VERSION ""

NS_ :

BS_:

BU_: TBOX GW

BO_ 945 TBOX_0x3B1: 8 TBOX
 SG_ TBOX_YawAngvelocity : 7|16@0+ (1,0) [0|65535] "度/秒" GW
 SG_ TBOX_PitchAngvelocity : 23|16@0+ (1,0) [0|65535] "度/秒" GW
 SG_ TBOX_RollAngvelocity : 39|16@0+ (1,0) [0|65535] "度/秒" GW

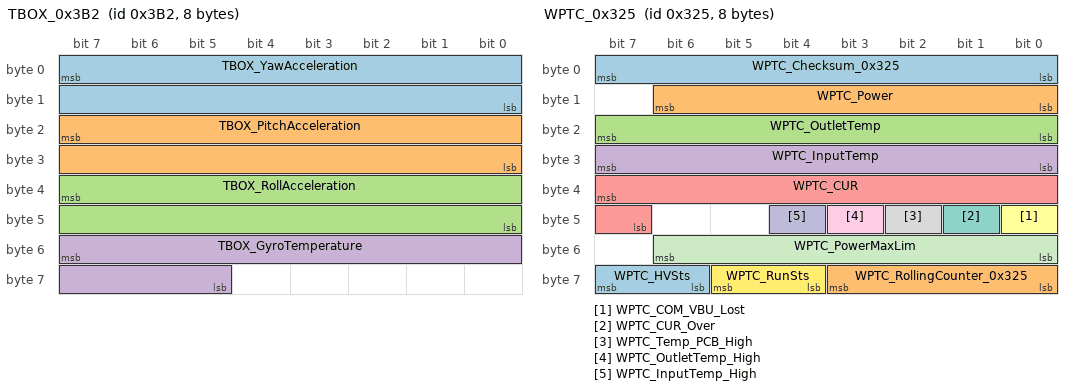
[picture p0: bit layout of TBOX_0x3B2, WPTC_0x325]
BO_ 946 TBOX_0x3B2: 8 TBOX
 SG_ TBOX_YawAcceleration : 7|16@0+ (1,0) [0|65535] "g" GW
 SG_ TBOX_PitchAcceleration : 23|16@0+ (1,0) [0|65535] "g" GW
 SG_ TBOX_RollAcceleration : 39|16@0+ (1,0) [0|65535] "g" GW
 SG_ TBOX_GyroTemperature : 55|11@0+ (0.1,-75) [-75|125] "℃" GW

BO_ 1378 MCU_0x562: 8 GW
 SG_ MCU_MotorSts_GBT : 7|8@0+ (1,0) [0|255] "" TBOX
 SG_ MCU_MotoroffsetCalReq : 34|1@0+ (1,0) [0|1] "" TBOX

BO_ 805 WPTC_0x325: 8 GW
 SG_ WPTC_Checksum_0x325 : 7|8@0+ (1,0) [0|255] "" TBOX
 SG_ WPTC_Power : 14|7@0+ (0.1,0) [0|12.7] "KW" TBOX
 SG_ WPTC_OutletTemp : 23|8@0+ (1,-40) [-40|215] "℃" TBOX
 SG_ WPTC_InputTemp : 31|8@0+ (1,-40) [-40|215] "℃" TBOX
 SG_ WPTC_CUR : 39|9@0+ (0.1,0) [0|40] "" TBOX
 SG_ WPTC_COM_VBU_Lost : 40|1@0+ (1,0) [0|1] "" TBOX
 SG_ WPTC_CUR_Over : 41|1@0+ (1,0) [0|1] "" TBOX
 SG_ WPTC_Temp_PCB_High : 42|1@0+ (1,0) [0|1] "" TBOX
 SG_ WPTC_OutletTemp_High : 43|1@0+ (1,0) [0|1] "" TBOX
 SG_ WPTC_InputTemp_High : 44|1@0+ (1,0) [0|1] "" TBOX
 SG_ WPTC_PowerMaxLim : 54|7@0+ (0.1,0) [0|12.7] "KW" TBOX
 SG_ WPTC_RunSts : 61|2@0+ (1,0) [0|3] "" TBOX
 SG_ WPTC_HVSts : 63|2@0+ (1,0) [0|3] "" TBOX
 SG_ WPTC_RollingCounter_0x325 : 59|4@0+ (1,0) [0|15] "" TBOX

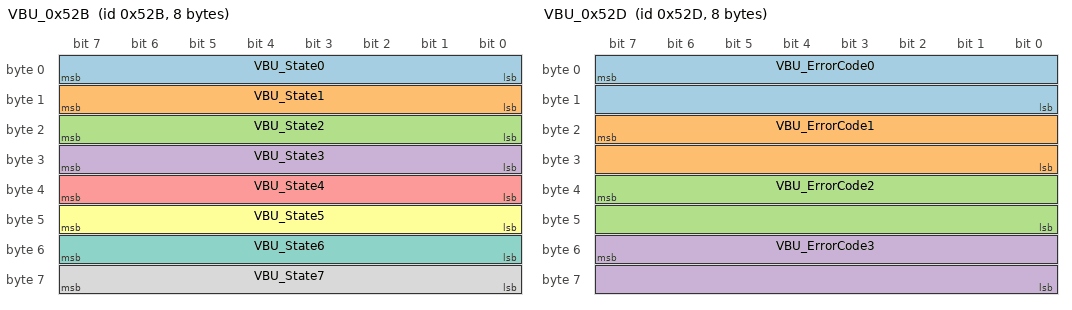
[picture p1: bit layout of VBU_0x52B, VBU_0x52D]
BO_ 1323 VBU_0x52B: 8 GW
 SG_ VBU_State0 : 7|8@0+ (1,0) [0|255] "" TBOX
 SG_ VBU_State1 : 15|8@0+ (1,0) [0|255] "" TBOX
 SG_ VBU_State2 : 23|8@0+ (1,0) [0|255] "" TBOX
 SG_ VBU_State3 : 31|8@0+ (1,0) [0|255] "" TBOX
 SG_ VBU_State4 : 39|8@0+ (1,0) [0|255] "" TBOX
 SG_ VBU_State5 : 47|8@0+ (1,0) [0|255] "" TBOX
 SG_ VBU_State6 : 55|8@0+ (1,0) [0|255] "" TBOX
 SG_ VBU_State7 : 63|8@0+ (1,0) [0|255] "" TBOX

BO_ 1325 VBU_0x52D: 8 GW
 SG_ VBU_ErrorCode0 : 7|16@0+ (1,0) [0|65536] "" TBOX
 SG_ VBU_ErrorCode1 : 23|16@0+ (1,0) [0|65536] "" TBOX
 SG_ VBU_ErrorCode2 : 39|16@0+ (1,0) [0|65536] "" TBOX
 SG_ VBU_ErrorCode3 : 55|16@0+ (1,0) [0|65536] "" TBOX

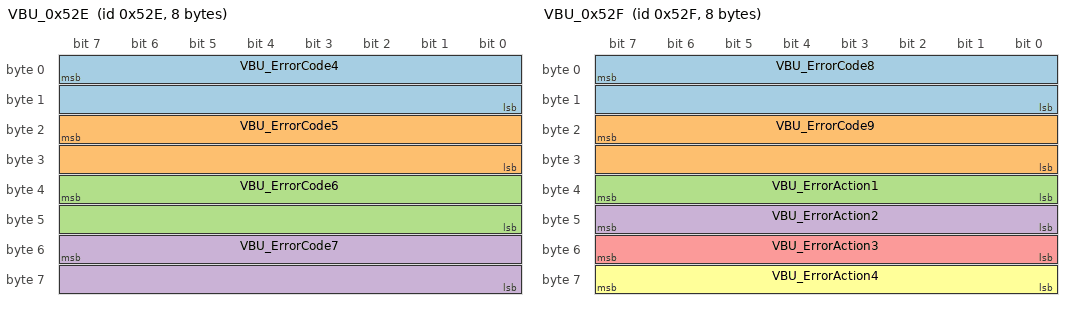
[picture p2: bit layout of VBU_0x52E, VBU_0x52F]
BO_ 1326 VBU_0x52E: 8 GW
 SG_ VBU_ErrorCode4 : 7|16@0+ (1,0) [0|65536] "" TBOX
 SG_ VBU_ErrorCode5 : 23|16@0+ (1,0) [0|65536] "" TBOX
 SG_ VBU_ErrorCode6 : 39|16@0+ (1,0) [0|65536] "" TBOX
 SG_ VBU_ErrorCode7 : 55|16@0+ (1,0) [0|65536] "" TBOX

BO_ 1327 VBU_0x52F: 8 GW
 SG_ VBU_ErrorCode8 : 7|16@0+ (1,0) [0|65536] "" TBOX
 SG_ VBU_ErrorCode9 : 23|16@0+ (1,0) [0|65536] "" TBOX
 SG_ VBU_ErrorAction1 : 39|8@0+ (1,0) [0|255] "" TBOX
 SG_ VBU_ErrorAction2 : 47|8@0+ (1,0) [0|255] "" TBOX
 SG_ VBU_ErrorAction3 : 55|8@0+ (1,0) [0|255] "" TBOX
 SG_ VBU_ErrorAction4 : 63|8@0+ (1,0) [0|255] "" TBOX

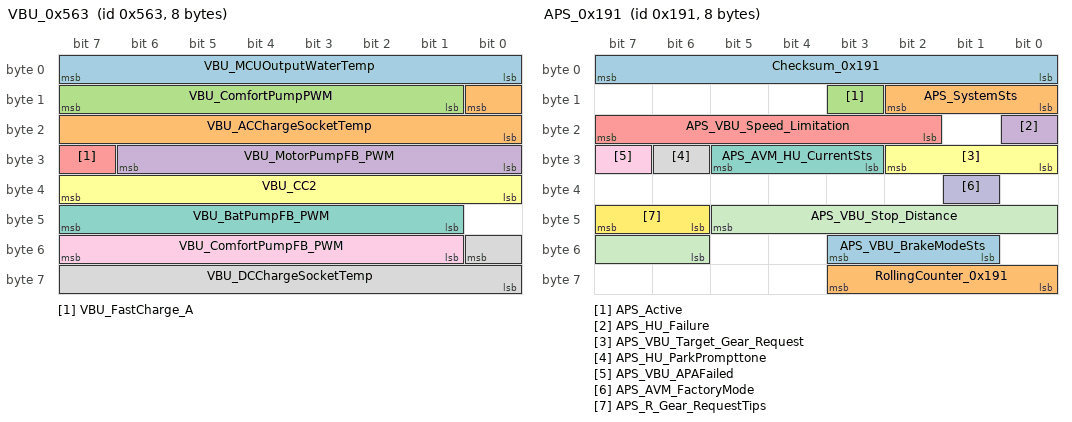
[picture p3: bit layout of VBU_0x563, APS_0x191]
BO_ 1379 VBU_0x563: 8 GW
 SG_ VBU_MCUOutputWaterTemp : 7|8@0+ (1,-40) [-40|215] "" TBOX
 SG_ VBU_ACChargeSocketTemp : 8|9@0+ (1,-40) [-40|300] "degC" TBOX
 SG_ VBU_ComfortPumpPWM : 15|7@0+ (1,0) [0|100] "%" TBOX
 SG_ VBU_MotorPumpFB_PWM : 30|7@0+ (1,0) [0|100] "%" TBOX
 SG_ VBU_FastCharge_A : 31|1@0+ (1,0) [0|1] "" TBOX
 SG_ VBU_CC2 : 39|8@0+ (0.1,0) [0|25.4] "V" TBOX
 SG_ VBU_BatPumpFB_PWM : 47|7@0+ (1,0) [0|100] "%" TBOX
 SG_ VBU_DCChargeSocketTemp : 48|9@0+ (1,-40) [-40|300] "degC" TBOX
 SG_ VBU_ComfortPumpFB_PWM : 55|7@0+ (1,0) [0|100] "%" TBOX

BO_ 401 APS_0x191: 8 GW
 SG_ Checksum_0x191 : 7|8@0+ (1,0) [0|255] "" TBOX
 SG_ APS_SystemSts : 10|3@0+ (1,0) [0|7] "" TBOX
 SG_ APS_Active : 11|1@0+ (1,0) [0|1] "" TBOX
 SG_ APS_HU_Failure : 16|1@0+ (1,0) [0|1] "" TBOX
 SG_ APS_VBU_Speed_Limitation : 23|6@0+ (0.8,0) [0|5] "kmph" TBOX
 SG_ APS_VBU_Target_Gear_Request : 26|3@0+ (1,0) [0|7] "" TBOX
 SG_ APS_AVM_HU_CurrentSts : 29|3@0+ (1,0) [0|7] "" TBOX
 SG_ APS_HU_ParkPrompttone : 30|1@0+ (1,0) [0|1] "" TBOX
 SG_ APS_VBU_APAFailed : 31|1@0+ (1,0) [0|1] "" TBOX
 SG_ APS_AVM_FactoryMode : 33|1@0+ (1,0) [0|1] "" TBOX
 SG_ APS_VBU_Stop_Distance : 45|8@0+ (1,0) [0|255] "" TBOX
 SG_ APS_R_Gear_RequestTips : 47|2@0+ (1,0) [0|3] "" TBOX
 SG_ APS_VBU_BrakeModeSts : 51|3@0+ (1,0) [0|7] "" TBOX
 SG_ RollingCounter_0x191 : 59|4@0+ (1,0) [0|15] "" TBOX

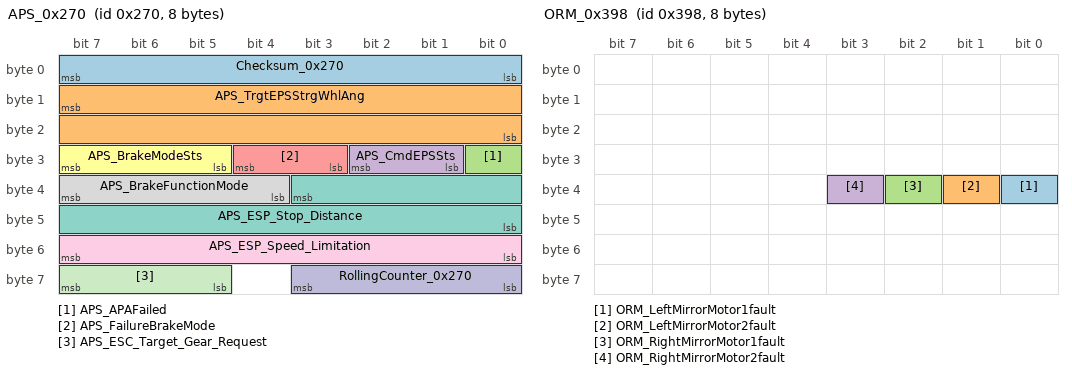
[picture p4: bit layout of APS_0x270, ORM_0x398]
BO_ 624 APS_0x270: 8 GW
 SG_ Checksum_0x270 : 7|8@0+ (1,0) [0|255] "" TBOX
 SG_ APS_TrgtEPSStrgWhlAng : 15|16@0+ (0.0238,-780) [-780|779.733] "deg" TBOX
 SG_ APS_APAFailed : 24|1@0+ (1,0) [0|1] "" TBOX
 SG_ APS_CmdEPSSts : 26|2@0+ (1,0) [0|3] "" TBOX
 SG_ APS_FailureBrakeMode : 28|2@0+ (1,0) [0|3] "" TBOX
 SG_ APS_BrakeModeSts : 31|3@0+ (1,0) [0|7] "" TBOX
 SG_ APS_ESP_Stop_Distance : 35|12@0+ (1,0) [0|4095] "cm" TBOX
 SG_ APS_BrakeFunctionMode : 39|4@0+ (1,0) [0|15] "" TBOX
 SG_ APS_ESP_Speed_Limitation : 55|8@0+ (0.1,0) [0|10] "Km/h" TBOX
 SG_ RollingCounter_0x270 : 59|4@0+ (1,0) [0|15] "" TBOX
 SG_ APS_ESC_Target_Gear_Request : 63|3@0+ (1,0) [0|7] "" TBOX

BO_ 625 APS_0x271: 8 GW
 SG_ Checksum_0x271 : 7|8@0+ (1,0) [0|255] "" TBOX
 SG_ APS_APS_AutoSearchSts : 10|3@0+ (1,0) [0|7] "" TBOX
 SG_ APS_APS_ParkOutChkResult : 11|1@0+ (1,0) [0|1] "" TBOX
 SG_ APS_APS_CurrentPathNum : 15|4@0+ (1,0) [0|15] "" TBOX
 SG_ APS_APS_TotalPathNum : 19|4@0+ (1,0) [0|15] "" TBOX
 SG_ APS_APS_SuspendedReason : 22|3@0+ (1,0) [0|7] "" TBOX
 SG_ APS_APS_AbortReason : 28|5@0+ (1,0) [0|31] "" TBOX
 SG_ APS_APS_CurrentParkType : 31|3@0+ (1,0) [0|7] "" TBOX
 SG_ APS_APS_OverrideReason : 34|3@0+ (1,0) [0|7] "" TBOX
 SG_ APS_APS_VehicleDirection : 36|2@0+ (1,0) [0|3] "" TBOX
 SG_ APS_APS_TerminatedType : 38|2@0+ (1,0) [0|3] "" TBOX
 SG_ APS_RemoteParkIn_Status : 46|3@0+ (1,0) [0|7] "" TBOX
 SG_ APS_BCM_RemoteParkIn_Status : 48|1@0+ (1,0) [0|1] "" TBOX
 SG_ APS_BCM_DoubleFlash : 49|1@0+ (1,0) [0|1] "" TBOX
 SG_ APS_BCM_AllDoorUnLock_Door : 50|1@0+ (1,0) [0|1] "" TBOX
 SG_ APS_BCM_PowerOffReq : 52|1@0+ (1,0) [0|1] "" TBOX
 SG_ RollingCounter_0x271 : 59|4@0+ (1,0) [0|15] "" TBOX
 SG_ APS_ParkDirection : 61|2@0+ (1,0) [0|3] "" TBOX
 SG_ APS_APP_RPA_Status : 63|2@0+ (1,0) [0|3] "" TBOX

BO_ 920 ORM_0x398: 8 GW
 SG_ ORM_LeftMirrorMotor1fault : 32|1@0+ (1,0) [0|1] "" TBOX
 SG_ ORM_LeftMirrorMotor2fault : 33|1@0+ (1,0) [0|1] "" TBOX
 SG_ ORM_RightMirrorMotor1fault : 34|1@0+ (1,0) [0|1] "" TBOX
 SG_ ORM_RightMirrorMotor2fault : 35|1@0+ (1,0) [0|1] "" TBOX

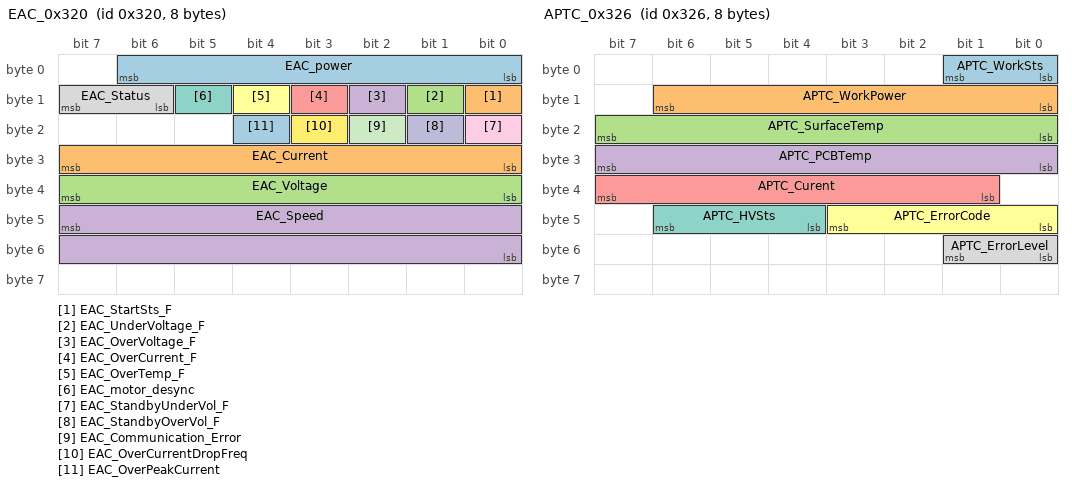
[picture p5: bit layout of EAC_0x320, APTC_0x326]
BO_ 800 EAC_0x320: 8 GW
 SG_ EAC_power : 6|7@0+ (0.1,0) [0|12.7] "KW" TBOX
 SG_ EAC_StartSts_F : 8|1@0+ (1,0) [0|1] "" TBOX
 SG_ EAC_UnderVoltage_F : 9|1@0+ (1,0) [0|1] "" TBOX
 SG_ EAC_OverVoltage_F : 10|1@0+ (1,0) [0|1] "" TBOX
 SG_ EAC_OverCurrent_F : 11|1@0+ (1,0) [0|1] "" TBOX
 SG_ EAC_OverTemp_F : 12|1@0+ (1,0) [0|1] "" TBOX
 SG_ EAC_motor_desync : 13|1@0+ (1,0) [0|1] "" TBOX
 SG_ EAC_Status : 15|2@0+ (1,0) [0|3] "" TBOX
 SG_ EAC_StandbyUnderVol_F : 16|1@0+ (1,0) [0|1] "" TBOX
 SG_ EAC_StandbyOverVol_F : 17|1@0+ (1,0) [0|1] "" TBOX
 SG_ EAC_Communication_Error : 18|1@0+ (1,0) [0|1] "" TBOX
 SG_ EAC_OverCurrentDropFreq : 19|1@0+ (1,0) [0|1] "" TBOX
 SG_ EAC_OverPeakCurrent : 20|1@0+ (1,0) [0|1] "" TBOX
 SG_ EAC_Current : 31|8@0+ (0.1,0) [0|25.4] "A" TBOX
 SG_ EAC_Voltage : 39|8@0+ (4,0) [0|1016] "V" TBOX
 SG_ EAC_Speed : 47|16@0+ (1,0) [0|65534] "RPM" TBOX

BO_ 806 APTC_0x326: 8 GW
 SG_ APTC_WorkSts : 1|2@0+ (1,0) [0|3] "" TBOX
 SG_ APTC_WorkPower : 14|7@0+ (0.1,0) [0|12.7] "KW" TBOX
 SG_ APTC_SurfaceTemp : 23|8@0+ (1,-40) [-40|215] "" TBOX
 SG_ APTC_PCBTemp : 31|8@0+ (1,-40) [-40|215] "" TBOX
 SG_ APTC_Curent : 39|7@0+ (0.2,0) [0|25] "" TBOX
 SG_ APTC_ErrorCode : 43|4@0+ (1,0) [0|15] "" TBOX
 SG_ APTC_HVSts : 46|3@0+ (1,0) [0|7] "" TBOX
 SG_ APTC_ErrorLevel : 49|2@0+ (1,0) [0|3] "" TBOX

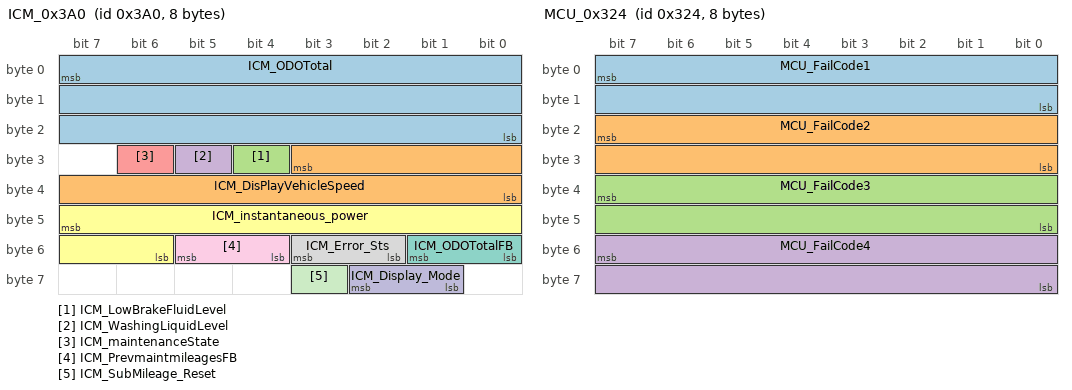
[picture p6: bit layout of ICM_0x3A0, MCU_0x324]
BO_ 928 ICM_0x3A0: 8 GW
 SG_ ICM_ODOTotal : 7|24@0+ (1,0) [0|999999] "KM" TBOX
 SG_ ICM_DisPlayVehicleSpeed : 27|12@0+ (0.05625,0) [0|230.28749] "kph" TBOX
 SG_ ICM_LowBrakeFluidLevel : 28|1@0+ (1,0) [0|1] "" TBOX
 SG_ ICM_WashingLiquidLevel : 29|1@0+ (1,0) [0|1] "" TBOX
 SG_ ICM_maintenanceState : 30|1@0+ (1,0) [0|1] "" TBOX
 SG_ ICM_instantaneous_power : 47|10@0+ (1,-400) [-400|400] "" TBOX
 SG_ ICM_ODOTotalFB : 49|2@0+ (1,0) [0|3] "" TBOX
 SG_ ICM_Error_Sts : 51|2@0+ (1,0) [0|3] "" TBOX
 SG_ ICM_PrevmaintmileagesFB : 53|2@0+ (1,0) [0|3] "" TBOX
 SG_ ICM_Display_Mode : 58|2@0+ (1,0) [0|3] "" TBOX
 SG_ ICM_SubMileage_Reset : 59|1@0+ (1,0) [0|1] "" TBOX

BO_ 896 BCM_0x380_LIN1: 8 GW
 SG_ RLS_RQ_LowBeam : 55|2@0+ (1,0) [0|3] "" TBOX
 SG_ RB_Hall_error : 16|1@0+ (1,0) [0|1] "" TBOX
 SG_ RB_Relay_error : 17|1@0+ (1,0) [0|1] "" TBOX
 SG_ RB_ResponseError : 18|1@0+ (1,0) [0|1] "" TBOX
 SG_ RB_RunningStatus : 20|2@0+ (1,0) [0|3] "" TBOX
 SG_ RB_Initialization_Status : 22|2@0+ (1,0) [0|1] "" TBOX
 SG_ RLS_Fault_Rain : 23|1@0+ (1,0) [0|1] "" TBOX
 SG_ RB_Position : 30|7@0+ (1,0) [0|127] "" TBOX
 SG_ RLS_Brightness_FW : 33|10@0+ (6,0) [0|6126] "LUX" TBOX
 SG_ RLS_Fault_Light : 34|1@0+ (1,0) [0|1] "" TBOX
 SG_ RLS_ResponseError : 35|1@0+ (1,0) [0|1] "" TBOX
 SG_ RLS_Rain_Intensity : 39|4@0+ (10,0) [0|100] "%" TBOX
 SG_ RB_Reversiering : 48|1@0+ (1,0) [0|1] "" TBOX
 SG_ RB_Thermalprotection : 49|1@0+ (1,0) [0|1] "" TBOX
 SG_ RB_UBat_LowVoltage : 50|1@0+ (1,0) [0|1] "" TBOX
 SG_ RB_UBat_OverVoltage : 51|1@0+ (1,0) [0|1] "" TBOX
 SG_ RB_OpenKey_Status : 52|1@0+ (1,0) [0|1] "" TBOX
 SG_ RB_CloseKey_Status : 53|1@0+ (1,0) [0|1] "" TBOX

BO_ 784 BCM_0x310: 8 GW
 SG_ BCM_SystemPowerMode : 1|2@0+ (1,0) [0|3] "" TBOX
 SG_ BCM_AntiThelf_Sts : 3|2@0+ (1,0) [0|3] "" TBOX
 SG_ BCM_DriverLock_Sts : 5|2@0+ (1,0) [0|3] "" TBOX
 SG_ BCM_StartRequest : 6|1@0+ (1,0) [0|1] "" TBOX
 SG_ BCM_partialarmed_ActiveSts : 7|1@0+ (1,0) [0|1] "" TBOX
 SG_ BCM_Hood_Sts : 9|2@0+ (1,0) [0|3] "" TBOX
 SG_ BCM_ChargerLock_ControlSts : 10|1@0+ (1,0) [0|1] "" TBOX
 SG_ BCM_PositionLight_Sts : 11|1@0+ (1,0) [0|1] "" TBOX
 SG_ BCM_TurnLeftLight_Sts : 12|1@0+ (1,0) [0|1] "" TBOX
 SG_ BCM_TurnRightLight_Sts : 13|1@0+ (1,0) [0|1] "" TBOX
 SG_ BCM_Daylight_Sts : 14|1@0+ (1,0) [0|1] "" TBOX
 SG_ BCM_HighBeam_Sts : 15|1@0+ (1,0) [0|1] "" TBOX
 SG_ BCM_LowBeam_Sts : 16|1@0+ (1,0) [0|1] "" TBOX
 SG_ BCM_AutoHeadlight_Sts : 17|1@0+ (1,0) [0|1] "" TBOX
 SG_ BCM_brakeLight_Sts : 18|1@0+ (1,0) [0|1] "" TBOX
 SG_ BCM_HazardLight_Sts : 19|1@0+ (1,0) [0|1] "" TBOX
 SG_ BCM_RearFoglight_Sts : 20|1@0+ (1,0) [0|1] "" TBOX
 SG_ BCM_BrkSw_Sts : 22|2@0+ (1,0) [0|3] "" TBOX
 SG_ BCM_FL_Door_Sts : 25|2@0+ (1,0) [0|3] "" TBOX
 SG_ BCM_FR_Door_Sts : 27|2@0+ (1,0) [0|3] "" TBOX
 SG_ BCM_RL_Door_Sts : 29|2@0+ (1,0) [0|3] "" TBOX
 SG_ BCM_RR_Door_Sts : 31|2@0+ (1,0) [0|3] "" TBOX
 SG_ BCM_Trunk_Door_Sts : 33|2@0+ (1,0) [0|3] "" TBOX
 SG_ BCM_PLGOutsideSW : 34|1@0+ (1,0) [0|1] "" TBOX
 SG_ BCM_HornControlsts : 35|1@0+ (1,0) [0|1] "" TBOX
 SG_ BCM_Fwiper_Mist_Sts : 36|1@0+ (1,0) [0|1] "" TBOX
 SG_ BCM_Fwiper_washing_Sts : 37|1@0+ (1,0) [0|1] "" TBOX
 SG_ BCM_FWiper_Sts : 42|3@0+ (1,0) [0|7] "" TBOX
 SG_ BCM_RWiper_Sts : 44|2@0+ (1,0) [0|3] "" TBOX
 SG_ BCM_RearViewFoldSts : 45|1@0+ (1,0) [0|1] "" TBOX
 SG_ BCM_RearViewAutoSWSts : 46|1@0+ (1,0) [0|1] "" TBOX
 SG_ BCM_RearViewHeatSts : 47|1@0+ (1,0) [0|1] "" TBOX
 SG_ BCM_WorkMode : 49|2@0+ (1,0) [0|3] "" TBOX
 SG_ BCM_TBOXUnlockEnableSts : 50|1@0+ (1,0) [0|1] "" TBOX
 SG_ BCM_FwiperServiceSWsts : 51|1@0+ (1,0) [0|1] "" TBOX
 SG_ BCM_SupplyVoltage : 63|8@0+ (0.1,0) [0|25.4] "" TBOX
 SG_ BCM_PowerONorOFF_Reason : 55|4@0+ (1,0) [0|15] "" TBOX

BO_ 665 BCM_0x299_LIN2_3: 8 GW
 SG_ FLWM_DenormalizeSt : 0|1@0+ (1,0) [0|1] "" TBOX
 SG_ FRWM_DenormalizeSt : 1|1@0+ (1,0) [0|1] "" TBOX
 SG_ RLWM_DenormalizeSt : 2|1@0+ (1,0) [0|1] "" TBOX
 SG_ RRWM_DenormalizeSt : 3|1@0+ (1,0) [0|1] "" TBOX
 SG_ CSW_Key_LiftGate : 5|2@0+ (1,0) [0|3] "" TBOX
 SG_ CSW_WindowLOCK : 7|2@0+ (1,0) [0|3] "" TBOX
 SG_ CSW_Key_FrontDefrost : 9|2@0+ (1,0) [0|3] "" TBOX
 SG_ RLWM_WindowLOCKSts : 10|1@0+ (1,0) [0|1] "" TBOX
 SG_ RRWM_WindowLOCKSts : 11|1@0+ (1,0) [0|1] "" TBOX
 SG_ ESCL_DiagError : 12|1@0+ (1,0) [0|1] "" TBOX
 SG_ ESCL_authentification_error : 13|1@0+ (1,0) [0|1] "" TBOX
 SG_ ESCL_unlock_status : 14|1@0+ (1,0) [0|1] "" TBOX
 SG_ ESCL_lock_status : 15|1@0+ (1,0) [0|1] "" TBOX
 SG_ FLWM_WinPstSt : 22|7@0+ (1,0) [0|100] "" TBOX
 SG_ FLWM_AntiPinchDetecte : 23|1@0+ (1,0) [0|1] "" TBOX
 SG_ FRWM_WinPstSt : 30|7@0+ (1,0) [0|100] "" TBOX
 SG_ FRWM_AntiPinchDetecte : 31|1@0+ (1,0) [0|1] "" TBOX
 SG_ RLWM_WinPstSt : 38|7@0+ (1,0) [0|100] "" TBOX
 SG_ RLWM_AntiPinchDetecte : 39|1@0+ (1,0) [0|1] "" TBOX
 SG_ RRWM_WinPstSt : 46|7@0+ (1,0) [0|100] "" TBOX
 SG_ RRWM_AntiPinchDetecte : 47|1@0+ (1,0) [0|1] "" TBOX
 SG_ FLWM_Opend : 48|1@0+ (1,0) [0|1] "" TBOX
 SG_ FLWM_Closed : 49|1@0+ (1,0) [0|1] "" TBOX
 SG_ FRWM_Opend : 50|1@0+ (1,0) [0|1] "" TBOX
 SG_ FRWM_Closed : 51|1@0+ (1,0) [0|1] "" TBOX
 SG_ RLWM_Opend : 52|1@0+ (1,0) [0|1] "" TBOX
 SG_ RLWM_Closed : 53|1@0+ (1,0) [0|1] "" TBOX
 SG_ RRWM_Opend : 54|1@0+ (1,0) [0|1] "" TBOX
 SG_ RRWM_Closed : 55|1@0+ (1,0) [0|1] "" TBOX
 SG_ FLWM_WinMoveSt : 57|2@0+ (1,0) [0|3] "" TBOX
 SG_ FRWM_WinMoveSt : 59|2@0+ (1,0) [0|3] "" TBOX
 SG_ RLWM_WinMoveSt : 61|2@0+ (1,0) [0|3] "" TBOX
 SG_ RRWM_WinMoveSt : 63|2@0+ (1,0) [0|3] "" TBOX

BO_ 583 BCM_0x247: 8 GW
 SG_ BCM_StartWarning : 2|3@0+ (1,0) [0|7] "" TBOX
 SG_ BCM_PowerOffWarning : 6|3@0+ (1,0) [0|7] "" TBOX
 SG_ BCM_PowerONWarning : 10|3@0+ (1,0) [0|7] "" TBOX
 SG_ BCM_AuthSts : 14|2@0+ (1,0) [0|3] "" TBOX
 SG_ BCM_ESCLSysFail : 19|2@0+ (1,0) [0|3] "" TBOX
 SG_ BCM_LODO_Reminder : 23|2@0+ (1,0) [0|3] "" TBOX
 SG_ BCM_brakeLightfail : 25|2@0+ (1,0) [0|3] "" TBOX
 SG_ BCM_HoodOpen_Feedback : 31|1@0+ (1,0) [0|1] "" TBOX
 SG_ BCM_TrunkOpen_Feedback : 30|1@0+ (1,0) [0|1] "" TBOX
 SG_ BCM_Drivedoorlcok_Feedback : 29|1@0+ (1,0) [0|1] "" TBOX
 SG_ BCM_FLDoorOpen_Feedback : 39|1@0+ (1,0) [0|1] "" TBOX
 SG_ BCM_FRDoorOpen_Feedback : 38|1@0+ (1,0) [0|1] "" TBOX
 SG_ BCM_RRDoorOpen_Feedback : 37|1@0+ (1,0) [0|1] "" TBOX
 SG_ BCM_RLDoorOpen_Feedback : 36|1@0+ (1,0) [0|1] "" TBOX
 SG_ BCM_FLWindowOpen_Feedback : 35|1@0+ (1,0) [0|1] "" TBOX
 SG_ BCM_FRWindowOpen_Feedback : 34|1@0+ (1,0) [0|1] "" TBOX
 SG_ BCM_RRWindowOpen_Feedback : 33|1@0+ (1,0) [0|1] "" TBOX
 SG_ BCM_RLWindowOpen_Feedback : 32|1@0+ (1,0) [0|1] "" TBOX

BO_ 1282 BCM_TPMS_0x502: 8 GW
 SG_ TPMS_FL_Warning_Sts : 0|1@0+ (1,0) [0|1] "" TBOX
 SG_ TPMS_FR_Warning_Sts : 1|1@0+ (1,0) [0|1] "" TBOX
 SG_ TPMS_RL_Warning_Sts : 2|1@0+ (1,0) [0|1] "" TBOX
 SG_ TPMS_RR_Warning_Sts : 3|1@0+ (1,0) [0|1] "" TBOX
 SG_ TPMS_FL_Fault_Sts : 4|1@0+ (1,0) [0|1] "" TBOX
 SG_ TPMS_FR_Fault_Sts : 5|1@0+ (1,0) [0|1] "" TBOX
 SG_ TPMS_RL_Fault_Sts : 6|1@0+ (1,0) [0|1] "" TBOX
 SG_ TPMS_RR_Fault_Sts : 7|1@0+ (1,0) [0|1] "" TBOX
 SG_ TPMS_FL_leakage_Sts : 8|1@0+ (1,0) [0|1] "" TBOX
 SG_ TPMS_FR_leakage_Sts : 9|1@0+ (1,0) [0|1] "" TBOX
 SG_ TPMS_RL_leakage_Sts : 10|1@0+ (1,0) [0|1] "" TBOX
 SG_ TPMS_RR_leakage_Sts : 11|1@0+ (1,0) [0|1] "" TBOX
 SG_ TPMS_FLPressure_Sts : 13|2@0+ (1,0) [0|3] "" TBOX
 SG_ TPMS_FRPressure_Sts : 15|2@0+ (1,0) [0|3] "" TBOX
 SG_ TPMS_RLPressure_Sts : 17|2@0+ (1,0) [0|3] "" TBOX
 SG_ TPMS_RRPressure_Sts : 19|2@0+ (1,0) [0|3] "" TBOX
 SG_ TPMS_FL_HighTemp_Sts : 20|1@0+ (1,0) [0|1] "" TBOX
 SG_ TPMS_FR_HighTemp_Sts : 21|1@0+ (1,0) [0|1] "" TBOX
 SG_ TPMS_RL_HighTemp_Sts : 22|1@0+ (1,0) [0|1] "" TBOX
 SG_ TPMS_RR_HighTemp_Sts : 23|1@0+ (1,0) [0|1] "" TBOX
 SG_ TPMS_FL_battery_Sts : 24|1@0+ (1,0) [0|1] "" TBOX
 SG_ TPMS_FR_battery_Sts : 25|1@0+ (1,0) [0|1] "" TBOX
 SG_ TPMS_RL_battery_Sts : 26|1@0+ (1,0) [0|1] "" TBOX
 SG_ TPMS_RR_battery_Sts : 27|1@0+ (1,0) [0|1] "" TBOX
 SG_ TPMS_FL_SensorError_Sts : 28|1@0+ (1,0) [0|1] "" TBOX
 SG_ TPMS_FR_SensorError_Sts : 29|1@0+ (1,0) [0|1] "" TBOX
 SG_ TPMS_RL_SensorError_Sts : 30|1@0+ (1,0) [0|1] "" TBOX
 SG_ TPMS_RR_SensorError_Sts : 31|1@0+ (1,0) [0|1] "" TBOX
 SG_ TPMS_FL_failure_Sts : 32|1@0+ (1,0) [0|1] "" TBOX
 SG_ TPMS_FR_failure_Sts : 33|1@0+ (1,0) [0|1] "" TBOX
 SG_ TPMS_RL_failure_Sts : 34|1@0+ (1,0) [0|1] "" TBOX
 SG_ TPMS_RR_failure_Sts : 35|1@0+ (1,0) [0|1] "" TBOX
 SG_ TPMS_FL_learn_Sts : 41|2@0+ (1,0) [0|3] "" TBOX
 SG_ TPMS_FR_learn_Sts : 43|2@0+ (1,0) [0|3] "" TBOX
 SG_ TPMS_RL_learn_Sts : 45|2@0+ (1,0) [0|3] "" TBOX
 SG_ TPMS_RR_learn_Sts : 47|2@0+ (1,0) [0|3] "" TBOX
 SG_ TPMS_FL_CRC_Error : 48|1@0+ (1,0) [0|1] "" TBOX
 SG_ TPMS_FR_CRC_Error : 49|1@0+ (1,0) [0|1] "" TBOX
 SG_ TPMS_RL_CRC_Error : 50|1@0+ (1,0) [0|1] "" TBOX
 SG_ TPMS_RR_CRC_Error : 52|1@0+ (1,0) [0|1] "" TBOX

BO_ 804 MCU_0x324: 8 GW
 SG_ MCU_FailCode1 : 7|16@0+ (1,0) [0|65535] "" TBOX
 SG_ MCU_FailCode2 : 23|16@0+ (1,0) [0|65535] "" TBOX
 SG_ MCU_FailCode3 : 39|16@0+ (1,0) [0|65535] "" TBOX
 SG_ MCU_FailCode4 : 55|16@0+ (1,0) [0|65535] "" TBOX

BO_ 835 PLG_0x343: 8 GW
 SG_ PLG_Trunk_Sts : 2|3@0+ (1,0) [0|7] "" TBOX
 SG_ PLG_Shutface_SW : 3|1@0+ (1,0) [0|1] "" TBOX
 SG_ PLG_Latc_PawlSW : 4|1@0+ (1,0) [0|1] "" TBOX
 SG_ PLG_Latch_SecondarySW : 5|1@0+ (1,0) [0|1] "" TBOX
 SG_ PLG_Latch_0PositionSW : 6|1@0+ (1,0) [0|1] "" TBOX
 SG_ PLG_LearnedSts : 7|1@0+ (1,0) [0|1] "" TBOX
 SG_ PLG_KickActiveReq : 8|1@0+ (1,0) [0|1] "" TBOX
 SG_ PLG_HallSensor : 12|1@0+ (1,0) [0|1] "" TBOX
 SG_ PLG_OpenAng : 22|7@0+ (1,0) [0|100] "%" TBOX
 SG_ PLG_OpenAngValid : 23|1@0+ (1,0) [0|1] "" TBOX
 SG_ PLG_GaragePosition : 30|7@0+ (1,0) [0|100] "%" TBOX
 SG_ PLG_LatchMorSts : 33|2@0+ (1,0) [0|3] "" TBOX
 SG_ PLG_GearMor1Sts : 35|2@0+ (1,0) [0|3] "" TBOX
 SG_ PLG_GearMor2Sts : 37|2@0+ (1,0) [0|3] "" TBOX
 SG_ PLG_mode : 39|2@0+ (1,0) [0|3] "" TBOX
 SG_ PLG_TBOXUnlockEnableSts : 40|1@0+ (1,0) [0|1] "" TBOX
 SG_ PLG_Fault : 41|1@0+ (1,0) [0|1] "" TBOX
 SG_ PLG_FaultSts : 44|3@0+ (1,0) [0|7] "" TBOX

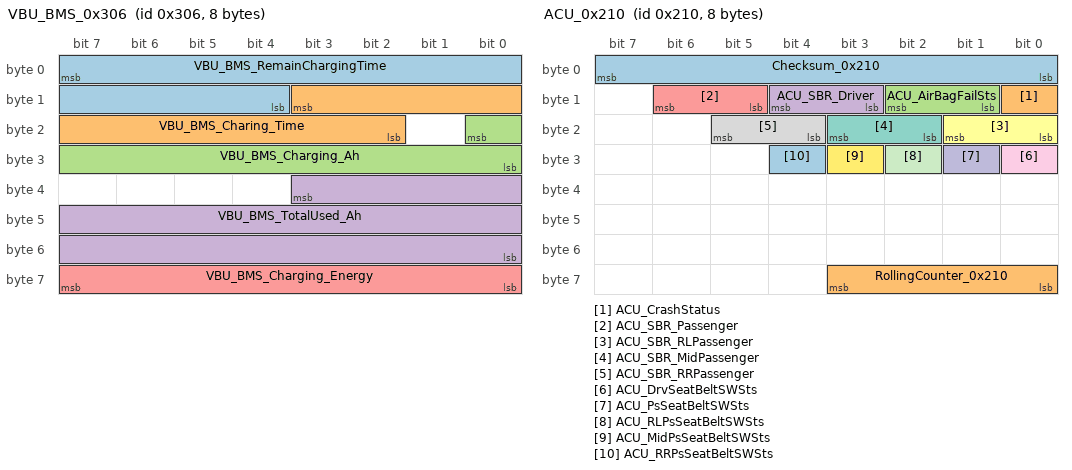
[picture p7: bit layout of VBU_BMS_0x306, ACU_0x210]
BO_ 774 VBU_BMS_0x306: 8 GW
 SG_ VBU_BMS_RemainChargingTime : 7|12@0+ (1,0) [0|2880] "min" TBOX
 SG_ VBU_BMS_Charing_Time : 11|10@0+ (1,0) [0|1000] "min" TBOX
 SG_ VBU_BMS_Charging_Ah : 16|9@0+ (0.5,0) [0|250] "Ah" TBOX
 SG_ VBU_BMS_TotalUsed_Ah : 35|20@0+ (1,0) [0|500000] "Ah" TBOX
 SG_ VBU_BMS_Charging_Energy : 63|8@0+ (0.5,0) [0|125] "kwh" TBOX

BO_ 528 ACU_0x210: 8 GW
 SG_ Checksum_0x210 : 7|8@0+ (1,0) [0|255] "" TBOX
 SG_ ACU_CrashStatus : 8|1@0+ (1,0) [0|1] "" TBOX
 SG_ ACU_AirBagFailSts : 10|2@0+ (1,0) [0|3] "" TBOX
 SG_ ACU_SBR_Driver : 12|2@0+ (1,0) [0|3] "" TBOX
 SG_ ACU_SBR_Passenger : 14|2@0+ (1,0) [0|3] "" TBOX
 SG_ ACU_SBR_RLPassenger : 17|2@0+ (1,0) [0|3] "" TBOX
 SG_ ACU_SBR_MidPassenger : 19|2@0+ (1,0) [0|3] "" TBOX
 SG_ ACU_SBR_RRPassenger : 21|2@0+ (1,0) [0|3] "" TBOX
 SG_ ACU_DrvSeatBeltSWSts : 24|1@0+ (1,0) [0|1] "" TBOX
 SG_ ACU_PsSeatBeltSWSts : 25|1@0+ (1,0) [0|1] "" TBOX
 SG_ ACU_RLPsSeatBeltSWSts : 26|1@0+ (1,0) [0|1] "" TBOX
 SG_ ACU_MidPsSeatBeltSWSts : 27|1@0+ (1,0) [0|1] "" TBOX
 SG_ ACU_RRPsSeatBeltSWSts : 28|1@0+ (1,0) [0|1] "" TBOX
 SG_ RollingCounter_0x210 : 59|4@0+ (1,0) [0|15] "" TBOX

BO_ 596 AC_0x254: 8 GW
 SG_ AC_SystemSts : 0|1@0+ (1,0) [0|1] "" TBOX
 SG_ AC_CycleSts : 1|1@0+ (1,0) [0|1] "" TBOX
 SG_ AC_EACSts : 2|1@0+ (1,0) [0|1] "" TBOX
 SG_ AC_AutoModeSts : 3|1@0+ (1,0) [0|1] "" TBOX
 SG_ AC_APTC_StartStop : 5|2@0+ (1,0) [0|3] "" TBOX
 SG_ AC_StartStopEAC : 7|2@0+ (1,0) [0|3] "" TBOX
 SG_ AC_EAC_AimSpeed : 15|16@0+ (1,0) [0|65534] "" TBOX
 SG_ AC_WindModeSts : 26|3@0+ (1,0) [0|7] "" TBOX
 SG_ AC_BlowingRateSts : 29|3@0+ (1,0) [0|7] "" TBOX
 SG_ AC_APTCSWsts : 30|1@0+ (1,0) [0|1] "" TBOX
 SG_ AC_SysFaultsts : 31|1@0+ (1,0) [0|1] "" TBOX
 SG_ AC_InTemperature : 39|8@0+ (0.5,-40) [-40|80] "℃" TBOX
 SG_ AC_OutTemperature : 47|8@0+ (0.5,-40) [-40|80] "℃" TBOX
 SG_ AC_PM25Value : 55|10@0+ (1,0) [0|1023] "μg/m3" TBOX
 SG_ AC_BatCoolingValve : 56|1@0+ (1,0) [0|1] "" TBOX
 SG_ AC_ComftCoolingValve : 57|1@0+ (1,0) [0|1] "" TBOX
 SG_ AC_FdefrostSts : 58|1@0+ (1,0) [0|1] "" TBOX

BO_ 1009 DVR_0x3F1: 8 GW
 SG_ DVR_Sdcard_Sts : 2|3@0+ (1,0) [0|7] "" TBOX
 SG_ DVR_DrivingRecord : 3|1@0+ (1,0) [0|1] "" TBOX
 SG_ DVR_VideoResolution : 5|2@0+ (1,0) [0|3] "" TBOX
 SG_ DVR_VideoTimeSts : 7|2@0+ (1,0) [0|3] "" TBOX
 SG_ DVR_ShutdownDelay : 9|2@0+ (1,0) [0|3] "" TBOX
 SG_ DVR_VideoCoverageSW : 10|1@0+ (1,0) [0|1] "" TBOX
 SG_ DVR_GSensorSensy : 12|2@0+ (1,0) [0|3] "" TBOX
 SG_ DVR_ParkMonitor : 13|1@0+ (1,0) [0|1] "" TBOX
 SG_ DVR_TapeSwitch : 14|1@0+ (1,0) [0|1] "" TBOX
 SG_ DVR_HDRSwitch : 15|1@0+ (1,0) [0|1] "" TBOX
 SG_ DVR_DriveInfoOverlay : 16|1@0+ (1,0) [0|1] "" TBOX
 SG_ DVR_SdcardFormateSts : 18|2@0+ (1,0) [0|3] "" TBOX
 SG_ DVR_FactoryDefaultSts : 20|2@0+ (1,0) [0|3] "" TBOX
 SG_ DVR_SystemSts : 21|1@0+ (1,0) [0|1] "" TBOX
 SG_ DVR_ControlResult : 23|2@0+ (1,0) [0|3] "" TBOX
 SG_ DVR_GsensorCrashStatus : 24|1@0+ (1,0) [0|1] "" TBOX
 SG_ DVR_requestWiFiopen : 25|1@0+ (1,0) [0|1] "" TBOX
 SG_ DVR_LocalTimelapseRecordResult : 57|2@0+ (1,0) [0|3] "" TBOX
 SG_ DVR_Frameinterval : 39|8@0+ (1,0) [0|255] "" TBOX
 SG_ DVR_FrameCount : 42|11@0+ (1,0) [0|2047] "" TBOX
 SG_ DVR_PlayRate : 47|5@0+ (1,0) [0|31] "" TBOX
 SG_ DVR_RemoteControlSts : 58|1@0+ (1,0) [0|1] "" TBOX

BO_ 676 DSM_0x2A4: 8 GW
 SG_ DSM_EasyEntrySWSts : 0|1@0+ (1,0) [0|1] "" TBOX
 SG_ DSM_DSMHeatSWsts : 1|1@0+ (1,0) [0|1] "" TBOX
 SG_ DSM_GetMemoryRsp_Mirror : 5|2@0+ (1,0) [0|3] "" TBOX
 SG_ DSM_GetMemoryRsp_Seat : 7|2@0+ (1,0) [0|3] "" TBOX
 SG_ DSM_SLV_DirectionSts : 13|2@0+ (1,0) [0|3] "" TBOX
 SG_ DSM_SHV_DirectionSts : 15|2@0+ (1,0) [0|3] "" TBOX
 SG_ DSM_LNV_DirectionSts : 17|2@0+ (1,0) [0|3] "" TBOX
 SG_ DSM_SLV_CalibrationSts : 19|2@0+ (1,0) [0|3] "" TBOX
 SG_ DSM_SHV_CalibrationSts : 21|2@0+ (1,0) [0|3] "" TBOX
 SG_ DSM_LNV_CalibrationSts : 23|2@0+ (1,0) [0|3] "" TBOX
 SG_ DSM_DSLV_MotorfaultSts : 24|1@0+ (1,0) [0|1] "" TBOX
 SG_ DSM_SLV_Position : 31|7@0+ (1,0) [0|100] "%" TBOX
 SG_ DSM_DSHV_MotorfaultSts : 32|1@0+ (1,0) [0|1] "" TBOX
 SG_ DSM_SHV_Position : 39|7@0+ (1,0) [0|100] "%" TBOX
 SG_ DSM_DSNV_MotorfaultSts : 40|1@0+ (1,0) [0|1] "" TBOX
 SG_ DSM_LNV_Position : 47|7@0+ (1,0) [0|100] "%" TBOX
 SG_ DSM_PSMHeatfault : 48|1@0+ (1,0) [0|1] "" TBOX
 SG_ DSM_PSMHeatSWsts : 49|1@0+ (1,0) [0|1] "" TBOX
 SG_ DSM_PSMheattemp : 55|6@0+ (1,0) [34|42] "℃" TBOX
 SG_ DSM_DSMHeatfault : 56|1@0+ (1,0) [0|1] "" TBOX
 SG_ DSM_DSMheattemp : 63|6@0+ (1,0) [34|42] "℃" TBOX

BO_ 24 BCM_AuthReq_0x18: 8 GW
 SG_ BCM_AuthReq_TBOX_NSM_Code : 7|64@0+ (1,0) [0|255] "" TBOX

BO_ 25 TBOX_AuthResp_0x19: 8 TBOX
 SG_ TBOX_AuthResp_BCM_Code : 7|64@0+ (1,0) [0|255] "" GW

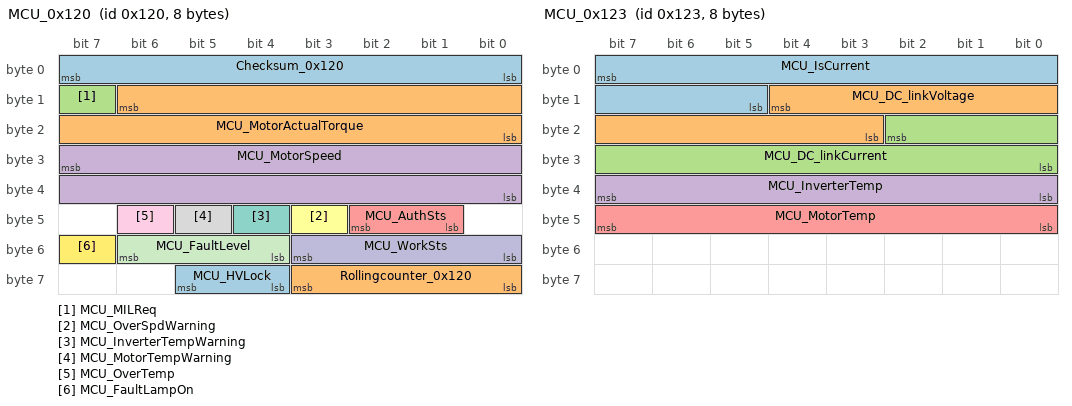
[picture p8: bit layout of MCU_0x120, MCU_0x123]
BO_ 288 MCU_0x120: 8 GW
 SG_ Checksum_0x120 : 7|8@0+ (1,0) [0|255] "" TBOX
 SG_ MCU_MotorActualTorque : 14|15@0+ (0.1,-1000) [-1000|1000] "NM" TBOX
 SG_ MCU_MILReq : 15|1@0+ (1,0) [0|1] "" TBOX
 SG_ MCU_MotorSpeed : 31|16@0+ (1,-32767) [-32767|32768] "RPM" TBOX
 SG_ MCU_AuthSts : 42|2@0+ (1,0) [0|3] "" TBOX
 SG_ MCU_OverSpdWarning : 43|1@0+ (1,0) [0|1] "" TBOX
 SG_ MCU_InverterTempWarning : 44|1@0+ (1,0) [0|1] "" TBOX
 SG_ MCU_MotorTempWarning : 45|1@0+ (1,0) [0|1] "" TBOX
 SG_ MCU_OverTemp : 46|1@0+ (1,0) [0|1] "" TBOX
 SG_ MCU_WorkSts : 51|4@0+ (1,0) [0|15] "" TBOX
 SG_ MCU_FaultLevel : 54|3@0+ (1,0) [0|7] "" TBOX
 SG_ MCU_FaultLampOn : 55|1@0+ (1,0) [0|1] "" TBOX
 SG_ MCU_HVLock : 61|2@0+ (1,0) [0|3] "" TBOX
 SG_ Rollingcounter_0x120 : 59|4@0+ (1,0) [0|15] "" TBOX

BO_ 290 MCU_0x122: 8 GW
 SG_ Checksum_0x122 : 7|8@0+ (1,0) [0|255] "" TBOX
 SG_ MCU_MaxAvailableTorque : 15|11@0+ (1,-1023) [-1023|1024] "NM" TBOX
 SG_ MCU_MinAvailableTorque : 18|11@0+ (1,-1023) [-1023|1024] "NM" TBOX
 SG_ MCU_DeratingTempCoolant : 35|1@0+ (1,0) [0|1] "" TBOX
 SG_ MCU_damping_En : 20|2@0+ (1,0) [0|3] "" TBOX
 SG_ MCU_DeratingTrqMin : 40|1@0+ (1,0) [0|1] "" TBOX
 SG_ MCU_DeratingTrqMax : 41|1@0+ (1,0) [0|1] "" TBOX
 SG_ MCU_DeratingOvrUdc : 42|1@0+ (1,0) [0|1] "" TBOX
 SG_ MCU_DeratingUndrUdc : 43|1@0+ (1,0) [0|1] "" TBOX
 SG_ MCU_DeratingOvrIdc : 44|1@0+ (1,0) [0|1] "" TBOX
 SG_ MCU_DeratingUndrIdc : 45|1@0+ (1,0) [0|1] "" TBOX
 SG_ MCU_DeratingTempEm : 46|1@0+ (1,0) [0|1] "" TBOX
 SG_ MCU_DeratingTempInv : 47|1@0+ (1,0) [0|1] "" TBOX
 SG_ Rollingcounter_0x122 : 59|4@0+ (1,0) [0|15] "" TBOX
 SG_ MCU_MotorTorDerLampReq : 61|1@0+ (1,0) [0|1] "" TBOX
 SG_ MCU_HVReady : 62|1@0+ (1,0) [0|1] "" TBOX
 SG_ MCU_DeratingOverSpd : 63|1@0+ (1,0) [0|1] "" TBOX

BO_ 289 ESP_0x121: 8 GW
 SG_ Checksum_0x121 : 7|8@0+ (1,0) [0|255] "" TBOX
 SG_ ESP_VehicleSpeed : 11|12@0+ (0.05625,0) [0|230.28749] "kph" TBOX
 SG_ ESP_VehicleSpeed_Valid : 12|1@0+ (1,0) [0|1] "" TBOX
 SG_ ESP_OFF : 13|1@0+ (1,0) [0|1] "" TBOX
 SG_ ESP_ABS_Error : 14|1@0+ (1,0) [0|1] "" TBOX
 SG_ ESP_ABS_Intervention : 15|1@0+ (1,0) [0|1] "" TBOX
 SG_ ESP_VDC_TCS_Error : 24|1@0+ (1,0) [0|1] "" TBOX
 SG_ ESP_EBD_Error : 25|1@0+ (1,0) [0|1] "" TBOX
 SG_ ESP_VDC_Intervention : 26|1@0+ (1,0) [0|1] "" TBOX
 SG_ ESP_TCS_Intervention : 27|1@0+ (1,0) [0|1] "" TBOX
 SG_ ESP_EBD_Intervention : 28|1@0+ (1,0) [0|1] "" TBOX
 SG_ ESP_HDC_Status : 31|2@0+ (1,0) [0|3] "" TBOX
 SG_ ESP_HDC_Available : 32|1@0+ (1,0) [0|1] "" TBOX
 SG_ ESP_EPBMainteDiagmodeActive : 33|1@0+ (1,0) [0|1] "" TBOX
 SG_ ESP_EPBFailstatus : 34|1@0+ (1,0) [0|1] "" TBOX
 SG_ ESP_EPBStatus : 37|3@0+ (1,0) [0|7] "" TBOX
 SG_ ESP_VehicleStop : 38|1@0+ (1,0) [0|1] "" TBOX
 SG_ ESP_VehicleStop_Valid : 39|1@0+ (1,0) [0|1] "" TBOX
 SG_ ESP_MasterCyPressureCmp : 47|8@0+ (1,0) [0|255] "bar" TBOX
 SG_ ESP_MasterCyPressure_Valid : 48|1@0+ (1,0) [0|1] "" TBOX
 SG_ ESP_WheelCyBrakeForce_Exist : 49|1@0+ (1,0) [0|1] "" TBOX
 SG_ ESP_ESPLamp : 50|1@0+ (1,0) [0|1] "" TBOX
 SG_ ESP_AVHstandbyStatus : 51|1@0+ (1,0) [0|1] "" TBOX
 SG_ ESP_AVHActive : 52|1@0+ (1,0) [0|1] "" TBOX
 SG_ ESP_AVH_availalbe : 53|1@0+ (1,0) [0|1] "" TBOX
 SG_ ESP_HHC_Available : 54|1@0+ (1,0) [0|1] "" TBOX
 SG_ ESP_HHCActive : 55|1@0+ (1,0) [0|1] "" TBOX
 SG_ RollingCounter_0x121 : 59|4@0+ (1,0) [0|15] "" TBOX
 SG_ ESP_HubDiagmodeActive : 60|1@0+ (1,0) [0|1] "" TBOX
 SG_ ESP_HAZ_Active : 61|1@0+ (1,0) [0|1] "" TBOX

BO_ 291 MCU_0x123: 8 GW
 SG_ MCU_IsCurrent : 7|11@0+ (0.5,0) [0|1023.5] "" TBOX
 SG_ MCU_DC_linkVoltage : 12|10@0+ (1,0) [0|1023] "V" TBOX
 SG_ MCU_DC_linkCurrent : 18|11@0+ (1,-1023) [-1023|1024] "A" TBOX
 SG_ MCU_InverterTemp : 39|8@0+ (1,-40) [-40|215] "℃" TBOX
 SG_ MCU_MotorTemp : 47|8@0+ (1,-40) [-40|215] "℃" TBOX

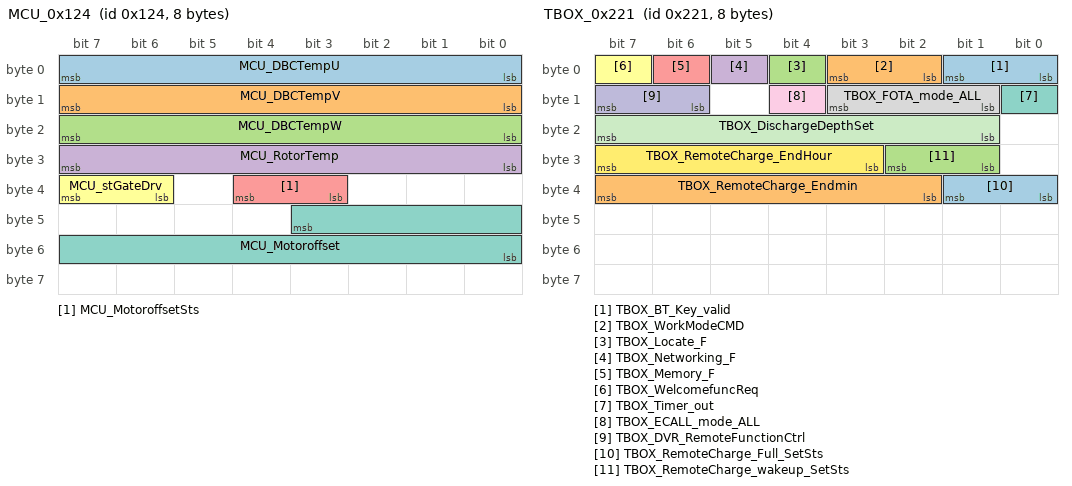
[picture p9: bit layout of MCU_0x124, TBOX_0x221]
BO_ 292 MCU_0x124: 8 GW
 SG_ MCU_DBCTempU : 7|8@0+ (1,-40) [-40|215] "degC" TBOX
 SG_ MCU_DBCTempV : 15|8@0+ (1,-40) [-40|215] "degC" TBOX
 SG_ MCU_DBCTempW : 23|8@0+ (1,-40) [-40|215] "degC" TBOX
 SG_ MCU_RotorTemp : 31|8@0+ (1,-40) [-40|215] "℃" TBOX
 SG_ MCU_MotoroffsetSts : 36|2@0+ (1,0) [0|3] "" TBOX
 SG_ MCU_stGateDrv : 39|2@0+ (1,0) [0|3] "" TBOX
 SG_ MCU_Motoroffset : 43|12@0+ (0.0878906,0) [0|359.9120178] "度" TBOX

BO_ 545 TBOX_0x221: 8 TBOX
 SG_ TBOX_BT_Key_valid : 1|2@0+ (1,0) [0|3] "" GW
 SG_ TBOX_WorkModeCMD : 3|2@0+ (1,0) [0|3] "" GW
 SG_ TBOX_Locate_F : 4|1@0+ (1,0) [0|1] "" GW
 SG_ TBOX_Networking_F : 5|1@0+ (1,0) [0|1] "" GW
 SG_ TBOX_Memory_F : 6|1@0+ (1,0) [0|1] "" GW
 SG_ TBOX_WelcomefuncReq : 7|1@0+ (1,0) [0|1] "" GW
 SG_ TBOX_Timer_out : 8|1@0+ (1,0) [0|1] "" GW
 SG_ TBOX_FOTA_mode_ALL : 11|3@0+ (1,0) [0|7] "" GW
 SG_ TBOX_ECALL_mode_ALL : 12|1@0+ (1,0) [0|1] "" GW
 SG_ TBOX_DVR_RemoteFunctionCtrl : 15|2@0+ (1,0) [0|3] "" GW
 SG_ TBOX_DischargeDepthSet : 23|7@0+ (1,0) [0|100] "%" GW
 SG_ TBOX_RemoteCharge_EndHour : 31|5@0+ (1,0) [0|23] "hour" GW
 SG_ TBOX_RemoteCharge_Full_SetSts : 33|2@0+ (1,0) [0|3] "" GW
 SG_ TBOX_RemoteCharge_Endmin : 39|6@0+ (1,0) [0|59] "min" GW
 SG_ TBOX_RemoteCharge_wakeup_SetSts : 26|2@0+ (1,0) [0|3] "" GW

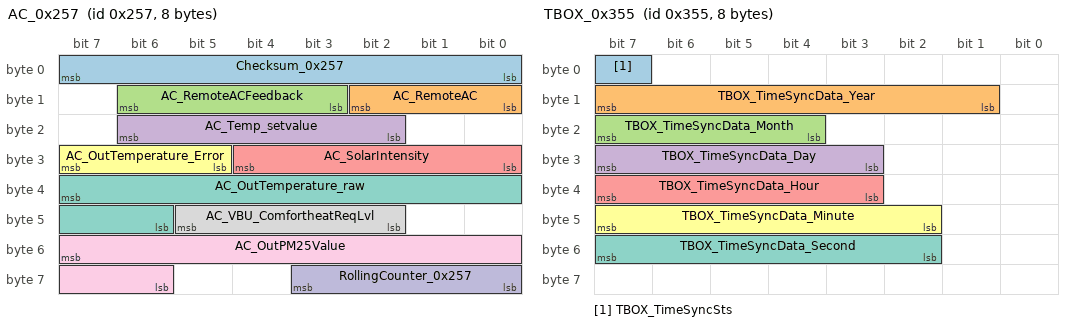
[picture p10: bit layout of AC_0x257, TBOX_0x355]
BO_ 599 AC_0x257: 8 GW
 SG_ Checksum_0x257 : 7|8@0+ (1,0) [0|255] "" TBOX
 SG_ AC_RemoteAC : 10|3@0+ (1,0) [0|7] "" TBOX
 SG_ AC_RemoteACFeedback : 14|4@0+ (1,0) [0|15] "" TBOX
 SG_ AC_Temp_setvalue : 22|5@0+ (1,0) [15|31] "" TBOX
 SG_ AC_SolarIntensity : 28|5@0+ (50,0) [0|1100] "" TBOX
 SG_ AC_OutTemperature_Error : 31|3@0+ (1,0) [0|7] "" TBOX
 SG_ AC_OutTemperature_raw : 39|10@0+ (0.005,0) [0|5] "" TBOX
 SG_ AC_VBU_ComfortheatReqLvl : 45|4@0+ (1,0) [0|15] "" TBOX
 SG_ AC_OutPM25Value : 55|10@0+ (1,0) [0|1023] "μg/m3" TBOX
 SG_ RollingCounter_0x257 : 59|4@0+ (1,0) [0|15] "" TBOX

BO_ 849 TBOX_0x351: 8 TBOX
 SG_ TBOX_BCM_DoorLock_Control_4G : 1|2@0+ (1,0) [0|3] "" GW
 SG_ TBOX_BCM_CarLocating : 4|3@0+ (1,0) [0|7] "" GW
 SG_ TBOX_PLG_TrunkunLock : 7|2@0+ (1,0) [0|3] "" GW
 SG_ TBOX_DSM_heatSwitch : 9|2@0+ (1,0) [0|3] "" GW
 SG_ TBOX_PSM_heatSwitch : 11|2@0+ (1,0) [0|3] "" GW
 SG_ TBOX_BCM_DoorLock_Control_BT : 17|2@0+ (1,0) [0|3] "" GW
 SG_ TBOX_DSM_Targtemp : 23|6@0+ (1,0) [34|42] "℃" GW
 SG_ TBOX_welcomefuncReqsts : 24|1@0+ (1,0) [0|1] "" GW
 SG_ TBOX_Publish_Wakeup : 25|1@0+ (1,0) [0|1] "" GW
 SG_ TBOX_PSM_Targtemp : 31|6@0+ (1,0) [34|42] "℃" GW
 SG_ TBOX_RB_Initialization : 33|1@0+ (1,0) [0|1] "" GW
 SG_ TBOX_BCM_PowerON_Request : 38|2@0+ (1,0) [0|3] "" GW
 SG_ TBOX_BCM_PowerON_limit : 39|1@0+ (1,0) [0|1] "" GW
 SG_ TBOX_RB_Position_Req : 55|8@0+ (1,0) [0|254] "" GW
 SG_ TBOX_BCM_FLWindowsControl : 57|2@0+ (1,0) [0|3] "" GW
 SG_ TBOX_BCM_FRWindowsControl : 59|2@0+ (1,0) [0|3] "" GW
 SG_ TBOX_BCM_RLWindowsControl : 61|2@0+ (1,0) [0|3] "" GW
 SG_ TBOX_BCM_RRWindowsControl : 63|2@0+ (1,0) [0|3] "" GW

BO_ 850 TBOX_0x352: 8 TBOX
 SG_ TBOX_AC_SystemSet : 1|2@0+ (1,0) [0|3] "" GW
 SG_ TBOX_AC_Cycle : 3|2@0+ (1,0) [0|3] "" GW
 SG_ TBOX_AC_EAC_Control : 5|2@0+ (1,0) [0|3] "" GW
 SG_ TBOX_AC_AutoMode_Set : 7|2@0+ (1,0) [0|3] "" GW
 SG_ TBOX_AC_WindMode_Set : 10|3@0+ (1,0) [0|7] "" GW
 SG_ TBOX_AC_FDefrostMode_Set : 12|2@0+ (1,0) [0|3] "" GW
 SG_ TBOX_AC_BlowingRate_Set : 15|3@0+ (1,0) [0|7] "" GW
 SG_ TBOX_AC_APTCSW_Set : 17|2@0+ (1,0) [0|3] "" GW
 SG_ TBOX_AC_Temp_set : 22|5@0+ (1,0) [15|31] "" GW
 SG_ TBOX_HU_rebootACK : 24|1@0+ (1,0) [0|1] "" GW
 SG_ TBOX_RemotePhotograph : 26|2@0+ (1,0) [0|3] "" GW
 SG_ TBOX_ChargeCtrl_Setsts : 31|2@0+ (1,0) [0|3] "" GW
 SG_ TBOX_PLG_OpenControl : 33|2@0+ (1,0) [0|3] "" GW
 SG_ TBOX_RemoteCharge_StartHour : 39|5@0+ (1,0) [0|23] "" GW
 SG_ TBOX_RemoteCharge_Setsts : 41|2@0+ (1,0) [0|3] "" GW
 SG_ TBOX_RemoteCharge_Startmin : 47|6@0+ (1,0) [0|59] "" GW
 SG_ TBOX_BCM_FLWindowsVoiControl : 51|4@0+ (1,0) [0|15] "" GW
 SG_ TBOX_BCM_FRWindowsVoiControl : 55|4@0+ (1,0) [0|15] "" GW
 SG_ TBOX_BCM_RLWindowsVoiControl : 59|4@0+ (1,0) [0|15] "" GW
 SG_ TBOX_BCM_RRWindowsVoiControl : 63|4@0+ (1,0) [0|15] "" GW

BO_ 851 TBOX_0x353: 8 TBOX
 SG_ Checksum_0x353 : 7|8@0+ (1,0) [0|255] "" GW
 SG_ TBOX_RemoteChargetime : 15|10@0+ (1,0) [0|1023] "Min" GW
 SG_ TBOX_VBU_12vChargeReq : 16|1@0+ (1,0) [0|1] "" GW
 SG_ TBOX_VBU_TimeCharge : 18|2@0+ (1,0) [0|3] "" GW
 SG_ TBOX_BTKey_valid : 19|1@0+ (1,0) [0|1] "" GW
 SG_ TBOX_ChargeDepthSet : 21|2@0+ (1,0) [0|3] "" GW
 SG_ TBOX_RemoteChargeper : 31|8@0+ (1,0) [0|100] "%" GW
 SG_ TBOX_APS_EPSStrgWhlAngZero : 32|1@0+ (1,0) [0|1] "" GW
 SG_ TBOX_APS_RequstRemoteParkOut : 34|2@0+ (1,0) [0|3] "" GW
 SG_ TBOX_APS_QuitRemotePark : 36|1@0+ (1,0) [0|1] "" GW
 SG_ TBOX_APS_StartRemoteParkIn : 37|1@0+ (1,0) [0|1] "" GW
 SG_ TBOX_APS_PoewerOff_Request : 39|2@0+ (1,0) [0|3] "" GW
 SG_ TBOX_APS_StraightOut_Request1 : 41|2@0+ (1,0) [0|3] "" GW
 SG_ TBOX_APS_StraightOut_Request2 : 43|2@0+ (1,0) [0|3] "" GW
 SG_ TBOX_APS_PowerON_Request : 45|2@0+ (1,0) [0|3] "" GW
 SG_ TBOX_VBU_RemoteChrgLock : 46|1@0+ (1,0) [0|1] "" GW
 SG_ TBOX_FOTA_mode : 47|1@0+ (1,0) [0|1] "" GW
 SG_ TBOX_BT_KeyDIstance : 50|3@0+ (1,0) [0|7] "" GW
 SG_ TBOX_Ipc_ChargeLight_enable : 53|1@0+ (1,0) [0|1] "" GW
 SG_ TBOX_Ipc_ChrgLock_enable : 54|1@0+ (1,0) [0|1] "" GW
 SG_ TBOX_FOTA_wakeup : 62|3@0+ (1,0) [0|7] "" GW
 SG_ RollingCounter_0x353 : 59|4@0+ (1,0) [0|15] "" GW

BO_ 853 TBOX_0x355: 8 TBOX
 SG_ TBOX_TimeSyncSts : 7|1@0+ (1,0) [0|1] "" GW
 SG_ TBOX_TimeSyncData_Year : 15|7@0+ (1,2000) [2000|2099] "" GW
 SG_ TBOX_TimeSyncData_Month : 23|4@0+ (1,0) [1|12] "" GW
 SG_ TBOX_TimeSyncData_Day : 31|5@0+ (1,0) [1|31] "" GW
 SG_ TBOX_TimeSyncData_Hour : 39|5@0+ (1,0) [0|23] "" GW
 SG_ TBOX_TimeSyncData_Minute : 47|6@0+ (1,0) [0|59] "" GW
 SG_ TBOX_TimeSyncData_Second : 55|6@0+ (1,0) [0|59] "" GW

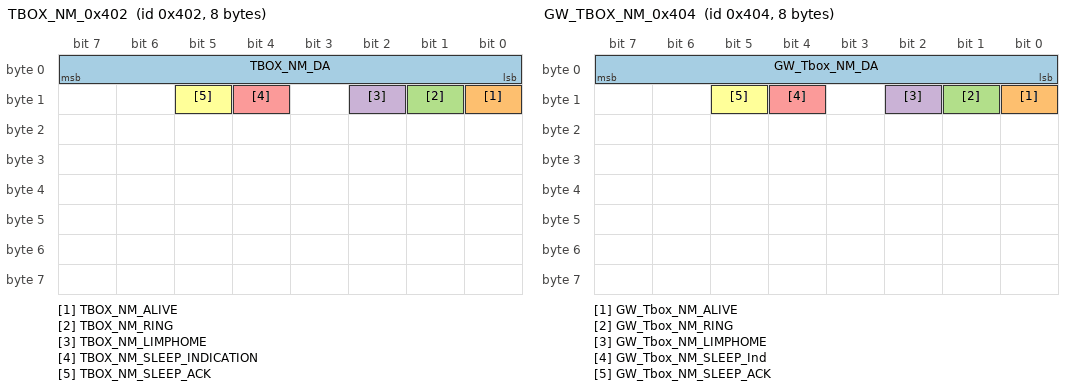
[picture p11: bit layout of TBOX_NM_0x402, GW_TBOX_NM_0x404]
BO_ 1026 TBOX_NM_0x402: 8 TBOX
 SG_ TBOX_NM_DA : 7|8@0+ (1,0) [0|255] "" GW
 SG_ TBOX_NM_ALIVE : 8|1@0+ (1,0) [0|1] "" GW
 SG_ TBOX_NM_RING : 9|1@0+ (1,0) [0|1] "" GW
 SG_ TBOX_NM_LIMPHOME : 10|1@0+ (1,0) [0|1] "" GW
 SG_ TBOX_NM_SLEEP_INDICATION : 12|1@0+ (1,0) [0|1] "" GW
 SG_ TBOX_NM_SLEEP_ACK : 13|1@0+ (1,0) [0|1] "" GW

BO_ 1028 GW_TBOX_NM_0x404: 8 GW
 SG_ GW_Tbox_NM_DA : 7|8@0+ (1,0) [0|255] "" TBOX
 SG_ GW_Tbox_NM_ALIVE : 8|1@0+ (1,0) [0|1] "" TBOX
 SG_ GW_Tbox_NM_RING : 9|1@0+ (1,0) [0|1] "" TBOX
 SG_ GW_Tbox_NM_LIMPHOME : 10|1@0+ (1,0) [0|1] "" TBOX
 SG_ GW_Tbox_NM_SLEEP_Ind : 12|1@0+ (1,0) [0|1] "" TBOX
 SG_ GW_Tbox_NM_SLEEP_ACK : 13|1@0+ (1,0) [0|1] "" TBOX

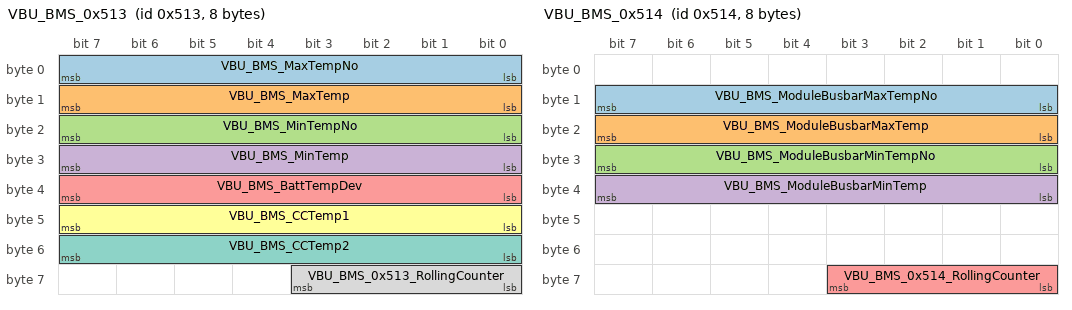
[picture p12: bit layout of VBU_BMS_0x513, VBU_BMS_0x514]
BO_ 1299 VBU_BMS_0x513: 8 GW
 SG_ VBU_BMS_MaxTempNo : 7|8@0+ (1,0) [0|255] "" TBOX
 SG_ VBU_BMS_MaxTemp : 15|8@0+ (0.5,-40) [-40|85] "℃" TBOX
 SG_ VBU_BMS_MinTempNo : 23|8@0+ (1,0) [0|255] "" TBOX
 SG_ VBU_BMS_MinTemp : 31|8@0+ (0.5,-40) [-40|85] "℃" TBOX
 SG_ VBU_BMS_BattTempDev : 39|8@0+ (0.5,-40) [-40|85] "℃" TBOX
 SG_ VBU_BMS_CCTemp1 : 47|8@0+ (1,-40) [-40|120] "℃" TBOX
 SG_ VBU_BMS_CCTemp2 : 55|8@0+ (1,-40) [-40|120] "℃" TBOX
 SG_ VBU_BMS_0x513_RollingCounter : 59|4@0+ (1,0) [0|15] "" TBOX

BO_ 1300 VBU_BMS_0x514: 8 GW
 SG_ VBU_BMS_ModuleBusbarMaxTempNo : 15|8@0+ (1,0) [0|255] "" TBOX
 SG_ VBU_BMS_ModuleBusbarMaxTemp : 23|8@0+ (0.5,-40) [-40|85] "℃" TBOX
 SG_ VBU_BMS_ModuleBusbarMinTempNo : 31|8@0+ (1,0) [0|255] "" TBOX
 SG_ VBU_BMS_ModuleBusbarMinTemp : 39|8@0+ (0.5,-40) [-40|85] "℃" TBOX
 SG_ VBU_BMS_0x514_RollingCounter : 59|4@0+ (1,0) [0|15] "" TBOX

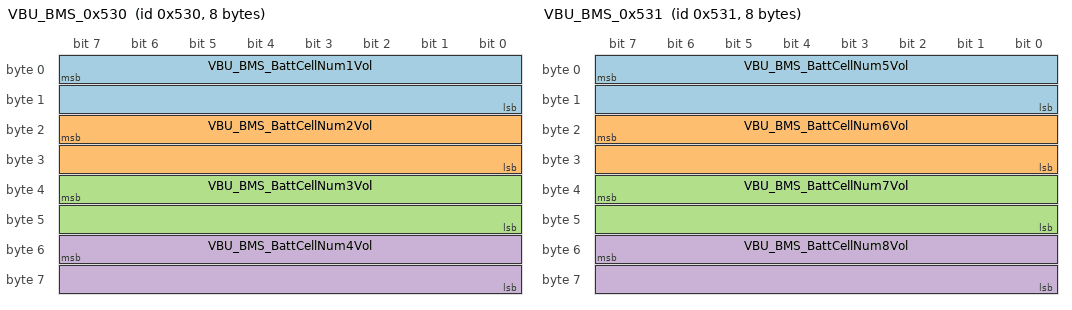
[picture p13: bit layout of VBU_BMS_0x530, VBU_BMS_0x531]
BO_ 1328 VBU_BMS_0x530: 8 GW
 SG_ VBU_BMS_BattCellNum1Vol : 7|16@0+ (1,0) [0|5000] "mV" TBOX
 SG_ VBU_BMS_BattCellNum2Vol : 23|16@0+ (1,0) [0|5000] "mV" TBOX
 SG_ VBU_BMS_BattCellNum3Vol : 39|16@0+ (1,0) [0|5000] "mV" TBOX
 SG_ VBU_BMS_BattCellNum4Vol : 55|16@0+ (1,0) [0|5000] "mV" TBOX

BO_ 1329 VBU_BMS_0x531: 8 GW
 SG_ VBU_BMS_BattCellNum5Vol : 7|16@0+ (1,0) [0|5000] "mV" TBOX
 SG_ VBU_BMS_BattCellNum6Vol : 23|16@0+ (1,0) [0|5000] "mV" TBOX
 SG_ VBU_BMS_BattCellNum7Vol : 39|16@0+ (1,0) [0|5000] "mV" TBOX
 SG_ VBU_BMS_BattCellNum8Vol : 55|16@0+ (1,0) [0|5000] "mV" TBOX

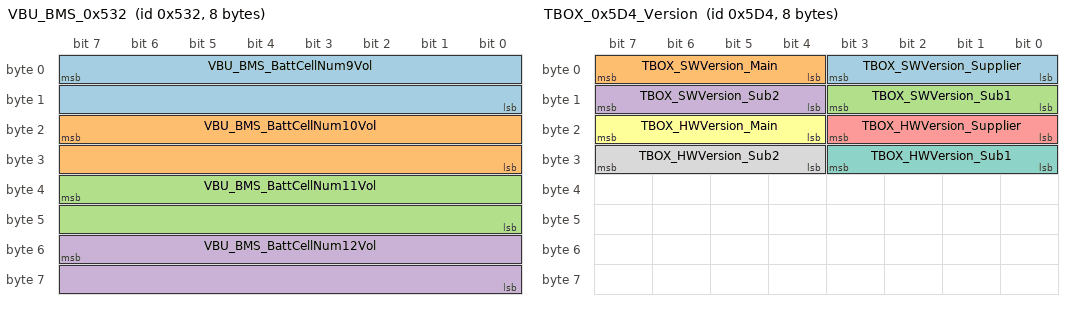
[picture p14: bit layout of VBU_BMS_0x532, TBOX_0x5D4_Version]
BO_ 1330 VBU_BMS_0x532: 8 GW
 SG_ VBU_BMS_BattCellNum9Vol : 7|16@0+ (1,0) [0|5000] "mV" TBOX
 SG_ VBU_BMS_BattCellNum10Vol : 23|16@0+ (1,0) [0|5000] "mV" TBOX
 SG_ VBU_BMS_BattCellNum11Vol : 39|16@0+ (1,0) [0|5000] "mV" TBOX
 SG_ VBU_BMS_BattCellNum12Vol : 55|16@0+ (1,0) [0|5000] "mV" TBOX

BO_ 1331 VBU_BMS_0x533: 8 GW
 SG_ VBU_BMS_BattCellNum13Vol : 7|16@0+ (1,0) [0|5000] "mV" TBOX
 SG_ VBU_BMS_BattCellNum14Vol : 23|16@0+ (1,0) [0|5000] "mV" TBOX
 SG_ VBU_BMS_BattCellNum15Vol : 39|16@0+ (1,0) [0|5000] "mV" TBOX
 SG_ VBU_BMS_BattCellNum16Vol : 55|16@0+ (1,0) [0|5000] "mV" TBOX

BO_ 1332 VBU_BMS_0x534: 8 GW
 SG_ VBU_BMS_BattCellNum17Vol : 7|16@0+ (1,0) [0|5000] "mV" TBOX
 SG_ VBU_BMS_BattCellNum18Vol : 23|16@0+ (1,0) [0|5000] "mV" TBOX
 SG_ VBU_BMS_BattCellNum19Vol : 39|16@0+ (1,0) [0|5000] "mV" TBOX
 SG_ VBU_BMS_BattCellNum20Vol : 55|16@0+ (1,0) [0|5000] "mV" TBOX

BO_ 1333 VBU_BMS_0x535: 8 GW
 SG_ VBU_BMS_BattCellNum21Vol : 7|16@0+ (1,0) [0|5000] "mV" TBOX
 SG_ VBU_BMS_BattCellNum22Vol : 23|16@0+ (1,0) [0|5000] "mV" TBOX
 SG_ VBU_BMS_BattCellNum23Vol : 39|16@0+ (1,0) [0|5000] "mV" TBOX
 SG_ VBU_BMS_BattCellNum24Vol : 55|16@0+ (1,0) [0|5000] "mV" TBOX

BO_ 1334 VBU_BMS_0x536: 8 GW
 SG_ VBU_BMS_BattCellNum25Vol : 7|16@0+ (1,0) [0|5000] "mV" TBOX
 SG_ VBU_BMS_BattCellNum26Vol : 23|16@0+ (1,0) [0|5000] "mV" TBOX
 SG_ VBU_BMS_BattCellNum27Vol : 39|16@0+ (1,0) [0|5000] "mV" TBOX
 SG_ VBU_BMS_BattCellNum28Vol : 55|16@0+ (1,0) [0|5000] "mV" TBOX

BO_ 1335 VBU_BMS_0x537: 8 GW
 SG_ VBU_BMS_BattCellNum29Vol : 7|16@0+ (1,0) [0|5000] "mV" TBOX
 SG_ VBU_BMS_BattCellNum30Vol : 23|16@0+ (1,0) [0|5000] "mV" TBOX
 SG_ VBU_BMS_BattCellNum31Vol : 39|16@0+ (1,0) [0|5000] "mV" TBOX
 SG_ VBU_BMS_BattCellNum32Vol : 55|16@0+ (1,0) [0|5000] "mV" TBOX

BO_ 1336 VBU_BMS_0x538: 8 GW
 SG_ VBU_BMS_BattCellNum33Vol : 7|16@0+ (1,0) [0|5000] "mV" TBOX
 SG_ VBU_BMS_BattCellNum34Vol : 23|16@0+ (1,0) [0|5000] "mV" TBOX
 SG_ VBU_BMS_BattCellNum35Vol : 39|16@0+ (1,0) [0|5000] "mV" TBOX
 SG_ VBU_BMS_BattCellNum36Vol : 55|16@0+ (1,0) [0|5000] "mV" TBOX

BO_ 1337 VBU_BMS_0x539: 8 GW
 SG_ VBU_BMS_BattCellNum37Vol : 7|16@0+ (1,0) [0|5000] "mV" TBOX
 SG_ VBU_BMS_BattCellNum38Vol : 23|16@0+ (1,0) [0|5000] "mV" TBOX
 SG_ VBU_BMS_BattCellNum39Vol : 39|16@0+ (1,0) [0|5000] "mV" TBOX
 SG_ VBU_BMS_BattCellNum40Vol : 55|16@0+ (1,0) [0|5000] "mV" TBOX

BO_ 1338 VBU_BMS_0x53A: 8 GW
 SG_ VBU_BMS_BattCellNum41Vol : 7|16@0+ (1,0) [0|5000] "mV" TBOX
 SG_ VBU_BMS_BattCellNum42Vol : 23|16@0+ (1,0) [0|5000] "mV" TBOX
 SG_ VBU_BMS_BattCellNum43Vol : 39|16@0+ (1,0) [0|5000] "mV" TBOX
 SG_ VBU_BMS_BattCellNum44Vol : 55|16@0+ (1,0) [0|5000] "mV" TBOX

BO_ 1339 VBU_BMS_0x53B: 8 GW
 SG_ VBU_BMS_BattCellNum45Vol : 7|16@0+ (1,0) [0|5000] "mV" TBOX
 SG_ VBU_BMS_BattCellNum46Vol : 23|16@0+ (1,0) [0|5000] "mV" TBOX
 SG_ VBU_BMS_BattCellNum47Vol : 39|16@0+ (1,0) [0|5000] "mV" TBOX
 SG_ VBU_BMS_BattCellNum48Vol : 55|16@0+ (1,0) [0|5000] "mV" TBOX

BO_ 1340 VBU_BMS_0x53C: 8 GW
 SG_ VBU_BMS_BattCellNum49Vol : 7|16@0+ (1,0) [0|5000] "mV" TBOX
 SG_ VBU_BMS_BattCellNum50Vol : 23|16@0+ (1,0) [0|5000] "mV" TBOX
 SG_ VBU_BMS_BattCellNum51Vol : 39|16@0+ (1,0) [0|5000] "mV" TBOX
 SG_ VBU_BMS_BattCellNum52Vol : 55|16@0+ (1,0) [0|5000] "mV" TBOX

BO_ 1341 VBU_BMS_0x53D: 8 GW
 SG_ VBU_BMS_BattCellNum53Vol : 7|16@0+ (1,0) [0|5000] "mV" TBOX
 SG_ VBU_BMS_BattCellNum54Vol : 23|16@0+ (1,0) [0|5000] "mV" TBOX
 SG_ VBU_BMS_BattCellNum55Vol : 39|16@0+ (1,0) [0|5000] "mV" TBOX
 SG_ VBU_BMS_BattCellNum56Vol : 55|16@0+ (1,0) [0|5000] "mV" TBOX

BO_ 1342 VBU_BMS_0x53E: 8 GW
 SG_ VBU_BMS_BattCellNum57Vol : 7|16@0+ (1,0) [0|5000] "mV" TBOX
 SG_ VBU_BMS_BattCellNum58Vol : 23|16@0+ (1,0) [0|5000] "mV" TBOX
 SG_ VBU_BMS_BattCellNum59Vol : 39|16@0+ (1,0) [0|5000] "mV" TBOX
 SG_ VBU_BMS_BattCellNum60Vol : 55|16@0+ (1,0) [0|5000] "mV" TBOX

BO_ 1343 VBU_BMS_0x53F: 8 GW
 SG_ VBU_BMS_BattCellNum61Vol : 7|16@0+ (1,0) [0|5000] "mV" TBOX
 SG_ VBU_BMS_BattCellNum62Vol : 23|16@0+ (1,0) [0|5000] "mV" TBOX
 SG_ VBU_BMS_BattCellNum63Vol : 39|16@0+ (1,0) [0|5000] "mV" TBOX
 SG_ VBU_BMS_BattCellNum64Vol : 55|16@0+ (1,0) [0|5000] "mV" TBOX

BO_ 1344 VBU_BMS_0x540: 8 GW
 SG_ VBU_BMS_BattCellNum65Vol : 7|16@0+ (1,0) [0|5000] "mV" TBOX
 SG_ VBU_BMS_BattCellNum66Vol : 23|16@0+ (1,0) [0|5000] "mV" TBOX
 SG_ VBU_BMS_BattCellNum67Vol : 39|16@0+ (1,0) [0|5000] "mV" TBOX
 SG_ VBU_BMS_BattCellNum68Vol : 55|16@0+ (1,0) [0|5000] "mV" TBOX

BO_ 1345 VBU_BMS_0x541: 8 GW
 SG_ VBU_BMS_BattCellNum69Vol : 7|16@0+ (1,0) [0|5000] "mV" TBOX
 SG_ VBU_BMS_BattCellNum70Vol : 23|16@0+ (1,0) [0|5000] "mV" TBOX
 SG_ VBU_BMS_BattCellNum71Vol : 39|16@0+ (1,0) [0|5000] "mV" TBOX
 SG_ VBU_BMS_BattCellNum72Vol : 55|16@0+ (1,0) [0|5000] "mV" TBOX

BO_ 1346 VBU_BMS_0x542: 8 GW
 SG_ VBU_BMS_BattCellNum73Vol : 7|16@0+ (1,0) [0|5000] "mV" TBOX
 SG_ VBU_BMS_BattCellNum74Vol : 23|16@0+ (1,0) [0|5000] "mV" TBOX
 SG_ VBU_BMS_BattCellNum75Vol : 39|16@0+ (1,0) [0|5000] "mV" TBOX
 SG_ VBU_BMS_BattCellNum76Vol : 55|16@0+ (1,0) [0|5000] "mV" TBOX

BO_ 1347 VBU_BMS_0x543: 8 GW
 SG_ VBU_BMS_BattCellNum77Vol : 7|16@0+ (1,0) [0|5000] "mV" TBOX
 SG_ VBU_BMS_BattCellNum78Vol : 23|16@0+ (1,0) [0|5000] "mV" TBOX
 SG_ VBU_BMS_BattCellNum79Vol : 39|16@0+ (1,0) [0|5000] "mV" TBOX
 SG_ VBU_BMS_BattCellNum80Vol : 55|16@0+ (1,0) [0|5000] "mV" TBOX

BO_ 1348 VBU_BMS_0x544: 8 GW
 SG_ VBU_BMS_BattCellNum81Vol : 7|16@0+ (1,0) [0|5000] "mV" TBOX
 SG_ VBU_BMS_BattCellNum82Vol : 23|16@0+ (1,0) [0|5000] "mV" TBOX
 SG_ VBU_BMS_BattCellNum83Vol : 39|16@0+ (1,0) [0|5000] "mV" TBOX
 SG_ VBU_BMS_BattCellNum84Vol : 55|16@0+ (1,0) [0|5000] "mV" TBOX

BO_ 1349 VBU_BMS_0x545: 8 GW
 SG_ VBU_BMS_BattCellNum85Vol : 7|16@0+ (1,0) [0|5000] "mV" TBOX
 SG_ VBU_BMS_BattCellNum86Vol : 23|16@0+ (1,0) [0|5000] "mV" TBOX
 SG_ VBU_BMS_BattCellNum87Vol : 39|16@0+ (1,0) [0|5000] "mV" TBOX
 SG_ VBU_BMS_BattCellNum88Vol : 55|16@0+ (1,0) [0|5000] "mV" TBOX

BO_ 1350 VBU_BMS_0x546: 8 GW
 SG_ VBU_BMS_BattCellNum89Vol : 7|16@0+ (1,0) [0|5000] "mV" TBOX
 SG_ VBU_BMS_BattCellNum90Vol : 23|16@0+ (1,0) [0|5000] "mV" TBOX
 SG_ VBU_BMS_BattCellNum91Vol : 39|16@0+ (1,0) [0|5000] "mV" TBOX
 SG_ VBU_BMS_BattCellNum92Vol : 55|16@0+ (1,0) [0|5000] "mV" TBOX

BO_ 1351 VBU_BMS_0x547: 8 GW
 SG_ VBU_BMS_BattCellNum93Vol : 7|16@0+ (1,0) [0|5000] "mV" TBOX
 SG_ VBU_BMS_BattCellNum94Vol : 23|16@0+ (1,0) [0|5000] "mV" TBOX
 SG_ VBU_BMS_BattCellNum95Vol : 39|16@0+ (1,0) [0|5000] "mV" TBOX
 SG_ VBU_BMS_BattCellNum96Vol : 55|16@0+ (1,0) [0|5000] "mV" TBOX

BO_ 1352 VBU_BMS_0x548: 8 GW
 SG_ VBU_BMS_BattCellNum97Vol : 7|16@0+ (1,0) [0|5000] "mV" TBOX
 SG_ VBU_BMS_BattCellNum98Vol : 23|16@0+ (1,0) [0|5000] "mV" TBOX
 SG_ VBU_BMS_BattCellNum99Vol : 39|16@0+ (1,0) [0|5000] "mV" TBOX
 SG_ VBU_BMS_BattCellNum100Vol : 55|16@0+ (1,0) [0|5000] "mV" TBOX

BO_ 1353 VBU_BMS_0x549: 8 GW
 SG_ VBU_BMS_BattCellNum101Vol : 7|16@0+ (1,0) [0|5000] "mV" TBOX
 SG_ VBU_BMS_BattCellNum102Vol : 23|16@0+ (1,0) [0|5000] "mV" TBOX
 SG_ VBU_BMS_BattCellNum103Vol : 39|16@0+ (1,0) [0|5000] "mV" TBOX
 SG_ VBU_BMS_BattCellNum104Vol : 55|16@0+ (1,0) [0|5000] "mV" TBOX

BO_ 1354 VBU_BMS_0x54A: 8 GW
 SG_ VBU_BMS_BattCellNum105Vol : 7|16@0+ (1,0) [0|5000] "mV" TBOX
 SG_ VBU_BMS_BattCellNum106Vol : 23|16@0+ (1,0) [0|5000] "mV" TBOX
 SG_ VBU_BMS_BattCellNum107Vol : 39|16@0+ (1,0) [0|5000] "mV" TBOX
 SG_ VBU_BMS_BattCellNum108Vol : 55|16@0+ (1,0) [0|5000] "mV" TBOX

BO_ 1492 TBOX_0x5D4_Version: 8 TBOX
 SG_ TBOX_SWVersion_Supplier : 3|4@0+ (1,0) [0|15] "" GW
 SG_ TBOX_SWVersion_Main : 7|4@0+ (1,0) [0|15] "" GW
 SG_ TBOX_SWVersion_Sub1 : 11|4@0+ (1,0) [0|15] "" GW
 SG_ TBOX_SWVersion_Sub2 : 15|4@0+ (1,0) [0|15] "" GW
 SG_ TBOX_HWVersion_Supplier : 19|4@0+ (1,0) [0|15] "" GW
 SG_ TBOX_HWVersion_Main : 23|4@0+ (1,0) [0|15] "" GW
 SG_ TBOX_HWVersion_Sub1 : 27|4@0+ (1,0) [0|15] "" GW
 SG_ TBOX_HWVersion_Sub2 : 31|4@0+ (1,0) [0|15] "" GW

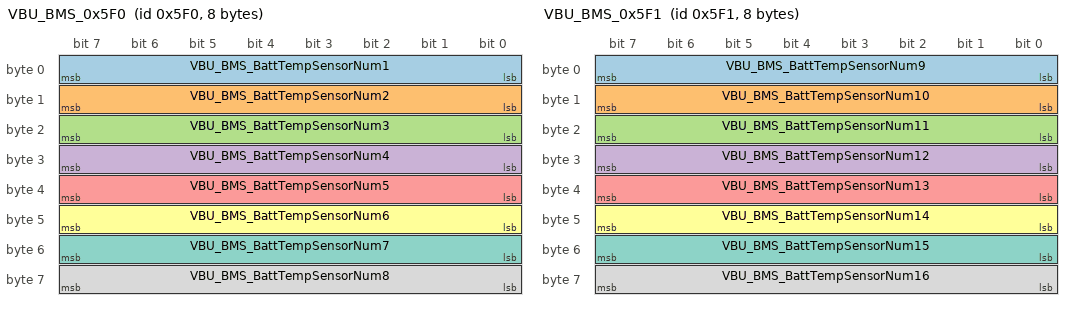
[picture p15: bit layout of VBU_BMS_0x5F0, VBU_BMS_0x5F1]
BO_ 1520 VBU_BMS_0x5F0: 8 GW
 SG_ VBU_BMS_BattTempSensorNum1 : 7|8@0+ (1,-40) [-40|120] "℃" TBOX
 SG_ VBU_BMS_BattTempSensorNum2 : 15|8@0+ (1,-40) [-40|120] "℃" TBOX
 SG_ VBU_BMS_BattTempSensorNum3 : 23|8@0+ (1,-40) [-40|120] "℃" TBOX
 SG_ VBU_BMS_BattTempSensorNum4 : 31|8@0+ (1,-40) [-40|120] "℃" TBOX
 SG_ VBU_BMS_BattTempSensorNum5 : 39|8@0+ (1,-40) [-40|120] "℃" TBOX
 SG_ VBU_BMS_BattTempSensorNum6 : 47|8@0+ (1,-40) [-40|120] "℃" TBOX
 SG_ VBU_BMS_BattTempSensorNum7 : 55|8@0+ (1,-40) [-40|120] "℃" TBOX
 SG_ VBU_BMS_BattTempSensorNum8 : 63|8@0+ (1,-40) [-40|120] "℃" TBOX

BO_ 1521 VBU_BMS_0x5F1: 8 GW
 SG_ VBU_BMS_BattTempSensorNum9 : 7|8@0+ (1,-40) [-40|120] "℃" TBOX
 SG_ VBU_BMS_BattTempSensorNum10 : 15|8@0+ (1,-40) [-40|120] "℃" TBOX
 SG_ VBU_BMS_BattTempSensorNum11 : 23|8@0+ (1,-40) [-40|120] "℃" TBOX
 SG_ VBU_BMS_BattTempSensorNum12 : 31|8@0+ (1,-40) [-40|120] "℃" TBOX
 SG_ VBU_BMS_BattTempSensorNum13 : 39|8@0+ (1,-40) [-40|120] "℃" TBOX
 SG_ VBU_BMS_BattTempSensorNum14 : 47|8@0+ (1,-40) [-40|120] "℃" TBOX
 SG_ VBU_BMS_BattTempSensorNum15 : 55|8@0+ (1,-40) [-40|120] "℃" TBOX
 SG_ VBU_BMS_BattTempSensorNum16 : 63|8@0+ (1,-40) [-40|120] "℃" TBOX

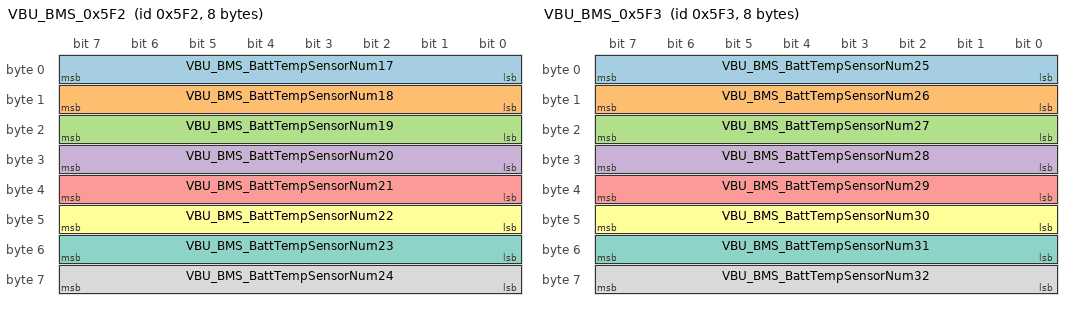
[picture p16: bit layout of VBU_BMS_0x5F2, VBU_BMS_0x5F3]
BO_ 1522 VBU_BMS_0x5F2: 8 GW
 SG_ VBU_BMS_BattTempSensorNum17 : 7|8@0+ (1,-40) [-40|120] "℃" TBOX
 SG_ VBU_BMS_BattTempSensorNum18 : 15|8@0+ (1,-40) [-40|120] "℃" TBOX
 SG_ VBU_BMS_BattTempSensorNum19 : 23|8@0+ (1,-40) [-40|120] "℃" TBOX
 SG_ VBU_BMS_BattTempSensorNum20 : 31|8@0+ (1,-40) [-40|120] "℃" TBOX
 SG_ VBU_BMS_BattTempSensorNum21 : 39|8@0+ (1,-40) [-40|120] "℃" TBOX
 SG_ VBU_BMS_BattTempSensorNum22 : 47|8@0+ (1,-40) [-40|120] "℃" TBOX
 SG_ VBU_BMS_BattTempSensorNum23 : 55|8@0+ (1,-40) [-40|120] "℃" TBOX
 SG_ VBU_BMS_BattTempSensorNum24 : 63|8@0+ (1,-40) [-40|120] "℃" TBOX

BO_ 1523 VBU_BMS_0x5F3: 8 GW
 SG_ VBU_BMS_BattTempSensorNum25 : 7|8@0+ (1,-40) [-40|120] "℃" TBOX
 SG_ VBU_BMS_BattTempSensorNum26 : 15|8@0+ (1,-40) [-40|120] "℃" TBOX
 SG_ VBU_BMS_BattTempSensorNum27 : 23|8@0+ (1,-40) [-40|120] "℃" TBOX
 SG_ VBU_BMS_BattTempSensorNum28 : 31|8@0+ (1,-40) [-40|120] "℃" TBOX
 SG_ VBU_BMS_BattTempSensorNum29 : 39|8@0+ (1,-40) [-40|120] "℃" TBOX
 SG_ VBU_BMS_BattTempSensorNum30 : 47|8@0+ (1,-40) [-40|120] "℃" TBOX
 SG_ VBU_BMS_BattTempSensorNum31 : 55|8@0+ (1,-40) [-40|120] "℃" TBOX
 SG_ VBU_BMS_BattTempSensorNum32 : 63|8@0+ (1,-40) [-40|120] "℃" TBOX

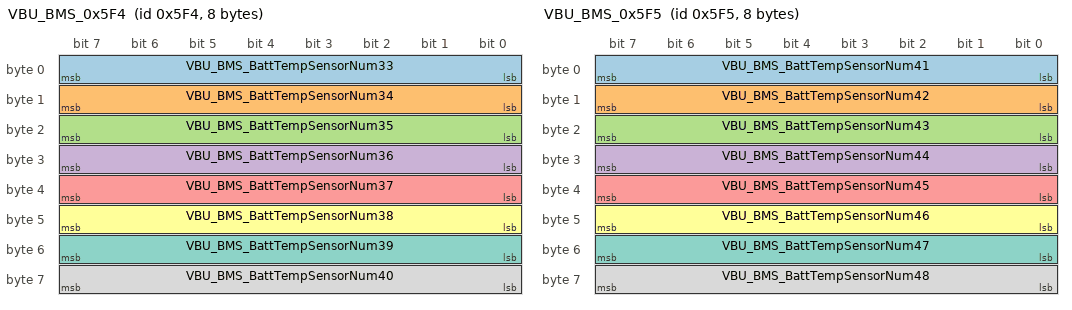
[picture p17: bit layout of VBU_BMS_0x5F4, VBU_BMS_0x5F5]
BO_ 1524 VBU_BMS_0x5F4: 8 GW
 SG_ VBU_BMS_BattTempSensorNum33 : 7|8@0+ (1,-40) [-40|120] "℃" TBOX
 SG_ VBU_BMS_BattTempSensorNum34 : 15|8@0+ (1,-40) [-40|120] "℃" TBOX
 SG_ VBU_BMS_BattTempSensorNum35 : 23|8@0+ (1,-40) [-40|120] "℃" TBOX
 SG_ VBU_BMS_BattTempSensorNum36 : 31|8@0+ (1,-40) [-40|120] "℃" TBOX
 SG_ VBU_BMS_BattTempSensorNum37 : 39|8@0+ (1,-40) [-40|120] "℃" TBOX
 SG_ VBU_BMS_BattTempSensorNum38 : 47|8@0+ (1,-40) [-40|120] "℃" TBOX
 SG_ VBU_BMS_BattTempSensorNum39 : 55|8@0+ (1,-40) [-40|120] "℃" TBOX
 SG_ VBU_BMS_BattTempSensorNum40 : 63|8@0+ (1,-40) [-40|120] "℃" TBOX

BO_ 1525 VBU_BMS_0x5F5: 8 GW
 SG_ VBU_BMS_BattTempSensorNum41 : 7|8@0+ (1,-40) [-40|120] "℃" TBOX
 SG_ VBU_BMS_BattTempSensorNum42 : 15|8@0+ (1,-40) [-40|120] "℃" TBOX
 SG_ VBU_BMS_BattTempSensorNum43 : 23|8@0+ (1,-40) [-40|120] "℃" TBOX
 SG_ VBU_BMS_BattTempSensorNum44 : 31|8@0+ (1,-40) [-40|120] "℃" TBOX
 SG_ VBU_BMS_BattTempSensorNum45 : 39|8@0+ (1,-40) [-40|120] "℃" TBOX
 SG_ VBU_BMS_BattTempSensorNum46 : 47|8@0+ (1,-40) [-40|120] "℃" TBOX
 SG_ VBU_BMS_BattTempSensorNum47 : 55|8@0+ (1,-40) [-40|120] "℃" TBOX
 SG_ VBU_BMS_BattTempSensorNum48 : 63|8@0+ (1,-40) [-40|120] "℃" TBOX

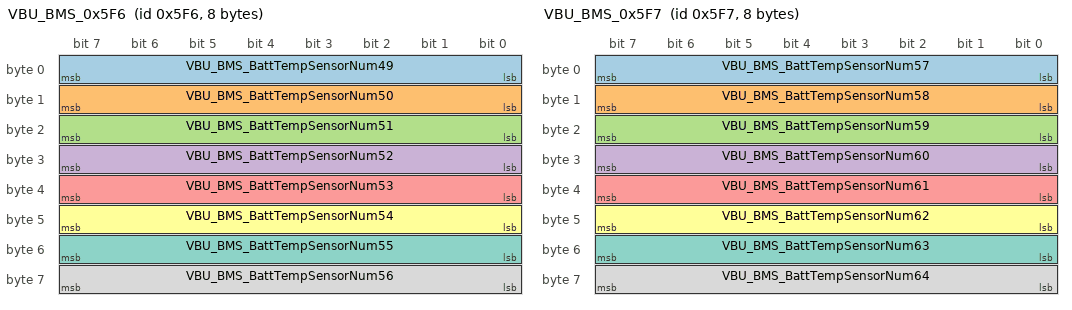
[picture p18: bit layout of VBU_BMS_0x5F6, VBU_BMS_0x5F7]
BO_ 1526 VBU_BMS_0x5F6: 8 GW
 SG_ VBU_BMS_BattTempSensorNum49 : 7|8@0+ (1,-40) [-40|120] "℃" TBOX
 SG_ VBU_BMS_BattTempSensorNum50 : 15|8@0+ (1,-40) [-40|120] "℃" TBOX
 SG_ VBU_BMS_BattTempSensorNum51 : 23|8@0+ (1,-40) [-40|120] "℃" TBOX
 SG_ VBU_BMS_BattTempSensorNum52 : 31|8@0+ (1,-40) [-40|120] "℃" TBOX
 SG_ VBU_BMS_BattTempSensorNum53 : 39|8@0+ (1,-40) [-40|120] "℃" TBOX
 SG_ VBU_BMS_BattTempSensorNum54 : 47|8@0+ (1,-40) [-40|120] "℃" TBOX
 SG_ VBU_BMS_BattTempSensorNum55 : 55|8@0+ (1,-40) [-40|120] "℃" TBOX
 SG_ VBU_BMS_BattTempSensorNum56 : 63|8@0+ (1,-40) [-40|120] "℃" TBOX

BO_ 1527 VBU_BMS_0x5F7: 8 GW
 SG_ VBU_BMS_BattTempSensorNum57 : 7|8@0+ (1,-40) [-40|120] "℃" TBOX
 SG_ VBU_BMS_BattTempSensorNum58 : 15|8@0+ (1,-40) [-40|120] "℃" TBOX
 SG_ VBU_BMS_BattTempSensorNum59 : 23|8@0+ (1,-40) [-40|120] "℃" TBOX
 SG_ VBU_BMS_BattTempSensorNum60 : 31|8@0+ (1,-40) [-40|120] "℃" TBOX
 SG_ VBU_BMS_BattTempSensorNum61 : 39|8@0+ (1,-40) [-40|120] "℃" TBOX
 SG_ VBU_BMS_BattTempSensorNum62 : 47|8@0+ (1,-40) [-40|120] "℃" TBOX
 SG_ VBU_BMS_BattTempSensorNum63 : 55|8@0+ (1,-40) [-40|120] "℃" TBOX
 SG_ VBU_BMS_BattTempSensorNum64 : 63|8@0+ (1,-40) [-40|120] "℃" TBOX

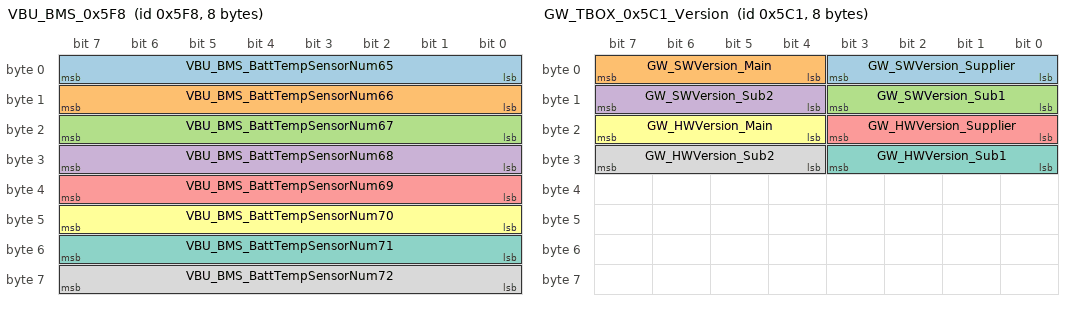
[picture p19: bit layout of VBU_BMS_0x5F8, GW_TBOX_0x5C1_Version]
BO_ 1528 VBU_BMS_0x5F8: 8 GW
 SG_ VBU_BMS_BattTempSensorNum65 : 7|8@0+ (1,-40) [-40|120] "℃" TBOX
 SG_ VBU_BMS_BattTempSensorNum66 : 15|8@0+ (1,-40) [-40|120] "℃" TBOX
 SG_ VBU_BMS_BattTempSensorNum67 : 23|8@0+ (1,-40) [-40|120] "℃" TBOX
 SG_ VBU_BMS_BattTempSensorNum68 : 31|8@0+ (1,-40) [-40|120] "℃" TBOX
 SG_ VBU_BMS_BattTempSensorNum69 : 39|8@0+ (1,-40) [-40|120] "℃" TBOX
 SG_ VBU_BMS_BattTempSensorNum70 : 47|8@0+ (1,-40) [-40|120] "℃" TBOX
 SG_ VBU_BMS_BattTempSensorNum71 : 55|8@0+ (1,-40) [-40|120] "℃" TBOX
 SG_ VBU_BMS_BattTempSensorNum72 : 63|8@0+ (1,-40) [-40|120] "℃" TBOX

BO_ 1473 GW_TBOX_0x5C1_Version: 8 GW
 SG_ GW_SWVersion_Supplier : 3|4@0+ (1,0) [0|15] "" TBOX
 SG_ GW_SWVersion_Main : 7|4@0+ (1,0) [0|15] "" TBOX
 SG_ GW_SWVersion_Sub1 : 11|4@0+ (1,0) [0|15] "" TBOX
 SG_ GW_SWVersion_Sub2 : 15|4@0+ (1,0) [0|15] "" TBOX
 SG_ GW_HWVersion_Supplier : 19|4@0+ (1,0) [0|15] "" TBOX
 SG_ GW_HWVersion_Main : 23|4@0+ (1,0) [0|15] "" TBOX
 SG_ GW_HWVersion_Sub1 : 27|4@0+ (1,0) [0|15] "" TBOX
 SG_ GW_HWVersion_Sub2 : 31|4@0+ (1,0) [0|15] "" TBOX

CM_ SG_ 945 TBOX_YawAngvelocity "Yaw轴角速度";
CM_ SG_ 945 TBOX_PitchAngvelocity "Pitch轴角速度";
CM_ SG_ 945 TBOX_RollAngvelocity "Roll轴角速度";
CM_ SG_ 946 TBOX_YawAcceleration "Yaw轴加速度";
CM_ SG_ 946 TBOX_PitchAcceleration "Pitch轴加速度";
CM_ SG_ 946 TBOX_RollAcceleration "Roll轴加速度";
CM_ SG_ 946 TBOX_GyroTemperature "陀螺仪温度";
CM_ SG_ 1378 MCU_MotorSts_GBT "驱动电机工作状态_GBT32960";
CM_ SG_ 1378 MCU_MotoroffsetCalReq "电机角度自学习请求";
CM_ SG_ 805 WPTC_Checksum_0x325 "WPTC0x325校验和";
CM_ SG_ 805 WPTC_Power "WPTC实际工作功率";
CM_ SG_ 805 WPTC_OutletTemp "WPTC出口水温";
CM_ SG_ 805 WPTC_InputTemp "WPTC进口水温";
CM_ SG_ 805 WPTC_CUR "WPTC当前运行电流";
CM_ SG_ 805 WPTC_COM_VBU_Lost "WPTC与VBU通讯丢失故障";
CM_ SG_ 805 WPTC_CUR_Over "WPTC过流故障";
CM_ SG_ 805 WPTC_Temp_PCB_High "WPTC的PCB板过温故障";
CM_ SG_ 805 WPTC_OutletTemp_High "WPTC出水口过温故障";
CM_ SG_ 805 WPTC_InputTemp_High "WPTC进水口过温故障";
CM_ SG_ 805 WPTC_PowerMaxLim "WPTC最大允许功率";
CM_ SG_ 805 WPTC_RunSts "WPTC运行状态";
CM_ SG_ 805 WPTC_HVSts "WPTC高压供电状态";
CM_ SG_ 805 WPTC_RollingCounter_0x325 "WPTC0x325滚动计数器";
CM_ SG_ 1323 VBU_State0 "VBU状态0";
CM_ SG_ 1323 VBU_State1 "VBU状态1";
CM_ SG_ 1323 VBU_State2 "VBU状态2";
CM_ SG_ 1323 VBU_State3 "VBU状态3";
CM_ SG_ 1323 VBU_State4 "VBU状态4";
CM_ SG_ 1323 VBU_State5 "VBU状态5";
CM_ SG_ 1323 VBU_State6 "VBU状态6";
CM_ SG_ 1323 VBU_State7 "VBU状态7";
CM_ SG_ 1325 VBU_ErrorCode0 "VBU故障码0";
CM_ SG_ 1325 VBU_ErrorCode1 "VBU故障码1";
CM_ SG_ 1325 VBU_ErrorCode2 "VBU故障码2";
CM_ SG_ 1325 VBU_ErrorCode3 "VBU故障码3";
CM_ SG_ 1326 VBU_ErrorCode4 "VBU故障码4";
CM_ SG_ 1326 VBU_ErrorCode5 "VBU故障码5";
CM_ SG_ 1326 VBU_ErrorCode6 "VBU故障码6";
CM_ SG_ 1326 VBU_ErrorCode7 "VBU故障码7";
CM_ SG_ 1327 VBU_ErrorCode8 "VBU故障码8";
CM_ SG_ 1327 VBU_ErrorCode9 "VBU故障码9";
CM_ SG_ 1327 VBU_ErrorAction1 "VBU故障动作1";
CM_ SG_ 1327 VBU_ErrorAction2 "VBU故障动作2";
CM_ SG_ 1327 VBU_ErrorAction3 "VBU故障动作3";
CM_ SG_ 1327 VBU_ErrorAction4 "VBU故障动作4";
CM_ SG_ 1379 VBU_MCUOutputWaterTemp "电机出水口温度";
CM_ SG_ 1379 VBU_ACChargeSocketTemp "交流充电插座温度";
CM_ SG_ 1379 VBU_ComfortPumpPWM "乘员舱水泵输出占空比(HEV)";
CM_ SG_ 1379 VBU_MotorPumpFB_PWM "电机水泵反馈占空比";
CM_ SG_ 1379 VBU_FastCharge_A "直流枪A+信号";
CM_ SG_ 1379 VBU_CC2 "直流枪CC2电压";
CM_ SG_ 1379 VBU_BatPumpFB_PWM "电池水泵反馈占空比";
CM_ SG_ 1379 VBU_DCChargeSocketTemp "直流充电插座温度";
CM_ SG_ 1379 VBU_ComfortPumpFB_PWM "乘员舱水泵反馈占空比(HEV)";
CM_ SG_ 401 Checksum_0x191 "Checksum: IDMSB XOR IDLSB XOR Byte1 XOR Byte2 XOR Byte3 XOR Byte4 XOR Byte5 XOR Byte6 XOR Byte7";
CM_ SG_ 401 APS_SystemSts "APA功能内部状态
";
CM_ SG_ 401 APS_Active "APA功能是否激活";
CM_ SG_ 401 APS_HU_Failure "APS系统故障，不能进入APS模式";
CM_ SG_ 401 APS_VBU_Speed_Limitation "APS限速值";
CM_ SG_ 401 APS_VBU_Target_Gear_Request "目标档位";
CM_ SG_ 401 APS_AVM_HU_CurrentSts "APS/AVM上报给HU的当前状态";
CM_ SG_ 401 APS_HU_ParkPrompttone "找到车位提示音";
CM_ SG_ 401 APS_VBU_APAFailed "APA反馈VBU的故障状态";
CM_ SG_ 401 APS_AVM_FactoryMode "APS/AVM工厂模式状态";
CM_ SG_ 401 APS_VBU_Stop_Distance "停车距离";
CM_ SG_ 401 APS_R_Gear_RequestTips "换入R档请求";
CM_ SG_ 401 APS_VBU_BrakeModeSts "制动模式状态";
CM_ SG_ 401 RollingCounter_0x191 "RollingCounter: used 4bit length signal and the arithmetic is increased from 0 to 15 by every message.";
CM_ SG_ 624 Checksum_0x270 "Checksum: IDMSB XOR IDLSB XOR Byte1 XOR Byte2 XOR Byte3 XOR Byte4 XOR Byte5 XOR Byte6 XOR Byte7";
CM_ SG_ 624 APS_TrgtEPSStrgWhlAng "Advanced Park Assist Target Electric Power Steering Steering Wheel Angle
APA需求的目标转向角度";
CM_ SG_ 624 APS_APAFailed "Advanced Park Assist Failed 
APA故障";
CM_ SG_ 624 APS_CmdEPSSts "Advanced Park Assist Command Electric Power Steering Status
APA状态";
CM_ SG_ 624 APS_FailureBrakeMode "APS_FailureBrakeMode（预留）";
CM_ SG_ 624 APS_BrakeModeSts "APS_BrakeModeSts（预留）
";
CM_ SG_ 624 APS_ESP_Stop_Distance "APA对ESP请求的目标停车距离（预留）";
CM_ SG_ 624 APS_BrakeFunctionMode "APS_BrakeFunctionMode（预留）";
CM_ SG_ 624 APS_ESP_Speed_Limitation "APA对ESP请求的最大允许车速（预留）";
CM_ SG_ 624 RollingCounter_0x270 "RollingCounter: used 4bit length signal and the arithmetic is increased from 0 to 15 by every message.";
CM_ SG_ 624 APS_ESC_Target_Gear_Request "
APA请求的目标档位信号（预留）";
CM_ SG_ 625 Checksum_0x271 "Checksum: IDMSB XOR IDLSB XOR Byte1 XOR Byte2 XOR Byte3 XOR Byte4 XOR Byte5 XOR Byte6 XOR Byte7";
CM_ SG_ 625 APS_APS_AutoSearchSts "自动泊车车位搜寻状态";
CM_ SG_ 625 APS_APS_ParkOutChkResult "当前是否满足泊出条件";
CM_ SG_ 625 APS_APS_CurrentPathNum "本次泊车中的当前所处路径数";
CM_ SG_ 625 APS_APS_TotalPathNum "本次泊车需要的总路径数";
CM_ SG_ 625 APS_APS_SuspendedReason "主动泊车暂停原因";
CM_ SG_ 625 APS_APS_AbortReason "主动泊车中止原因";
CM_ SG_ 625 APS_APS_CurrentParkType "当前选择的泊车类型";
CM_ SG_ 625 APS_APS_OverrideReason "主动泊车驾驶员介入原因";
CM_ SG_ 625 APS_APS_VehicleDirection "在当前路径中车辆行驶方向";
CM_ SG_ 625 APS_APS_TerminatedType "APA终止类型";
CM_ SG_ 625 APS_RemoteParkIn_Status "遥控泊入状态";
CM_ SG_ 625 APS_BCM_RemoteParkIn_Status "APS请求BCM控制状态位";
CM_ SG_ 625 APS_BCM_DoubleFlash "APS请求BCM双闪";
CM_ SG_ 625 APS_BCM_AllDoorUnLock_Door "APS请求BCM解锁";
CM_ SG_ 625 APS_BCM_PowerOffReq "遥控泊车完成后下电请求发送给BCM";
CM_ SG_ 625 RollingCounter_0x271 "RollingCounter: used 4bit length signal and the arithmetic is increased from 0 to 15 by every message.";
CM_ SG_ 625 APS_ParkDirection "泊车方向";
CM_ SG_ 625 APS_APP_RPA_Status "遥控泊车状态";
CM_ SG_ 920 ORM_LeftMirrorMotor1fault "左侧后视镜上下调节电机故障";
CM_ SG_ 920 ORM_LeftMirrorMotor2fault "左侧后视镜左右调节电机故障";
CM_ SG_ 920 ORM_RightMirrorMotor1fault "右侧后视镜上下调节电机故障";
CM_ SG_ 920 ORM_RightMirrorMotor2fault "右侧后视镜左右调节电机故障";
CM_ SG_ 800 EAC_power "压缩机工作功率";
CM_ SG_ 800 EAC_StartSts_F "Compressor state：start error
电动压缩机控制器状态：起动失败";
CM_ SG_ 800 EAC_UnderVoltage_F "Compressor state：under vol
电动压缩机控制器状态：运行欠压";
CM_ SG_ 800 EAC_OverVoltage_F "Compressor state：over vol
电动压缩机控制器状态：运行过压。";
CM_ SG_ 800 EAC_OverCurrent_F "Compressor state：over current
电动压缩机控制器状态：过流";
CM_ SG_ 800 EAC_OverTemp_F "Compressor state：over temperature
电动压缩机控制器状态：过温";
CM_ SG_ 800 EAC_motor_desync "Compressor motor desynchronizing
电动压缩机电机失步故障";
CM_ SG_ 800 EAC_Status "Compressor state：压缩机状态位";
CM_ SG_ 800 EAC_StandbyUnderVol_F "Standby under Voltage
压缩机待机欠压";
CM_ SG_ 800 EAC_StandbyOverVol_F "Standby over Voltage
压缩机待机过压";
CM_ SG_ 800 EAC_Communication_Error "Communication Error
通信故障";
CM_ SG_ 800 EAC_OverCurrentDropFreq "Over Current Drop Frequency
过流降频";
CM_ SG_ 800 EAC_OverPeakCurrent "Over Peak Current 
峰值电流保护";
CM_ SG_ 800 EAC_Current "Compressor current
电动压缩机控制器当前运行电流（母线电流）";
CM_ SG_ 800 EAC_Voltage "Compressor voltage
电动压缩机控制器当前运行电压（母线电压）";
CM_ SG_ 800 EAC_Speed "Compressor speed
电动压缩机控制器当前运行速度";
CM_ SG_ 806 APTC_WorkSts "APTC工作状态";
CM_ SG_ 806 APTC_WorkPower "APTC实际工作功率";
CM_ SG_ 806 APTC_SurfaceTemp "APTC表面温度";
CM_ SG_ 806 APTC_PCBTemp "PCB板温度信号";
CM_ SG_ 806 APTC_Curent "APTC当前运行电流";
CM_ SG_ 806 APTC_ErrorCode "APTC运行故障代码";
CM_ SG_ 806 APTC_HVSts "APTC高压供电状态";
CM_ SG_ 806 APTC_ErrorLevel "APTC故障等级";
CM_ SG_ 928 ICM_ODOTotal "ODO 总里程 ";
CM_ SG_ 928 ICM_DisPlayVehicleSpeed "Current Display Vehicle Speed
仪表当前显示车速";
CM_ SG_ 928 ICM_LowBrakeFluidLevel "制动液位低";
CM_ SG_ 928 ICM_WashingLiquidLevel "洗涤液位低";
CM_ SG_ 928 ICM_maintenanceState "整车保养状态";
CM_ SG_ 928 ICM_instantaneous_power "瞬时功率";
CM_ SG_ 928 ICM_ODOTotalFB "ICM反馈的TBOX下发的总里程是否处理成功";
CM_ SG_ 928 ICM_Error_Sts "ICM故障状态";
CM_ SG_ 928 ICM_PrevmaintmileagesFB "ICM反馈的TBOX下发的保养里程是否处理成功";
CM_ SG_ 928 ICM_Display_Mode "ICM白天夜晚模式切换";
CM_ SG_ 928 ICM_SubMileage_Reset "小计里程重置";
CM_ SG_ 896 RLS_RQ_LowBeam "Auto low beam request 近光灯点亮请求，BCM接收LIN1子网RLS_0x23报文RLS_RQ_LowBeam信号转发至Body CAN";
CM_ SG_ 896 RB_Hall_error "霍尔故障,BCM接收LIN1子网RB_0x07报文RB_Hall_error信号转发至Body CAN";
CM_ SG_ 896 RB_Relay_error "继电器故障,BCM接收LIN1子网RB_0x07报文RRB_Relay_error信号转发至Body CAN";
CM_ SG_ 896 RB_ResponseError "RB LIN通信错误,BCM接收LIN1子网RB_0x07报文RB_ResponseError信号转发至Body CAN";
CM_ SG_ 896 RB_RunningStatus "遮阳帘运行状态标志位,BCM接收LIN1子网RB_0x07报文RB_RunningStatus信号转发至Body CAN";
CM_ SG_ 896 RB_Initialization_Status "初始化标志位,BCM接收LIN1子网RB_0x07报文RB_Initialization_Statusy信号转发至Body CAN";
CM_ SG_ 896 RLS_Fault_Rain "Rain sensor fault status 雨量传感器故障状态,BCM接收LIN1子网RLS_0x23报文RLS_Fault_Rain信号转发至Body CAN";
CM_ SG_ 896 RB_Position "遮阳帘开启百分比,BCM接收LIN1子网RB_0x07报文RB_Position信号转发至Body CAN";
CM_ SG_ 896 RLS_Brightness_FW "The Visible Ambientlight (540nm) measured by Spot FW 可见环境光亮度,BCM接收LIN1子网RLS_0x23报文RLS_Brightness_FW信号转发至Body CAN";
CM_ SG_ 896 RLS_Fault_Light "Light sensor fault status 光亮传感器故障状态,BCM接收LIN1子网RLS_0x23报文RLS_Fault_Light信号转发至Body CAN";
CM_ SG_ 896 RLS_ResponseError "RLS LIN response error RLS通讯故障状态,BCM接收LIN1子网RLS_0x23报文RLS_ResponseError 信号转发至Body CAN";
CM_ SG_ 896 RLS_Rain_Intensity "This signal delivers information about rain intensity: from 0%(no rain) to 100% (very heavy rain) 降雨强度：从0%到100%,BCM接收LIN1子网RLS_0x23报文RLS_Rain_Intensity信号转发至Body CAN";
CM_ SG_ 896 RB_Reversiering "遮阳帘反转标志位 （参考法规要求：GB115522009-乘用车内部突起物）,BCM接收LIN1子网RB_0x07报文RB_Reversiering信号转发至Body CAN";
CM_ SG_ 896 RB_Thermalprotection "热保护标志位,BCM接收LIN1子网RB_0x07报文RB_Thermalprotection信号转发至Body CAN";
CM_ SG_ 896 RB_UBat_LowVoltage "遮阳帘电机欠压,BCM接收LIN1子网RB_0x07报文RB_UBat_LowVoltage信号转发至Body CAN";
CM_ SG_ 896 RB_UBat_OverVoltage "遮阳帘电机过压,BCM接收LIN1子网RB_0x07报文RB_UBat_OverVoltage转发至Body CAN";
CM_ SG_ 896 RB_OpenKey_Status "遮阳帘打开按键状态,BCM接收LIN1子网RB_0x07报文RB_OpenKey_Status信号转发至Body CAN";
CM_ SG_ 896 RB_CloseKey_Status "遮阳帘关闭按键状态,BCM接收LIN1子网RB_0x07报文RB_CloseKey_Status信号转发至Body CAN";
CM_ SG_ 784 BCM_SystemPowerMode "整车电源状态
vehicle Power Status";
CM_ SG_ 784 BCM_AntiThelf_Sts "车辆设防状态";
CM_ SG_ 784 BCM_DriverLock_Sts "驾驶侧门锁状态";
CM_ SG_ 784 BCM_StartRequest "发动机启动请求信号（默认发0x0，请求启动时发0x1，连续发10帧，之后重新发0x0）";
CM_ SG_ 784 BCM_partialarmed_ActiveSts "局部设防激活状态";
CM_ SG_ 784 BCM_Hood_Sts "前舱盖状态";
CM_ SG_ 784 BCM_ChargerLock_ControlSts "充电口锁控制输出状态";
CM_ SG_ 784 BCM_PositionLight_Sts "位置灯状态";
CM_ SG_ 784 BCM_TurnLeftLight_Sts "左转向灯状态";
CM_ SG_ 784 BCM_TurnRightLight_Sts "右转向灯状态";
CM_ SG_ 784 BCM_Daylight_Sts "日间行车灯状态";
CM_ SG_ 784 BCM_HighBeam_Sts "远光灯状态";
CM_ SG_ 784 BCM_LowBeam_Sts "近光灯状态";
CM_ SG_ 784 BCM_AutoHeadlight_Sts "BCM反馈的是否执行HU 的Auto灯请求信号";
CM_ SG_ 784 BCM_brakeLight_Sts "制动灯状态";
CM_ SG_ 784 BCM_HazardLight_Sts "危险报警指示灯状态";
CM_ SG_ 784 BCM_RearFoglight_Sts "后雾灯状态";
CM_ SG_ 784 BCM_BrkSw_Sts "BCM采集的制动踏板开关状态";
CM_ SG_ 784 BCM_FL_Door_Sts "左前门状态";
CM_ SG_ 784 BCM_FR_Door_Sts "右前门状态";
CM_ SG_ 784 BCM_RL_Door_Sts "左后门状态";
CM_ SG_ 784 BCM_RR_Door_Sts "右后门状态";
CM_ SG_ 784 BCM_Trunk_Door_Sts "后背门状态（低配）";
CM_ SG_ 784 BCM_PLGOutsideSW "BCM采集的后背门外侧开关信号";
CM_ SG_ 784 BCM_HornControlsts "鸣笛控制状态";
CM_ SG_ 784 BCM_Fwiper_Mist_Sts "前雨刮点动状态";
CM_ SG_ 784 BCM_Fwiper_washing_Sts "前雨刮洗涤状态";
CM_ SG_ 784 BCM_FWiper_Sts "前雨刮状态";
CM_ SG_ 784 BCM_RWiper_Sts "后雨刮状态";
CM_ SG_ 784 BCM_RearViewFoldSts "外后视镜折叠状态（控制状态非实际状态）";
CM_ SG_ 784 BCM_RearViewAutoSWSts "外后视镜自动折叠功能使能状态";
CM_ SG_ 784 BCM_RearViewHeatSts "外后视镜加热/后除霜状态";
CM_ SG_ 784 BCM_WorkMode "BCM工作模式";
CM_ SG_ 784 BCM_TBOXUnlockEnableSts "TBOX发解锁命令后，BCM反馈的解锁使能状态";
CM_ SG_ 784 BCM_FwiperServiceSWsts "雨刮维修模式状态";
CM_ SG_ 784 BCM_SupplyVoltage "BCM供电电压";
CM_ SG_ 784 BCM_PowerONorOFF_Reason "BCM上电(（ACC或者IG1继电器从断开到闭合）及下电（ACC或者IG1继电器从闭合到断开）原因";
CM_ SG_ 665 FLWM_DenormalizeSt "DTC shall be logged into BCM/master in
case error active，BCM接收LIN3上FLWM_DenormalizeSt信号转发到Body CAN";
CM_ SG_ 665 FRWM_DenormalizeSt "DTC shall be logged into BCM/master in
case error active，BCM接收LIN3上FRWM_DenormalizeSt信号转发到Body CAN";
CM_ SG_ 665 RLWM_DenormalizeSt "DTC shall be logged into BCM/master in
case error active，BCM接收LIN3上RLWM_DenormalizeSt信号转发到Body CAN";
CM_ SG_ 665 RRWM_DenormalizeSt "DTC shall be logged into BCM/master in
case error active，BCM接收LIN3上RRWM_DenormalizeSt信号转发到Body CAN";
CM_ SG_ 665 CSW_Key_LiftGate "后背门开启按钮状态，BCM接收LIN2子网报文CSW_0x21的信号CSW_Key_LiftGate转发至Body CAN";
CM_ SG_ 665 CSW_WindowLOCK "车窗锁止按钮状态，BCM接收LIN2子网报文CSW_0x21的信号CSW_WindowLOCK转发至Body CAN";
CM_ SG_ 665 CSW_Key_FrontDefrost "前风窗除雾按钮状态，BCM接收LIN2子网报文CSW_0x21的信号CSW_Key_FrontDefrost转发至Body CAN";
CM_ SG_ 665 RLWM_WindowLOCKSts "RLWM车窗锁止状态,BCM接收LIN3子网RLWM_WindowLOCKSts的信号转发至Body CAN";
CM_ SG_ 665 RRWM_WindowLOCKSts "RRWM车窗锁止状态,BCM接收LIN3子网RRWM_WindowLOCKSts的信号转发至Body CAN";
CM_ SG_ 665 ESCL_DiagError "ESCL Diag Error，BCM接收LIN2子网报文ESCL_0x3B的信号ESCL_DiagError转发至Body CAN";
CM_ SG_ 665 ESCL_authentification_error "ESCL authentification error，BCM接收LIN2子网报文ESCL_0x3B的信号ESCL_authentification_error转发至Body CAN";
CM_ SG_ 665 ESCL_unlock_status "ESCL unlock status，BCM接收LIN2子网报文ESCL_0x3B的信号ESCL_unlock_status转发至Body CAN";
CM_ SG_ 665 ESCL_lock_status "ESCL lock status，BCM接收LIN2子网报文ESCL_0x3B的信号ESCL_lock_status转发至Body CAN";
CM_ SG_ 665 FLWM_WinPstSt "FLWindow Position Status，BCM接收LIN3子网报文FLWM_0x31的信号FLWM_WinPstSt转发至Body CAN";
CM_ SG_ 665 FLWM_AntiPinchDetecte "FLWindow检测到防夹，或正在进行防夹操作，BCM接收LIN3子网报文FLWM_0x31的信号FLWM_AntiPinchDetecte转发至Body CAN";
CM_ SG_ 665 FRWM_WinPstSt "FRWindow Position Status，BCM接收LIN3子网报文FRWM_0x32的信号FRWM_WinPstSt转发至Body CAN";
CM_ SG_ 665 FRWM_AntiPinchDetecte "FRWindow检测到防夹，或正在进行防夹操作，BCM接收LIN3子网报文FRWM_0x32的信号FRWM_AntiPinchDetecte转发至Body CAN";
CM_ SG_ 665 RLWM_WinPstSt "RLWindow Position Status，BCM接收LIN3子网报文RLWM_0x33的信号RLWM_WinPstStp转发至Body CAN";
CM_ SG_ 665 RLWM_AntiPinchDetecte "RLWindow检测到防夹，或正在进行防夹操作，BCM接收LIN3子网报文RLWM_0x33的信号RLWM_AntiPinchDetecte转发至Body CAN";
CM_ SG_ 665 RRWM_WinPstSt "RRWindow Position Status，BCM接收LIN3子网报文RRWM_0x34的信号RRWM_WinPstSt转发至Body CAN";
CM_ SG_ 665 RRWM_AntiPinchDetecte "RRWindow检测到防夹，或正在进行防夹操作，BCM接收LIN3子网报文RRWM_0x34的信号RRWM_AntiPinchDetect转发至Body CAN";
CM_ SG_ 665 FLWM_Opend "左前车窗是否完全打开，BCM接收LIN3子网报文FLWM_0x31的信号FLWM_Opend转发至Body CAN";
CM_ SG_ 665 FLWM_Closed "左前车窗是否完全关闭，BCM接收LIN3子网报文FLWM_0x31的信号FLWM_Closed转发至Body CAN";
CM_ SG_ 665 FRWM_Opend "右前车窗是否完全打开，BCM接收LIN3子网报文FRWM_0x32的信号FRWM_Opend转发至Body CAN";
CM_ SG_ 665 FRWM_Closed "右前车窗是否完全关闭，BCM接收LIN3子网报文FRWM_0x32的信号FRWM_Closed转发至Body CAN";
CM_ SG_ 665 RLWM_Opend "左后车窗是否完全打开，BCM接收LIN3子网报文RLWM_0x33的信号RLWM_Opend转发至Body CAN";
CM_ SG_ 665 RLWM_Closed "左后车窗是否完全关闭，BCM接收LIN3子网报文RLWM_0x33的信号RLWM_Closed转发至Body CAN";
CM_ SG_ 665 RRWM_Opend "右后车窗是否完全打开，BCM接收LIN3子网报文RRWM_0x34的信号RRWM_Opend转发至Body CAN";
CM_ SG_ 665 RRWM_Closed "右后车窗是否完全关闭，BCM接收LIN3子网报文RRWM_0x34的信号RRWM_Closed转发至Body CAN";
CM_ SG_ 665 FLWM_WinMoveSt "FLWindow move Status，BCM接收LIN3子网报文FLWM_0x31的信号FLWM_WinMoveSt转发至Body CAN";
CM_ SG_ 665 FRWM_WinMoveSt "FRWindow move Status，BCM接收LIN3子网报文FRWM_0x32的信号FRWM_WinMoveSt转发至Body CAN";
CM_ SG_ 665 RLWM_WinMoveSt "RLWindow move Status，BCM接收LIN3子网报文RLWM_0x33的信号RLWM_WinMoveSt转发至Body CAN";
CM_ SG_ 665 RRWM_WinMoveSt "RRWindow move Status，BCM接收LIN3子网报文RRWM_0x34的信号RRWM_WinMoveStp转发至Body CAN";
CM_ SG_ 583 BCM_StartWarning "启动异常提醒";
CM_ SG_ 583 BCM_PowerOffWarning "下OFF异常提醒";
CM_ SG_ 583 BCM_PowerONWarning "上电异常提醒";
CM_ SG_ 583 BCM_AuthSts "BCM一级防盗认证结果";
CM_ SG_ 583 BCM_ESCLSysFail "ESCL系统故障提醒";
CM_ SG_ 583 BCM_LODO_Reminder "灯关未关闭提醒";
CM_ SG_ 583 BCM_brakeLightfail "刹车灯故障提示";
CM_ SG_ 583 BCM_HoodOpen_Feedback "前舱盖未关状态";
CM_ SG_ 583 BCM_TrunkOpen_Feedback "后行李箱未关状态";
CM_ SG_ 583 BCM_Drivedoorlcok_Feedback "主驾车门未锁状态";
CM_ SG_ 583 BCM_FLDoorOpen_Feedback "左前车门未关状态";
CM_ SG_ 583 BCM_FRDoorOpen_Feedback "右前车门未关状态";
CM_ SG_ 583 BCM_RRDoorOpen_Feedback "右后车门未关状态";
CM_ SG_ 583 BCM_RLDoorOpen_Feedback "左后车门未关状态";
CM_ SG_ 583 BCM_FLWindowOpen_Feedback "左前车窗未关状态";
CM_ SG_ 583 BCM_FRWindowOpen_Feedback "右前车窗未关状态";
CM_ SG_ 583 BCM_RRWindowOpen_Feedback "右后车窗未关状态";
CM_ SG_ 583 BCM_RLWindowOpen_Feedback "左后车窗未关状态";
CM_ SG_ 1282 TPMS_FL_Warning_Sts "左前胎压报警状态";
CM_ SG_ 1282 TPMS_FR_Warning_Sts "右前胎压报警状态";
CM_ SG_ 1282 TPMS_RL_Warning_Sts "左后胎压报警状态";
CM_ SG_ 1282 TPMS_RR_Warning_Sts "右后胎压报警状态";
CM_ SG_ 1282 TPMS_FL_Fault_Sts "左前胎压故障状态";
CM_ SG_ 1282 TPMS_FR_Fault_Sts "右前胎压故障状态";
CM_ SG_ 1282 TPMS_RL_Fault_Sts "左后胎压故障状态";
CM_ SG_ 1282 TPMS_RR_Fault_Sts "右后胎压故障状态";
CM_ SG_ 1282 TPMS_FL_leakage_Sts "左前轮胎漏气状态";
CM_ SG_ 1282 TPMS_FR_leakage_Sts "右前轮胎漏气状态";
CM_ SG_ 1282 TPMS_RL_leakage_Sts "左后轮胎漏气状态";
CM_ SG_ 1282 TPMS_RR_leakage_Sts "右后轮胎漏气状态";
CM_ SG_ 1282 TPMS_FLPressure_Sts "左前轮胎胎压状态";
CM_ SG_ 1282 TPMS_FRPressure_Sts "右前轮胎胎压状态";
CM_ SG_ 1282 TPMS_RLPressure_Sts "左后轮胎胎压状态";
CM_ SG_ 1282 TPMS_RRPressure_Sts "右后轮胎胎压状态";
CM_ SG_ 1282 TPMS_FL_HighTemp_Sts "左前高温报警状态";
CM_ SG_ 1282 TPMS_FR_HighTemp_Sts "右前高温报警状态";
CM_ SG_ 1282 TPMS_RL_HighTemp_Sts "左后高温报警状态";
CM_ SG_ 1282 TPMS_RR_HighTemp_Sts "右后高温报警状态";
CM_ SG_ 1282 TPMS_FL_battery_Sts "左前电池电量低报警状态";
CM_ SG_ 1282 TPMS_FR_battery_Sts "右前电池电量低报警状态";
CM_ SG_ 1282 TPMS_RL_battery_Sts "左后电池电量低报警状态";
CM_ SG_ 1282 TPMS_RR_battery_Sts "右后电池电量低报警状态";
CM_ SG_ 1282 TPMS_FL_SensorError_Sts "左前胎压传感器信号故障";
CM_ SG_ 1282 TPMS_FR_SensorError_Sts "右前胎压传感器信号故障";
CM_ SG_ 1282 TPMS_RL_SensorError_Sts "左后胎压传感器信号故障";
CM_ SG_ 1282 TPMS_RR_SensorError_Sts "右后胎压传感信号故障";
CM_ SG_ 1282 TPMS_FL_failure_Sts "左前传感器信号丢失";
CM_ SG_ 1282 TPMS_FR_failure_Sts "右前传感器信号丢失";
CM_ SG_ 1282 TPMS_RL_failure_Sts "左后传感器信号丢失";
CM_ SG_ 1282 TPMS_RR_failure_Sts "右后传感器信号丢失";
CM_ SG_ 1282 TPMS_FL_learn_Sts "左前匹配状态";
CM_ SG_ 1282 TPMS_FR_learn_Sts "右前匹配状态";
CM_ SG_ 1282 TPMS_RL_learn_Sts "左后匹配状态";
CM_ SG_ 1282 TPMS_RR_learn_Sts "右后匹配状态";
CM_ SG_ 1282 TPMS_FL_CRC_Error "TPMS FL传感器数据CRC校验错误";
CM_ SG_ 1282 TPMS_FR_CRC_Error "TPMS FR传感器数据CRC校验错误";
CM_ SG_ 1282 TPMS_RL_CRC_Error "TPMS RL传感器数据CRC校验错误";
CM_ SG_ 1282 TPMS_RR_CRC_Error "TPMS RR传感器数据CRC校验错误";
CM_ SG_ 804 MCU_FailCode1 "故障码1";
CM_ SG_ 804 MCU_FailCode2 "故障码2";
CM_ SG_ 804 MCU_FailCode3 "故障码3";
CM_ SG_ 804 MCU_FailCode4 "故障码4";
CM_ SG_ 835 PLG_Trunk_Sts "后背门状态";
CM_ SG_ 835 PLG_Shutface_SW "后背门内侧关门开关状态";
CM_ SG_ 835 PLG_Latc_PawlSW "后背门锁（一级锁位）开关状态，后背门开关状态";
CM_ SG_ 835 PLG_Latch_SecondarySW "后背门锁（二级锁位）开关状态";
CM_ SG_ 835 PLG_Latch_0PositionSW "后背门自吸锁复位开关状态";
CM_ SG_ 835 PLG_LearnedSts "PLG学习状态";
CM_ SG_ 835 PLG_KickActiveReq "脚踢信号有效请求";
CM_ SG_ 835 PLG_HallSensor "霍尔传感器状态";
CM_ SG_ 835 PLG_OpenAng "尾门开度";
CM_ SG_ 835 PLG_OpenAngValid "尾门开度有效性";
CM_ SG_ 835 PLG_GaragePosition "Reset Garage Position车库高度";
CM_ SG_ 835 PLG_LatchMorSts "LatchMor，锁电机状态";
CM_ SG_ 835 PLG_GearMor1Sts "GearMor1，撑杆电机1状态";
CM_ SG_ 835 PLG_GearMor2Sts "GearMor2，撑杆电机2状态";
CM_ SG_ 835 PLG_mode "PLG工作模式";
CM_ SG_ 835 PLG_TBOXUnlockEnableSts "TBOX发解锁命令后，PLG反馈的解锁使能状态";
CM_ SG_ 835 PLG_Fault "PLG故障信号";
CM_ SG_ 835 PLG_FaultSts "PLG故障状态";
CM_ SG_ 774 VBU_BMS_RemainChargingTime "剩余充电时间";
CM_ SG_ 774 VBU_BMS_Charing_Time "本次充电时长";
CM_ SG_ 774 VBU_BMS_Charging_Ah "本次充入容量";
CM_ SG_ 774 VBU_BMS_TotalUsed_Ah "充放电累计吞吐安时";
CM_ SG_ 774 VBU_BMS_Charging_Energy "本次充入能量";
CM_ SG_ 528 Checksum_0x210 "Checksum: IDMSB XOR IDLSB XOR Byte1 XOR Byte2 XOR Byte3 XOR Byte4 XOR Byte5 XOR Byte6XOR Byte7";
CM_ SG_ 528 ACU_CrashStatus "ACU output crash status
";
CM_ SG_ 528 ACU_AirBagFailSts "Airbag fail Warning Lamp status
安全气囊故障报警灯";
CM_ SG_ 528 ACU_SBR_Driver "Drive Buckle stauts/ SBR status 
主驾安全带未系提醒";
CM_ SG_ 528 ACU_SBR_Passenger "Passenger Buckle stauts/ SBR status 
前排副驾驶安全带未系提醒";
CM_ SG_ 528 ACU_SBR_RLPassenger "RL Passenger Buckle stauts/ SBR status 
后排左侧安全带未系提醒";
CM_ SG_ 528 ACU_SBR_MidPassenger "Mid Passenger Buckle stauts/ SBR status  
后排中间安全带未系提醒";
CM_ SG_ 528 ACU_SBR_RRPassenger "RR Passenger Buckle stauts/ SBR status 
后排右侧安全带未系提醒";
CM_ SG_ 528 ACU_DrvSeatBeltSWSts "Driver Buckle Switch status 
主驾安全带未开关状态";
CM_ SG_ 528 ACU_PsSeatBeltSWSts "Passenger Buckle Switch status
前排副驾驶安全带开关状态";
CM_ SG_ 528 ACU_RLPsSeatBeltSWSts "RL Passenger Buckle Switch status 
后排左侧安全带开关状态";
CM_ SG_ 528 ACU_MidPsSeatBeltSWSts "Mid Passenger  Buckle Switch status 
后排中间安全带开关状态";
CM_ SG_ 528 ACU_RRPsSeatBeltSWSts "RR Passenger Buckle Switch status
后排右侧安全带开关状态";
CM_ SG_ 528 RollingCounter_0x210 "从0到15循环计数，如果通信中断，则重新从0开始计数。";
CM_ SG_ 596 AC_SystemSts "空调开关状态";
CM_ SG_ 596 AC_CycleSts "空调内外循环";
CM_ SG_ 596 AC_EACSts "压缩机开关状态";
CM_ SG_ 596 AC_AutoModeSts "空调Auto模式";
CM_ SG_ 596 AC_APTC_StartStop "APTC的启停控制命令";
CM_ SG_ 596 AC_StartStopEAC "Start or stop the Compressor 
电动压缩机起停控制命令";
CM_ SG_ 596 AC_EAC_AimSpeed "压缩机目标转速";
CM_ SG_ 596 AC_WindModeSts "当前吹风模式";
CM_ SG_ 596 AC_BlowingRateSts "当前风量状态";
CM_ SG_ 596 AC_APTCSWsts "APTC开关状态";
CM_ SG_ 596 AC_SysFaultsts "AC系统故障状态";
CM_ SG_ 596 AC_InTemperature "车内温度";
CM_ SG_ 596 AC_OutTemperature "车外温度";
CM_ SG_ 596 AC_PM25Value "PM2.5值";
CM_ SG_ 596 AC_BatCoolingValve "chiller电磁热力膨胀阀状态";
CM_ SG_ 596 AC_ComftCoolingValve "乘员舱电磁热力膨胀阀状态";
CM_ SG_ 596 AC_FdefrostSts "最大前除霜除雾状态";
CM_ SG_ 1009 DVR_Sdcard_Sts "SD卡状态";
CM_ SG_ 1009 DVR_DrivingRecord "行车记录";
CM_ SG_ 1009 DVR_VideoResolution "录像分辨率执行";
CM_ SG_ 1009 DVR_VideoTimeSts "录像时长设置状态";
CM_ SG_ 1009 DVR_ShutdownDelay "延时关机";
CM_ SG_ 1009 DVR_VideoCoverageSW "事件录像覆盖开关";
CM_ SG_ 1009 DVR_GSensorSensy "G-Sensor灵敏度";
CM_ SG_ 1009 DVR_ParkMonitor "停车监控";
CM_ SG_ 1009 DVR_TapeSwitch "录音开关";
CM_ SG_ 1009 DVR_HDRSwitch "宽动态开关";
CM_ SG_ 1009 DVR_DriveInfoOverlay "行驶信息叠加";
CM_ SG_ 1009 DVR_SdcardFormateSts "格式化SD卡状态";
CM_ SG_ 1009 DVR_FactoryDefaultSts "恢复出厂设置状态";
CM_ SG_ 1009 DVR_SystemSts "DVR系统状态";
CM_ SG_ 1009 DVR_ControlResult "DVR远程抓图控制命令返回状态";
CM_ SG_ 1009 DVR_GsensorCrashStatus "DVR检测到Gsensor的状态";
CM_ SG_ 1009 DVR_requestWiFiopen "DVR请求WiFi开启";
CM_ SG_ 1009 DVR_LocalTimelapseRecordResult "本地手动缩时录像返回结果";
CM_ SG_ 1009 DVR_Frameinterval "缩时录像抽帧间隔，1-255(s),录像时长=抽帧间隔*视频帧数";
CM_ SG_ 1009 DVR_FrameCount "缩时录像视频帧数,总抽帧数，取值范围:60-1800帧";
CM_ SG_ 1009 DVR_PlayRate "缩时录像播放帧率,每秒播放帧数，取值范围：1-30帧";
CM_ SG_ 1009 DVR_RemoteControlSts "DVR远程控制状态";
CM_ SG_ 676 DSM_EasyEntrySWSts "座椅迎宾功能设置反馈";
CM_ SG_ 676 DSM_DSMHeatSWsts "主驾加热功能开关反馈";
CM_ SG_ 676 DSM_GetMemoryRsp_Mirror "外后视镜记忆调用调节完成状态";
CM_ SG_ 676 DSM_GetMemoryRsp_Seat "座椅记忆调用调节完成状态";
CM_ SG_ 676 DSM_SLV_DirectionSts "主驾座椅前后调节电机（SLV）运动方向";
CM_ SG_ 676 DSM_SHV_DirectionSts "主驾座椅后部高度调节电机（SHV）运动方向";
CM_ SG_ 676 DSM_LNV_DirectionSts "支架靠背电机（LNV）运动方向";
CM_ SG_ 676 DSM_SLV_CalibrationSts "座椅前后调节电机（SLV）标定状态";
CM_ SG_ 676 DSM_SHV_CalibrationSts "座椅高度调节电机（SHV）标定状态";
CM_ SG_ 676 DSM_LNV_CalibrationSts "主驾靠背电机（LNV）标定状态";
CM_ SG_ 676 DSM_DSLV_MotorfaultSts "主驾座椅前后调节电机（SLV）故障状态";
CM_ SG_ 676 DSM_SLV_Position "主驾座椅前后调节电机（SLV）位置";
CM_ SG_ 676 DSM_DSHV_MotorfaultSts "主驾座椅高度调节电机（SHV）故障状态";
CM_ SG_ 676 DSM_SHV_Position "主驾座椅高度调节电机（SHV）位置";
CM_ SG_ 676 DSM_DSNV_MotorfaultSts "主驾靠背电机（LNV）故障状态";
CM_ SG_ 676 DSM_LNV_Position "主驾靠背电机（LNV）位置";
CM_ SG_ 676 DSM_PSMHeatfault "副驾加热功能故障";
CM_ SG_ 676 DSM_PSMHeatSWsts "副驾加热功能开关反馈";
CM_ SG_ 676 DSM_PSMheattemp "副驾驶侧座椅实际温度";
CM_ SG_ 676 DSM_DSMHeatfault "主驾加热功能故障";
CM_ SG_ 676 DSM_DSMheattemp "驾驶侧座椅实际温度";
CM_ SG_ 24 BCM_AuthReq_TBOX_NSM_Code "BCM 一级防盗Challenge Frame";
CM_ SG_ 25 TBOX_AuthResp_BCM_Code "TBOX一级防盗Response Frame";
CM_ SG_ 288 Checksum_0x120 "Checksum: IDMSB XOR IDLSB XOR Byte1 XOR Byte2 XOR Byte3 XOR Byte4 XOR Byte5 XOR Byte6 XOR Byte7";
CM_ SG_ 288 MCU_MotorActualTorque "电机实时输出扭矩";
CM_ SG_ 288 MCU_MILReq "MCU request Mil lamp
MCU请求亮故障灯";
CM_ SG_ 288 MCU_MotorSpeed "电机实时输出转速";
CM_ SG_ 288 MCU_AuthSts "MCU动力防盗认证结果";
CM_ SG_ 288 MCU_OverSpdWarning "电机超速报警";
CM_ SG_ 288 MCU_InverterTempWarning "电机控制器过温报警";
CM_ SG_ 288 MCU_MotorTempWarning "电机过温报警";
CM_ SG_ 288 MCU_OverTemp "MCU请求点亮电机过热灯";
CM_ SG_ 288 MCU_WorkSts "MCU实时工作状态";
CM_ SG_ 288 MCU_FaultLevel "故障等级";
CM_ SG_ 288 MCU_FaultLampOn "MCU请求点亮电机故障灯";
CM_ SG_ 288 MCU_HVLock "MCU高压互锁信号，适用后驱";
CM_ SG_ 288 Rollingcounter_0x120 "从0到15循环计数，如果通信中断，则重新从0开始计数。";
CM_ SG_ 290 Checksum_0x122 "Checksum: IDMSB XOR IDLSB XOR Byte1 XOR Byte2 XOR Byte3 XOR Byte4 XOR Byte5 XOR Byte6 XOR Byte7";
CM_ SG_ 290 MCU_MaxAvailableTorque "电机可输出最大电动扭矩";
CM_ SG_ 290 MCU_MinAvailableTorque "电机可输出最大发电扭矩";
CM_ SG_ 290 MCU_DeratingTempCoolant "冷却水过温降功率";
CM_ SG_ 290 MCU_damping_En "扭矩补偿标志位";
CM_ SG_ 290 MCU_DeratingTrqMin "发电超限降功率";
CM_ SG_ 290 MCU_DeratingTrqMax "电动超限降功率";
CM_ SG_ 290 MCU_DeratingOvrUdc "过压降功率";
CM_ SG_ 290 MCU_DeratingUndrUdc "欠压降功率";
CM_ SG_ 290 MCU_DeratingOvrIdc "过流降功率";
CM_ SG_ 290 MCU_DeratingUndrIdc "欠流降功率";
CM_ SG_ 290 MCU_DeratingTempEm "电机过温降功率";
CM_ SG_ 290 MCU_DeratingTempInv "控制器过温降功率";
CM_ SG_ 290 Rollingcounter_0x122 "从0到15循环计数，如果通信中断，则重新从0开始计数。";
CM_ SG_ 290 MCU_MotorTorDerLampReq "电机降扭矩点亮乌龟灯需求";
CM_ SG_ 290 MCU_HVReady "高压端预充完成";
CM_ SG_ 290 MCU_DeratingOverSpd "电机超速降功率";
CM_ SG_ 289 Checksum_0x121 "Checksum: IDMSB XOR IDLSB XOR Byte1 XOR Byte2 XOR Byte3 XOR Byte4 XOR Byte5 XOR Byte6 XOR Byte7";
CM_ SG_ 289 ESP_VehicleSpeed "Current Vehicle Speed
当前实际车速";
CM_ SG_ 289 ESP_VehicleSpeed_Valid "Vehicle speed value valid
车速有效";
CM_ SG_ 289 ESP_OFF "ESP is diabled by pata（ESP off）";
CM_ SG_ 289 ESP_ABS_Error "ABS_Fault: ESP system has detected a failure which does not allow a reliable ABS regulation and is therefore switched off";
CM_ SG_ 289 ESP_ABS_Intervention "ABS control active - Indication that ESP system (especially ABS module) currently performs a brake intervention";
CM_ SG_ 289 ESP_VDC_TCS_Error "ESP_Fault: VDC/TCS is switched off due to detected failure";
CM_ SG_ 289 ESP_EBD_Error "EBD_Fault: ESP system has detected a heavy fault, which does not even allow a reliable electronic brake distribution and is therefore completely shut down";
CM_ SG_ 289 ESP_VDC_Intervention "VDC controller active: Oversteering brake intervention or Understeering brake intervention";
CM_ SG_ 289 ESP_TCS_Intervention "TCS controller active: Brake intervention or Engine torque reduction intervention";
CM_ SG_ 289 ESP_EBD_Intervention "EBD control active - Indication that ESP system (especially EBD module) currently performs a brake intervention";
CM_ SG_ 289 ESP_HDC_Status "Indicating the status of HDC.";
CM_ SG_ 289 ESP_HDC_Available "HMI Responsible,CAN get degrateHDC statement from DSW and send out";
CM_ SG_ 289 ESP_EPBMainteDiagmodeActive "EPB Maintenance diagnosis mode status";
CM_ SG_ 289 ESP_EPBFailstatus "EPB failure status";
CM_ SG_ 289 ESP_EPBStatus "Indicating the status of EPB";
CM_ SG_ 289 ESP_VehicleStop "Indicates if vehicle is in standstill (if more or equal to two wheels are standstill).
Set to a desired state when standstill is surely reached.
";
CM_ SG_ 289 ESP_VehicleStop_Valid "Check the validity of the signal of VehicleStop.";
CM_ SG_ 289 ESP_MasterCyPressureCmp "Master cylinder pressure
Offset included";
CM_ SG_ 289 ESP_MasterCyPressure_Valid "Indicating MasterCyPressure valid or not";
CM_ SG_ 289 ESP_WheelCyBrakeForce_Exist "No brake pressure applied; Generally it indicates wheel cylinder presure.";
CM_ SG_ 289 ESP_ESPLamp "ESP或者TCS触发点亮仪表信号灯";
CM_ SG_ 289 ESP_AVHstandbyStatus "Indicates AVH in standby mode or not";
CM_ SG_ 289 ESP_AVHActive "Indicates AVH in active or not ";
CM_ SG_ 289 ESP_AVH_availalbe "HMI Responsible,CAN get degrateAVH statement from DSW and send out";
CM_ SG_ 289 ESP_HHC_Available "HHC  is available or not";
CM_ SG_ 289 ESP_HHCActive "Indicates HHCH in active or not ";
CM_ SG_ 289 RollingCounter_0x121 "RollingCounter: used 4bit length signal and the arithmetic is increased from 0 to 15 by every message.";
CM_ SG_ 289 ESP_HubDiagmodeActive "Indicates Hub diagnosis mode in active or not 
ESC转毂&诊断模式,点亮ABS和ESC黄灯 ";
CM_ SG_ 289 ESP_HAZ_Active "Emergency brake light on, 当减速度过大时，警告灯开启，提醒用户减速度过大 ";
CM_ SG_ 291 MCU_IsCurrent "实际定子电流有效值";
CM_ SG_ 291 MCU_DC_linkVoltage "直流母线电压";
CM_ SG_ 291 MCU_DC_linkCurrent "直流母线电流";
CM_ SG_ 291 MCU_InverterTemp "电机控制器温度";
CM_ SG_ 291 MCU_MotorTemp "电机定子温度";
CM_ SG_ 292 MCU_DBCTempU "U相DBC温度";
CM_ SG_ 292 MCU_DBCTempV "V相DBC温度";
CM_ SG_ 292 MCU_DBCTempW "W相DBC温度";
CM_ SG_ 292 MCU_RotorTemp "电机转子温度";
CM_ SG_ 292 MCU_MotoroffsetSts "电机转子偏移角度状态";
CM_ SG_ 292 MCU_stGateDrv "逆变器状态";
CM_ SG_ 292 MCU_Motoroffset "电机转子偏移角度";
CM_ SG_ 545 TBOX_BT_Key_valid "TBOX蓝牙钥匙信息";
CM_ SG_ 545 TBOX_WorkModeCMD "TBOX控制状态";
CM_ SG_ 545 TBOX_Locate_F "TBOX定位异常故障";
CM_ SG_ 545 TBOX_Networking_F "TBOX联网异常故障";
CM_ SG_ 545 TBOX_Memory_F "TBOX存储故障";
CM_ SG_ 545 TBOX_WelcomefuncReq "迎宾功能请求（Tbox检测到蓝牙钥匙从未连接上到连接上并且有效时刻发3帧0x1后回到0x0,发送此信号时，TBOX的NM报文不能请求休眠）";
CM_ SG_ 545 TBOX_Timer_out "TBOX定时器";
CM_ SG_ 545 TBOX_FOTA_mode_ALL "TBOX  FOTA模式";
CM_ SG_ 545 TBOX_ECALL_mode_ALL "TBOX  ECALL模式（HU使用，用于出现碰撞事件的时候，唤醒HU，保证HU能播放电话语音）";
CM_ SG_ 545 TBOX_DVR_RemoteFunctionCtrl "TBOX远程控制DVR功能（TBOX上电发送30S default值，之后发送实际开启/关闭值）";
CM_ SG_ 545 TBOX_DischargeDepthSet "TBOX放电深度设置（有控制需求时触发一次以100ms周期发送5帧设置值后返回发0x7F）";
CM_ SG_ 545 TBOX_RemoteCharge_EndHour "TBOX 发送的预约充电结束时间----时";
CM_ SG_ 545 TBOX_RemoteCharge_Full_SetSts "TBOX 反馈给 HU 及 APP 的是否充满设置状 态";
CM_ SG_ 545 TBOX_RemoteCharge_Endmin "TBOX 发送的预约充电结束时间----分钟";
CM_ SG_ 545 TBOX_RemoteCharge_wakeup_SetSts "TBOX唤醒远程充电设置状态";
CM_ SG_ 599 Checksum_0x257 "Checksum: IDMSB XOR IDLSB XOR Byte1 XOR Byte2 XOR Byte3 XOR Byte4 XOR Byte5 XOR Byte6 XOR Byte7（适用纯电和增程）";
CM_ SG_ 599 AC_RemoteAC "空调远程控制请求（适用纯电和增程）";
CM_ SG_ 599 AC_RemoteACFeedback "远程空调反馈（适用纯电和增程）";
CM_ SG_ 599 AC_Temp_setvalue "温度调节设置值（适用纯电和增程）";
CM_ SG_ 599 AC_SolarIntensity "光照强度（适用纯电和增程）";
CM_ SG_ 599 AC_OutTemperature_Error "室外温度传感器电路故障状态（适用纯电和增程）";
CM_ SG_ 599 AC_OutTemperature_raw "室外温度原始电压值（适用纯电和增程）";
CM_ SG_ 599 AC_VBU_ComfortheatReqLvl "乘员舱加热请求等级（适用增程）";
CM_ SG_ 599 AC_OutPM25Value "室外PM2.5值（适用纯电和增程）";
CM_ SG_ 599 RollingCounter_0x257 "RollingCounter: used 4bit length signal and the arithmetic is increased from 0 to 15 by every message.（适用纯电和增程）";
CM_ SG_ 849 TBOX_BCM_DoorLock_Control_4G "远程APP四门解闭锁信号
(无控制请求时，发送0x0。当激活控制命令时，发送0x1/0x2。连续发送3次，之后将控制信号重新置0x0)";
CM_ SG_ 849 TBOX_BCM_CarLocating "双闪或者鸣笛开启
(无控制请求时，发送0x0。当激活控制命令时，发送0x1/0x2/0x3/0x4。连续发送3次，之后将控制信号重新置0x0)";
CM_ SG_ 849 TBOX_PLG_TrunkunLock "后备箱解闭锁信号,
(无控制请求时，发送0x0。当激活控制命令时，发送0x1。连续发送3次，之后将控制信号重新置0x0，高配PLG执行，低配BCM执行)";
CM_ SG_ 849 TBOX_DSM_heatSwitch "驾驶侧座椅远程加热开关
(无控制请求时，发送0x0。当激活控制命令时，发送0x1/0x2。连续发送3次，之后将控制信号重新置0x0)";
CM_ SG_ 849 TBOX_PSM_heatSwitch "副驾驶侧座椅远程加热开关
(无控制请求时，发送0x0。当激活控制命令时，发送0x1/0x2。连续发送3次，之后将控制信号重新置0x0)";
CM_ SG_ 849 TBOX_BCM_DoorLock_Control_BT "本地蓝牙钥匙四门解闭锁信号
(无控制请求时，发送0x0。当激活控制命令时，发送0x1/0x2。连续发送3次，之后将控制信号重新置0x0)";
CM_ SG_ 849 TBOX_DSM_Targtemp "驾驶侧座椅远程加热目标温度,
（开启状态可以选择发送目标温度）";
CM_ SG_ 849 TBOX_welcomefuncReqsts "迎宾功能使能状态";
CM_ SG_ 849 TBOX_Publish_Wakeup "TBOX推动消息唤醒HU";
CM_ SG_ 849 TBOX_PSM_Targtemp "副驾驶侧座椅远程加热目标温度
（开启状态可以选择发送目标温度）";
CM_ SG_ 849 TBOX_RB_Initialization "TBOX触发的遮阳帘自学习信号";
CM_ SG_ 849 TBOX_BCM_PowerON_Request "上电请求发给BCM
(无控制请求时，发送0x0。当激活控制命令时，发送0x1/0x2/0x3。连续发送5次，之后将控制信号重新置0x0)";
CM_ SG_ 849 TBOX_BCM_PowerON_limit "禁止上电请求
";
CM_ SG_ 849 TBOX_RB_Position_Req "TBOX触发的遮阳帘位置控制信号,";
CM_ SG_ 849 TBOX_BCM_FLWindowsControl "左前车窗远程控制信号
(无控制请求时，发送0x0。当激活控制命令时，发送0x1/0x2/0x3。连续发送3次，之后将控制信号重新置0x0)";
CM_ SG_ 849 TBOX_BCM_FRWindowsControl "右前车窗远程控制信号(无控制请求时，发送0x0。当激活控制命令时，发送0x1/0x2/0x3。连续发送3次，之后将控制信号重新置0x0)";
CM_ SG_ 849 TBOX_BCM_RLWindowsControl "左后车窗远程控制信号(无控制请求时，发送0x0。当激活控制命令时，发送0x1/0x2/0x3。连续发送3次，之后将控制信号重新置0x0)";
CM_ SG_ 849 TBOX_BCM_RRWindowsControl "右后车窗远程控制信号(无控制请求时，发送0x0。当激活控制命令时，发送0x1/0x2/0x3。连续发送3次，之后将控制信号重新置0x0)";
CM_ SG_ 850 TBOX_AC_SystemSet "空调开关";
CM_ SG_ 850 TBOX_AC_Cycle "空调内外循环";
CM_ SG_ 850 TBOX_AC_EAC_Control "压缩机开关";
CM_ SG_ 850 TBOX_AC_AutoMode_Set "Auto模式";
CM_ SG_ 850 TBOX_AC_WindMode_Set "吹风模式";
CM_ SG_ 850 TBOX_AC_FDefrostMode_Set "前除霜除雾模式";
CM_ SG_ 850 TBOX_AC_BlowingRate_Set "风量调节";
CM_ SG_ 850 TBOX_AC_APTCSW_Set "APTC开关";
CM_ SG_ 850 TBOX_AC_Temp_set "温度调节";
CM_ SG_ 850 TBOX_HU_rebootACK "tbox reboot 应答";
CM_ SG_ 850 TBOX_RemotePhotograph "APP远程开启远程拍照
(无控制请求时，发送0x0。当激活控制命令时，发送0x1/0x2/0x3。连续发送3次，之后将控制信号重新置0x0)";
CM_ SG_ 850 TBOX_ChargeCtrl_Setsts "TBOX响应的立即或定时充电选择状态";
CM_ SG_ 850 TBOX_PLG_OpenControl "APP控制PLG打开关闭信号";
CM_ SG_ 850 TBOX_RemoteCharge_StartHour "APP发送的预约充电开启时间----时
0x0-0x17: Hour
0x18-0x1F: Invalid";
CM_ SG_ 850 TBOX_RemoteCharge_Setsts "定时充电开启设置状态";
CM_ SG_ 850 TBOX_RemoteCharge_Startmin "APP发送的预约充电开启时间----分
0x0-0x3B: Minute
0x3C-0x3F: Invalid
";
CM_ SG_ 850 TBOX_BCM_FLWindowsVoiControl "左前车窗控制信号";
CM_ SG_ 850 TBOX_BCM_FRWindowsVoiControl "右前车窗控制信号";
CM_ SG_ 850 TBOX_BCM_RLWindowsVoiControl "左后车窗控制信号";
CM_ SG_ 850 TBOX_BCM_RRWindowsVoiControl "右后车窗控制信号";
CM_ SG_ 851 Checksum_0x353 "Checksum: IDMSB XOR IDLSB XOR Byte1 XOR Byte2 XOR Byte3 XOR Byte4 XOR Byte5 XOR Byte6 XOR Byte7";
CM_ SG_ 851 TBOX_RemoteChargetime "远程充电时间设置
(无控制请求时，发送0x0。当激活控制命令时，发送0x1-0x3ff。连续发送3次，之后将控制信号重新置0x0)";
CM_ SG_ 851 TBOX_VBU_12vChargeReq "小电瓶充电请求
(无控制请求时，发送0x0。当激活控制命令时，发送0x1。连续发送5次，之后将控制信号重新置0x0)";
CM_ SG_ 851 TBOX_VBU_TimeCharge "定时充电请求信号";
CM_ SG_ 851 TBOX_BTKey_valid "TBOX蓝牙钥匙连接状态";
CM_ SG_ 851 TBOX_ChargeDepthSet "充电深度设置";
CM_ SG_ 851 TBOX_RemoteChargeper "远程充电百分比设置
(无控制请求时，发送0x0。当激活控制命令时，发送0x1-0x64。连续发送3次，之后将控制信号重新置0x0)";
CM_ SG_ 851 TBOX_APS_EPSStrgWhlAngZero "一键回正方向盘信号";
CM_ SG_ 851 TBOX_APS_RequstRemoteParkOut "TBOX遥控泊出方向指令";
CM_ SG_ 851 TBOX_APS_QuitRemotePark " 遥控退出泊入指令";
CM_ SG_ 851 TBOX_APS_StartRemoteParkIn "按下APP遥控泊入按键状态";
CM_ SG_ 851 TBOX_APS_PoewerOff_Request "TBOX请求APS下电";
CM_ SG_ 851 TBOX_APS_StraightOut_Request1 "TBOX请求APS执行左转、右转";
CM_ SG_ 851 TBOX_APS_StraightOut_Request2 "TBOX请求APS执行前进、后退";
CM_ SG_ 851 TBOX_APS_PowerON_Request "上电请求，发给APA
(无控制请求时，发送0x0。当激活控制命令时，发送0x1/0x2/0x3。连续发送5次，之后将控制信号重新置0x0)";
CM_ SG_ 851 TBOX_VBU_RemoteChrgLock "远程解锁电子锁";
CM_ SG_ 851 TBOX_FOTA_mode "FOTA模式";
CM_ SG_ 851 TBOX_BT_KeyDIstance "蓝牙钥匙距离";
CM_ SG_ 851 TBOX_Ipc_ChargeLight_enable "TBOX蓝牙点亮充电口指示灯";
CM_ SG_ 851 TBOX_Ipc_ChrgLock_enable "TBOX蓝牙解锁充电枪电子锁";
CM_ SG_ 851 TBOX_FOTA_wakeup "TBOX唤醒HU/ICM/RSE/DVR启动OTA升级";
CM_ SG_ 851 RollingCounter_0x353 "RollingCounter: used 4bit length signal and the arithmetic is increased from 0 to 15 by every message.";
CM_ SG_ 853 TBOX_TimeSyncSts "TBOX发送的时间同步有效位";
CM_ SG_ 853 TBOX_TimeSyncData_Year "TBOX发送的同步时间数据----年
0x0-0x63: Year
0x64-0x7F: Invalid
";
CM_ SG_ 853 TBOX_TimeSyncData_Month "TBOX发送的同步时间数据----月
0x0: Invalid
0x1-0xC: Month";
CM_ SG_ 853 TBOX_TimeSyncData_Day "TBOX发送的同步时间数据----日
0x0: Invalid
0x01-0x1F: Day";
CM_ SG_ 853 TBOX_TimeSyncData_Hour "ACM发送的同步时间数据----时
0x0-0x17: Hour
0x18-0x1F: Invalid";
CM_ SG_ 853 TBOX_TimeSyncData_Minute "TBOX发送的同步时间数据----分
0x0-0x3B: Minute
0x3C-0x3F: Invalid
";
CM_ SG_ 853 TBOX_TimeSyncData_Second "TBOX发送的同步时间数据----秒
0x00-0x3B: Second
0x3C-0x3F: Invalid
";
CM_ SG_ 1026 TBOX_NM_DA "目标地址";
CM_ SG_ 1026 TBOX_NM_ALIVE "TBOX_NM_ALIVE 0-未激活；1-已激活；";
CM_ SG_ 1026 TBOX_NM_RING "TBOX_NM_RING 0-未激活；1-已激活；";
CM_ SG_ 1026 TBOX_NM_LIMPHOME "TBOX_NM_LIMPHOME 0-未激活；1-已激活；";
CM_ SG_ 1026 TBOX_NM_SLEEP_INDICATION "TBOX_NM_SLEEP_INDICATION 0-未激活；1-已激活；";
CM_ SG_ 1026 TBOX_NM_SLEEP_ACK "TBOX_NM_SLEEP_ACK 0-未激活；1-已激活；";
CM_ SG_ 1028 GW_Tbox_NM_DA "目标地址";
CM_ SG_ 1028 GW_Tbox_NM_ALIVE "Alive报文";
CM_ SG_ 1028 GW_Tbox_NM_RING "Ring报文";
CM_ SG_ 1028 GW_Tbox_NM_LIMPHOME "Limphome报文";
CM_ SG_ 1028 GW_Tbox_NM_SLEEP_Ind "睡眠标志位";
CM_ SG_ 1028 GW_Tbox_NM_SLEEP_ACK "睡眠确认位";
CM_ SG_ 1299 VBU_BMS_MaxTempNo "电池最高温度编号";
CM_ SG_ 1299 VBU_BMS_MaxTemp "电池最高温度";
CM_ SG_ 1299 VBU_BMS_MinTempNo "电池最低温度编号";
CM_ SG_ 1299 VBU_BMS_MinTemp "电池最低温度";
CM_ SG_ 1299 VBU_BMS_BattTempDev "电池温度差";
CM_ SG_ 1299 VBU_BMS_CCTemp1 "快充接口1温度";
CM_ SG_ 1299 VBU_BMS_CCTemp2 "快充接口2温度";
CM_ SG_ 1299 VBU_BMS_0x513_RollingCounter "从0到15循环计数，如果通信中断，则重新从0开始计数。";
CM_ SG_ 1300 VBU_BMS_ModuleBusbarMaxTempNo "模组busbar最高温度编号";
CM_ SG_ 1300 VBU_BMS_ModuleBusbarMaxTemp "模组busbar最高温度";
CM_ SG_ 1300 VBU_BMS_ModuleBusbarMinTempNo "模组busbar最低温度编号";
CM_ SG_ 1300 VBU_BMS_ModuleBusbarMinTemp "模组busbar最低温度";
CM_ SG_ 1300 VBU_BMS_0x514_RollingCounter "从0到15循环计数，如果通信中断，则重新从0开始计数。";
CM_ SG_ 1328 VBU_BMS_BattCellNum1Vol "1号单体电压值";
CM_ SG_ 1328 VBU_BMS_BattCellNum2Vol "2号单体电压值";
CM_ SG_ 1328 VBU_BMS_BattCellNum3Vol "3号单体电压值";
CM_ SG_ 1328 VBU_BMS_BattCellNum4Vol "4号单体电压值";
CM_ SG_ 1329 VBU_BMS_BattCellNum5Vol "5号单体电压值";
CM_ SG_ 1329 VBU_BMS_BattCellNum6Vol "6号单体电压值";
CM_ SG_ 1329 VBU_BMS_BattCellNum7Vol "7号单体电压值";
CM_ SG_ 1329 VBU_BMS_BattCellNum8Vol "8号单体电压值";
CM_ SG_ 1330 VBU_BMS_BattCellNum9Vol "9号单体电压值";
CM_ SG_ 1330 VBU_BMS_BattCellNum10Vol "10号单体电压值";
CM_ SG_ 1330 VBU_BMS_BattCellNum11Vol "11号单体电压值";
CM_ SG_ 1330 VBU_BMS_BattCellNum12Vol "12号单体电压值";
CM_ SG_ 1331 VBU_BMS_BattCellNum13Vol "13号单体电压值";
CM_ SG_ 1331 VBU_BMS_BattCellNum14Vol "14号单体电压值";
CM_ SG_ 1331 VBU_BMS_BattCellNum15Vol "15号单体电压值";
CM_ SG_ 1331 VBU_BMS_BattCellNum16Vol "16号单体电压值";
CM_ SG_ 1332 VBU_BMS_BattCellNum17Vol "17号单体电压值";
CM_ SG_ 1332 VBU_BMS_BattCellNum18Vol "18号单体电压值";
CM_ SG_ 1332 VBU_BMS_BattCellNum19Vol "19号单体电压值";
CM_ SG_ 1332 VBU_BMS_BattCellNum20Vol "20号单体电压值";
CM_ SG_ 1333 VBU_BMS_BattCellNum21Vol "21号单体电压值";
CM_ SG_ 1333 VBU_BMS_BattCellNum22Vol "22号单体电压值";
CM_ SG_ 1333 VBU_BMS_BattCellNum23Vol "23号单体电压值";
CM_ SG_ 1333 VBU_BMS_BattCellNum24Vol "24号单体电压值";
CM_ SG_ 1334 VBU_BMS_BattCellNum25Vol "25号单体电压值";
CM_ SG_ 1334 VBU_BMS_BattCellNum26Vol "26号单体电压值";
CM_ SG_ 1334 VBU_BMS_BattCellNum27Vol "27号单体电压值";
CM_ SG_ 1334 VBU_BMS_BattCellNum28Vol "28号单体电压值";
CM_ SG_ 1335 VBU_BMS_BattCellNum29Vol "29号单体电压值";
CM_ SG_ 1335 VBU_BMS_BattCellNum30Vol "30号单体电压值";
CM_ SG_ 1335 VBU_BMS_BattCellNum31Vol "31号单体电压值";
CM_ SG_ 1335 VBU_BMS_BattCellNum32Vol "32号单体电压值";
CM_ SG_ 1336 VBU_BMS_BattCellNum33Vol "33号单体电压值";
CM_ SG_ 1336 VBU_BMS_BattCellNum34Vol "34号单体电压值";
CM_ SG_ 1336 VBU_BMS_BattCellNum35Vol "35号单体电压值";
CM_ SG_ 1336 VBU_BMS_BattCellNum36Vol "36号单体电压值";
CM_ SG_ 1337 VBU_BMS_BattCellNum37Vol "37号单体电压值";
CM_ SG_ 1337 VBU_BMS_BattCellNum38Vol "38号单体电压值";
CM_ SG_ 1337 VBU_BMS_BattCellNum39Vol "39号单体电压值";
CM_ SG_ 1337 VBU_BMS_BattCellNum40Vol "40号单体电压值";
CM_ SG_ 1338 VBU_BMS_BattCellNum41Vol "41号单体电压值";
CM_ SG_ 1338 VBU_BMS_BattCellNum42Vol "42号单体电压值";
CM_ SG_ 1338 VBU_BMS_BattCellNum43Vol "43号单体电压值";
CM_ SG_ 1338 VBU_BMS_BattCellNum44Vol "44号单体电压值";
CM_ SG_ 1339 VBU_BMS_BattCellNum45Vol "45号单体电压值";
CM_ SG_ 1339 VBU_BMS_BattCellNum46Vol "46号单体电压值";
CM_ SG_ 1339 VBU_BMS_BattCellNum47Vol "47号单体电压值";
CM_ SG_ 1339 VBU_BMS_BattCellNum48Vol "48号单体电压值";
CM_ SG_ 1340 VBU_BMS_BattCellNum49Vol "49号单体电压值";
CM_ SG_ 1340 VBU_BMS_BattCellNum50Vol "50号单体电压值";
CM_ SG_ 1340 VBU_BMS_BattCellNum51Vol "51号单体电压值";
CM_ SG_ 1340 VBU_BMS_BattCellNum52Vol "52号单体电压值";
CM_ SG_ 1341 VBU_BMS_BattCellNum53Vol "53号单体电压值";
CM_ SG_ 1341 VBU_BMS_BattCellNum54Vol "54号单体电压值";
CM_ SG_ 1341 VBU_BMS_BattCellNum55Vol "55号单体电压值";
CM_ SG_ 1341 VBU_BMS_BattCellNum56Vol "56号单体电压值";
CM_ SG_ 1342 VBU_BMS_BattCellNum57Vol "57号单体电压值";
CM_ SG_ 1342 VBU_BMS_BattCellNum58Vol "58号单体电压值";
CM_ SG_ 1342 VBU_BMS_BattCellNum59Vol "59号单体电压值";
CM_ SG_ 1342 VBU_BMS_BattCellNum60Vol "60号单体电压值";
CM_ SG_ 1343 VBU_BMS_BattCellNum61Vol "61号单体电压值";
CM_ SG_ 1343 VBU_BMS_BattCellNum62Vol "62号单体电压值";
CM_ SG_ 1343 VBU_BMS_BattCellNum63Vol "63号单体电压值";
CM_ SG_ 1343 VBU_BMS_BattCellNum64Vol "64号单体电压值";
CM_ SG_ 1344 VBU_BMS_BattCellNum65Vol "65号单体电压值";
CM_ SG_ 1344 VBU_BMS_BattCellNum66Vol "66号单体电压值";
CM_ SG_ 1344 VBU_BMS_BattCellNum67Vol "67号单体电压值";
CM_ SG_ 1344 VBU_BMS_BattCellNum68Vol "68号单体电压值";
CM_ SG_ 1345 VBU_BMS_BattCellNum69Vol "69号单体电压值";
CM_ SG_ 1345 VBU_BMS_BattCellNum70Vol "70号单体电压值";
CM_ SG_ 1345 VBU_BMS_BattCellNum71Vol "71号单体电压值";
CM_ SG_ 1345 VBU_BMS_BattCellNum72Vol "72号单体电压值";
CM_ SG_ 1346 VBU_BMS_BattCellNum73Vol "73号单体电压值";
CM_ SG_ 1346 VBU_BMS_BattCellNum74Vol "74号单体电压值";
CM_ SG_ 1346 VBU_BMS_BattCellNum75Vol "75号单体电压值";
CM_ SG_ 1346 VBU_BMS_BattCellNum76Vol "76号单体电压值";
CM_ SG_ 1347 VBU_BMS_BattCellNum77Vol "77号单体电压值";
CM_ SG_ 1347 VBU_BMS_BattCellNum78Vol "78号单体电压值";
CM_ SG_ 1347 VBU_BMS_BattCellNum79Vol "79号单体电压值";
CM_ SG_ 1347 VBU_BMS_BattCellNum80Vol "80号单体电压值";
CM_ SG_ 1348 VBU_BMS_BattCellNum81Vol "81号单体电压值";
CM_ SG_ 1348 VBU_BMS_BattCellNum82Vol "82号单体电压值";
CM_ SG_ 1348 VBU_BMS_BattCellNum83Vol "83号单体电压值";
CM_ SG_ 1348 VBU_BMS_BattCellNum84Vol "84号单体电压值";
CM_ SG_ 1349 VBU_BMS_BattCellNum85Vol "85号单体电压值";
CM_ SG_ 1349 VBU_BMS_BattCellNum86Vol "86号单体电压值";
CM_ SG_ 1349 VBU_BMS_BattCellNum87Vol "87号单体电压值";
CM_ SG_ 1349 VBU_BMS_BattCellNum88Vol "88号单体电压值";
CM_ SG_ 1350 VBU_BMS_BattCellNum89Vol "89号单体电压值";
CM_ SG_ 1350 VBU_BMS_BattCellNum90Vol "90号单体电压值";
CM_ SG_ 1350 VBU_BMS_BattCellNum91Vol "91号单体电压值";
CM_ SG_ 1350 VBU_BMS_BattCellNum92Vol "92号单体电压值";
CM_ SG_ 1351 VBU_BMS_BattCellNum93Vol "93号单体电压值";
CM_ SG_ 1351 VBU_BMS_BattCellNum94Vol "94号单体电压值";
CM_ SG_ 1351 VBU_BMS_BattCellNum95Vol "95号单体电压值";
CM_ SG_ 1351 VBU_BMS_BattCellNum96Vol "96号单体电压值";
CM_ SG_ 1352 VBU_BMS_BattCellNum97Vol "97号单体电压值";
CM_ SG_ 1352 VBU_BMS_BattCellNum98Vol "98号单体电压值";
CM_ SG_ 1352 VBU_BMS_BattCellNum99Vol "99号单体电压值";
CM_ SG_ 1352 VBU_BMS_BattCellNum100Vol "100号单体电压值";
CM_ SG_ 1353 VBU_BMS_BattCellNum101Vol "101号单体电压值";
CM_ SG_ 1353 VBU_BMS_BattCellNum102Vol "102号单体电压值";
CM_ SG_ 1353 VBU_BMS_BattCellNum103Vol "103号单体电压值";
CM_ SG_ 1353 VBU_BMS_BattCellNum104Vol "104号单体电压值";
CM_ SG_ 1354 VBU_BMS_BattCellNum105Vol "105号单体电压值";
CM_ SG_ 1354 VBU_BMS_BattCellNum106Vol "106号单体电压值";
CM_ SG_ 1354 VBU_BMS_BattCellNum107Vol "107号单体电压值";
CM_ SG_ 1354 VBU_BMS_BattCellNum108Vol "108号单体电压值";
CM_ SG_ 1492 TBOX_SWVersion_Supplier "TBOX软件供应商代码（有电咖定义，如A/B/C分别代表A点/B点/C点供应商，定义参考诊断规范版本号定义）";
CM_ SG_ 1492 TBOX_SWVersion_Main "TBOX软件版本-大版本";
CM_ SG_ 1492 TBOX_SWVersion_Sub1 "TBOX软件版本-小版本第一位";
CM_ SG_ 1492 TBOX_SWVersion_Sub2 "TBOX软件版本-小版本第二位";
CM_ SG_ 1492 TBOX_HWVersion_Supplier "TBOX硬件件供应商代码";
CM_ SG_ 1492 TBOX_HWVersion_Main "TBOX硬件版本-大版本";
CM_ SG_ 1492 TBOX_HWVersion_Sub1 "TBOX硬件版本-小版本第一位";
CM_ SG_ 1492 TBOX_HWVersion_Sub2 "TBOX硬件版本-小版本第二位";
CM_ SG_ 1520 VBU_BMS_BattTempSensorNum1 "1号温度探针温度值";
CM_ SG_ 1520 VBU_BMS_BattTempSensorNum2 "2号温度探针温度值";
CM_ SG_ 1520 VBU_BMS_BattTempSensorNum3 "3号温度探针温度值";
CM_ SG_ 1520 VBU_BMS_BattTempSensorNum4 "4号温度探针温度值";
CM_ SG_ 1520 VBU_BMS_BattTempSensorNum5 "5号温度探针温度值";
CM_ SG_ 1520 VBU_BMS_BattTempSensorNum6 "6号温度探针温度值";
CM_ SG_ 1520 VBU_BMS_BattTempSensorNum7 "7号温度探针温度值";
CM_ SG_ 1520 VBU_BMS_BattTempSensorNum8 "8号温度探针温度值";
CM_ SG_ 1521 VBU_BMS_BattTempSensorNum9 "9号温度探针温度值";
CM_ SG_ 1521 VBU_BMS_BattTempSensorNum10 "10号温度探针温度值";
CM_ SG_ 1521 VBU_BMS_BattTempSensorNum11 "11号温度探针温度值";
CM_ SG_ 1521 VBU_BMS_BattTempSensorNum12 "12号温度探针温度值";
CM_ SG_ 1521 VBU_BMS_BattTempSensorNum13 "13号温度探针温度值";
CM_ SG_ 1521 VBU_BMS_BattTempSensorNum14 "14号温度探针温度值";
CM_ SG_ 1521 VBU_BMS_BattTempSensorNum15 "15号温度探针温度值";
CM_ SG_ 1521 VBU_BMS_BattTempSensorNum16 "16号温度探针温度值";
CM_ SG_ 1522 VBU_BMS_BattTempSensorNum17 "17号温度探针温度值";
CM_ SG_ 1522 VBU_BMS_BattTempSensorNum18 "18号温度探针温度值";
CM_ SG_ 1522 VBU_BMS_BattTempSensorNum19 "19号温度探针温度值";
CM_ SG_ 1522 VBU_BMS_BattTempSensorNum20 "20号温度探针温度值";
CM_ SG_ 1522 VBU_BMS_BattTempSensorNum21 "21号温度探针温度值";
CM_ SG_ 1522 VBU_BMS_BattTempSensorNum22 "22号温度探针温度值";
CM_ SG_ 1522 VBU_BMS_BattTempSensorNum23 "23号温度探针温度值";
CM_ SG_ 1522 VBU_BMS_BattTempSensorNum24 "24号温度探针温度值";
CM_ SG_ 1523 VBU_BMS_BattTempSensorNum25 "25号温度探针温度值";
CM_ SG_ 1523 VBU_BMS_BattTempSensorNum26 "26号温度探针温度值";
CM_ SG_ 1523 VBU_BMS_BattTempSensorNum27 "27号温度探针温度值";
CM_ SG_ 1523 VBU_BMS_BattTempSensorNum28 "28号温度探针温度值";
CM_ SG_ 1523 VBU_BMS_BattTempSensorNum29 "29号温度探针温度值";
CM_ SG_ 1523 VBU_BMS_BattTempSensorNum30 "30号温度探针温度值";
CM_ SG_ 1523 VBU_BMS_BattTempSensorNum31 "31号温度探针温度值";
CM_ SG_ 1523 VBU_BMS_BattTempSensorNum32 "32号温度探针温度值";
CM_ SG_ 1524 VBU_BMS_BattTempSensorNum33 "33号温度探针温度值";
CM_ SG_ 1524 VBU_BMS_BattTempSensorNum34 "34号温度探针温度值";
CM_ SG_ 1524 VBU_BMS_BattTempSensorNum35 "35号温度探针温度值";
CM_ SG_ 1524 VBU_BMS_BattTempSensorNum36 "36号温度探针温度值";
CM_ SG_ 1524 VBU_BMS_BattTempSensorNum37 "37号温度探针温度值";
CM_ SG_ 1524 VBU_BMS_BattTempSensorNum38 "38号温度探针温度值";
CM_ SG_ 1524 VBU_BMS_BattTempSensorNum39 "39号温度探针温度值";
CM_ SG_ 1524 VBU_BMS_BattTempSensorNum40 "40号温度探针温度值";
CM_ SG_ 1525 VBU_BMS_BattTempSensorNum41 "41号温度探针温度值";
CM_ SG_ 1525 VBU_BMS_BattTempSensorNum42 "42号温度探针温度值";
CM_ SG_ 1525 VBU_BMS_BattTempSensorNum43 "43号温度探针温度值";
CM_ SG_ 1525 VBU_BMS_BattTempSensorNum44 "44号温度探针温度值";
CM_ SG_ 1525 VBU_BMS_BattTempSensorNum45 "45号温度探针温度值";
CM_ SG_ 1525 VBU_BMS_BattTempSensorNum46 "46号温度探针温度值";
CM_ SG_ 1525 VBU_BMS_BattTempSensorNum47 "47号温度探针温度值";
CM_ SG_ 1525 VBU_BMS_BattTempSensorNum48 "48号温度探针温度值";
CM_ SG_ 1526 VBU_BMS_BattTempSensorNum49 "49号温度探针温度值";
CM_ SG_ 1526 VBU_BMS_BattTempSensorNum50 "50号温度探针温度值";
CM_ SG_ 1526 VBU_BMS_BattTempSensorNum51 "51号温度探针温度值";
CM_ SG_ 1526 VBU_BMS_BattTempSensorNum52 "52号温度探针温度值";
CM_ SG_ 1526 VBU_BMS_BattTempSensorNum53 "53号温度探针温度值";
CM_ SG_ 1526 VBU_BMS_BattTempSensorNum54 "54号温度探针温度值";
CM_ SG_ 1526 VBU_BMS_BattTempSensorNum55 "55号温度探针温度值";
CM_ SG_ 1526 VBU_BMS_BattTempSensorNum56 "56号温度探针温度值";
CM_ SG_ 1527 VBU_BMS_BattTempSensorNum57 "57号温度探针温度值";
CM_ SG_ 1527 VBU_BMS_BattTempSensorNum58 "58号温度探针温度值";
CM_ SG_ 1527 VBU_BMS_BattTempSensorNum59 "59号温度探针温度值";
CM_ SG_ 1527 VBU_BMS_BattTempSensorNum60 "60号温度探针温度值";
CM_ SG_ 1527 VBU_BMS_BattTempSensorNum61 "61号温度探针温度值";
CM_ SG_ 1527 VBU_BMS_BattTempSensorNum62 "62号温度探针温度值";
CM_ SG_ 1527 VBU_BMS_BattTempSensorNum63 "63号温度探针温度值";
CM_ SG_ 1527 VBU_BMS_BattTempSensorNum64 "64号温度探针温度值";
CM_ SG_ 1528 VBU_BMS_BattTempSensorNum65 "65号温度探针温度值";
CM_ SG_ 1528 VBU_BMS_BattTempSensorNum66 "66号温度探针温度值";
CM_ SG_ 1528 VBU_BMS_BattTempSensorNum67 "67号温度探针温度值";
CM_ SG_ 1528 VBU_BMS_BattTempSensorNum68 "68号温度探针温度值";
CM_ SG_ 1528 VBU_BMS_BattTempSensorNum69 "69号温度探针温度值";
CM_ SG_ 1528 VBU_BMS_BattTempSensorNum70 "70号温度探针温度值";
CM_ SG_ 1528 VBU_BMS_BattTempSensorNum71 "71号温度探针温度值";
CM_ SG_ 1528 VBU_BMS_BattTempSensorNum72 "72号温度探针温度值";
CM_ SG_ 1473 GW_SWVersion_Supplier "GW软件供应商代码（有电咖定义，如A/B/C分别代表A点/B点/C点供应商，定义参考诊断规范版本号定义）";
CM_ SG_ 1473 GW_SWVersion_Main "GW软件版本-大版本";
CM_ SG_ 1473 GW_SWVersion_Sub1 "GW软件版本-小版本第一位";
CM_ SG_ 1473 GW_SWVersion_Sub2 "GW软件版本-小版本第二位";
CM_ SG_ 1473 GW_HWVersion_Supplier "GW硬件件供应商代码";
CM_ SG_ 1473 GW_HWVersion_Main "GW硬件版本-大版本";
CM_ SG_ 1473 GW_HWVersion_Sub1 "GW硬件版本-小版本第一位";
CM_ SG_ 1473 GW_HWVersion_Sub2 "GW硬件版本-小版本第二位";

BA_DEF_ BO_  "NmMessage" ENUM "No","Yes";
BA_DEF_ BO_  "GenMsgSendType" ENUM  "cyclic","IfActive","Event","CA","CE","NoMsgSendType";
BA_DEF_ BO_  "GenMsgCycleTime" INT 0 0;
BA_DEF_ SG_  "GenSigSendType" ENUM  "cyclic","OnChange","OnWrite","IfActive","OnChangeWithRepetition","OnWriteWithRepetition","IfActiveWithRepetition","NoSigSendType","OnChangeAndIfActive", "OnChangeAndIfActiveWithRepetition","CA","CE","Event";
BA_DEF_ SG_  "GenSigStartValue" INT 0 0;
BA_DEF_ BO_  "GenMsgNrOfRepetition" INT 0 0;

BA_DEF_DEF_  "NmMessage" "No";
BA_DEF_DEF_  "GenMsgSendType" "cyclic";
BA_DEF_DEF_  "GenMsgCycleTime" 0;
BA_DEF_DEF_  "GenSigSendType" "cyclic";
BA_DEF_DEF_  "GenSigStartValue" 0;
BA_DEF_DEF_  "GenMsgNrOfRepetition" 0;
BA_ "GenMsgCycleTime" BO_ 945 100;
BA_ "GenMsgCycleTime" BO_ 946 100;
BA_ "GenSigStartValue" SG_ 946 TBOX_GyroTemperature 2047;
BA_ "GenMsgCycleTime" BO_ 1378 100;
BA_ "GenSigStartValue" SG_ 1378 MCU_MotorSts_GBT 3;
BA_ "GenMsgCycleTime" BO_ 805 100;
BA_ "GenMsgCycleTime" BO_ 1323 100;
BA_ "GenMsgCycleTime" BO_ 1325 100;
BA_ "GenMsgCycleTime" BO_ 1326 100;
BA_ "GenMsgCycleTime" BO_ 1327 100;
BA_ "GenMsgCycleTime" BO_ 1379 100;
BA_ "GenMsgCycleTime" BO_ 401 10;
BA_ "GenMsgCycleTime" BO_ 624 20;
BA_ "GenMsgCycleTime" BO_ 625 50;
BA_ "GenMsgCycleTime" BO_ 920 100;
BA_ "GenMsgCycleTime" BO_ 800 100;
BA_ "GenMsgCycleTime" BO_ 806 100;
BA_ "GenMsgCycleTime" BO_ 928 100;
BA_ "GenSigStartValue" SG_ 928 ICM_instantaneous_power 400;
BA_ "GenSigSendType" SG_ 928 ICM_ODOTotalFB 1;
BA_ "GenSigSendType" SG_ 928 ICM_PrevmaintmileagesFB 1;
BA_ "GenSigSendType" SG_ 928 ICM_SubMileage_Reset 1;
BA_ "GenMsgCycleTime" BO_ 896 100;
BA_ "GenSigStartValue" SG_ 896 RLS_Brightness_FW 1023;
BA_ "GenSigStartValue" SG_ 896 RLS_Rain_Intensity 14;
BA_ "GenMsgCycleTime" BO_ 784 50;
BA_ "GenMsgCycleTime" BO_ 665 100;
BA_ "GenSigStartValue" SG_ 665 FLWM_WinPstSt 127;
BA_ "GenSigStartValue" SG_ 665 FRWM_WinPstSt 127;
BA_ "GenSigStartValue" SG_ 665 RLWM_WinPstSt 127;
BA_ "GenSigStartValue" SG_ 665 RRWM_WinPstSt 127;
BA_ "GenMsgCycleTime" BO_ 583 100;
BA_ "GenSigSendType" SG_ 583 BCM_StartWarning 1;
BA_ "GenSigSendType" SG_ 583 BCM_PowerOffWarning 1;
BA_ "GenSigSendType" SG_ 583 BCM_PowerONWarning 1;
BA_ "GenMsgCycleTime" BO_ 1282 100;
BA_ "GenMsgCycleTime" BO_ 804 100;
BA_ "GenMsgCycleTime" BO_ 835 100;
BA_ "GenMsgCycleTime" BO_ 774 1000;
BA_ "GenSigStartValue" SG_ 774 VBU_BMS_RemainChargingTime 4094;
BA_ "GenMsgCycleTime" BO_ 528 10;
BA_ "GenMsgCycleTime" BO_ 596 100;
BA_ "GenMsgCycleTime" BO_ 1009 200;
BA_ "GenSigSendType" SG_ 1009 DVR_ControlResult 1;
BA_ "GenSigSendType" SG_ 1009 DVR_GsensorCrashStatus 1;
BA_ "GenSigSendType" SG_ 1009 DVR_requestWiFiopen 1;
BA_ "GenSigSendType" SG_ 1009 DVR_LocalTimelapseRecordResult 1;
BA_ "GenSigSendType" SG_ 1009 DVR_Frameinterval 1;
BA_ "GenSigSendType" SG_ 1009 DVR_FrameCount 1;
BA_ "GenSigSendType" SG_ 1009 DVR_PlayRate 1;
BA_ "GenMsgCycleTime" BO_ 676 100;
BA_ "GenSigSendType" SG_ 676 DSM_GetMemoryRsp_Mirror 1;
BA_ "GenSigSendType" SG_ 676 DSM_GetMemoryRsp_Seat 1;
BA_ "GenSigStartValue" SG_ 676 DSM_PSMheattemp 34;
BA_ "GenSigStartValue" SG_ 676 DSM_DSMheattemp 34;
BA_ "GenMsgSendType" BO_ 24 2;
BA_ "GenSigSendType" SG_ 24 BCM_AuthReq_TBOX_NSM_Code 1;
BA_ "GenMsgSendType" BO_ 25 2;
BA_ "GenSigSendType" SG_ 25 TBOX_AuthResp_BCM_Code 1;
BA_ "GenMsgCycleTime" BO_ 288 20;
BA_ "GenSigStartValue" SG_ 288 MCU_MotorActualTorque 32766;
BA_ "GenSigStartValue" SG_ 288 MCU_MotorSpeed 65534;
BA_ "GenMsgCycleTime" BO_ 290 100;
BA_ "GenSigStartValue" SG_ 290 MCU_MaxAvailableTorque 2046;
BA_ "GenSigStartValue" SG_ 290 MCU_MinAvailableTorque 2046;
BA_ "GenMsgCycleTime" BO_ 289 20;
BA_ "GenMsgCycleTime" BO_ 291 100;
BA_ "GenSigStartValue" SG_ 291 MCU_DC_linkVoltage 1022;
BA_ "GenSigStartValue" SG_ 291 MCU_DC_linkCurrent 2046;
BA_ "GenSigStartValue" SG_ 291 MCU_InverterTemp 254;
BA_ "GenSigStartValue" SG_ 291 MCU_MotorTemp 254;
BA_ "GenMsgCycleTime" BO_ 292 100;
BA_ "GenSigStartValue" SG_ 292 MCU_RotorTemp 254;
BA_ "GenSigStartValue" SG_ 292 MCU_Motoroffset 1022;
BA_ "GenMsgCycleTime" BO_ 545 100;
BA_ "GenSigSendType" SG_ 545 TBOX_WelcomefuncReq 1;
BA_ "GenSigSendType" SG_ 545 TBOX_DischargeDepthSet 1;
BA_ "GenSigStartValue" SG_ 545 TBOX_DischargeDepthSet 127;
BA_ "GenMsgCycleTime" BO_ 599 100;
BA_ "GenSigStartValue" SG_ 599 AC_OutTemperature_raw 216;
BA_ "GenMsgCycleTime" BO_ 849 100;
BA_ "GenSigSendType" SG_ 849 TBOX_BCM_DoorLock_Control_4G 1;
BA_ "GenSigSendType" SG_ 849 TBOX_BCM_CarLocating 1;
BA_ "GenSigSendType" SG_ 849 TBOX_PLG_TrunkunLock 1;
BA_ "GenSigSendType" SG_ 849 TBOX_DSM_heatSwitch 1;
BA_ "GenSigSendType" SG_ 849 TBOX_PSM_heatSwitch 1;
BA_ "GenSigSendType" SG_ 849 TBOX_BCM_DoorLock_Control_BT 1;
BA_ "GenSigSendType" SG_ 849 TBOX_DSM_Targtemp 1;
BA_ "GenSigStartValue" SG_ 849 TBOX_DSM_Targtemp 63;
BA_ "GenSigSendType" SG_ 849 TBOX_Publish_Wakeup 1;
BA_ "GenSigSendType" SG_ 849 TBOX_PSM_Targtemp 1;
BA_ "GenSigStartValue" SG_ 849 TBOX_PSM_Targtemp 63;
BA_ "GenSigSendType" SG_ 849 TBOX_RB_Initialization 1;
BA_ "GenSigSendType" SG_ 849 TBOX_BCM_PowerON_Request 1;
BA_ "GenSigSendType" SG_ 849 TBOX_RB_Position_Req 1;
BA_ "GenSigStartValue" SG_ 849 TBOX_RB_Position_Req 254;
BA_ "GenSigSendType" SG_ 849 TBOX_BCM_FLWindowsControl 1;
BA_ "GenSigSendType" SG_ 849 TBOX_BCM_FRWindowsControl 1;
BA_ "GenSigSendType" SG_ 849 TBOX_BCM_RLWindowsControl 1;
BA_ "GenSigSendType" SG_ 849 TBOX_BCM_RRWindowsControl 1;
BA_ "GenMsgCycleTime" BO_ 850 100;
BA_ "GenSigSendType" SG_ 850 TBOX_AC_SystemSet 1;
BA_ "GenSigSendType" SG_ 850 TBOX_AC_Cycle 1;
BA_ "GenSigSendType" SG_ 850 TBOX_AC_EAC_Control 1;
BA_ "GenSigSendType" SG_ 850 TBOX_AC_AutoMode_Set 1;
BA_ "GenSigSendType" SG_ 850 TBOX_AC_WindMode_Set 1;
BA_ "GenSigSendType" SG_ 850 TBOX_AC_FDefrostMode_Set 1;
BA_ "GenSigSendType" SG_ 850 TBOX_AC_BlowingRate_Set 1;
BA_ "GenSigSendType" SG_ 850 TBOX_AC_APTCSW_Set 1;
BA_ "GenSigSendType" SG_ 850 TBOX_AC_Temp_set 1;
BA_ "GenSigSendType" SG_ 850 TBOX_RemotePhotograph 1;
BA_ "GenSigSendType" SG_ 850 TBOX_PLG_OpenControl 1;
BA_ "GenSigSendType" SG_ 850 TBOX_BCM_FLWindowsVoiControl 1;
BA_ "GenSigSendType" SG_ 850 TBOX_BCM_FRWindowsVoiControl 1;
BA_ "GenSigSendType" SG_ 850 TBOX_BCM_RLWindowsVoiControl 1;
BA_ "GenSigSendType" SG_ 850 TBOX_BCM_RRWindowsVoiControl 1;
BA_ "GenMsgCycleTime" BO_ 851 100;
BA_ "GenSigSendType" SG_ 851 TBOX_VBU_12vChargeReq 1;
BA_ "GenSigSendType" SG_ 851 TBOX_ChargeDepthSet 1;
BA_ "GenSigSendType" SG_ 851 TBOX_APS_EPSStrgWhlAngZero 1;
BA_ "GenSigSendType" SG_ 851 TBOX_APS_PoewerOff_Request 1;
BA_ "GenSigSendType" SG_ 851 TBOX_APS_PowerON_Request 1;
BA_ "GenSigSendType" SG_ 851 TBOX_BT_KeyDIstance 1;
BA_ "GenSigSendType" SG_ 851 TBOX_Ipc_ChargeLight_enable 1;
BA_ "GenSigSendType" SG_ 851 TBOX_Ipc_ChrgLock_enable 1;
BA_ "GenMsgCycleTime" BO_ 853 1000;
BA_ "GenSigStartValue" SG_ 853 TBOX_TimeSyncData_Month 1;
BA_ "GenSigStartValue" SG_ 853 TBOX_TimeSyncData_Day 1;
BA_ "NmMessage" BO_ 1026 1;
BA_ "GenMsgSendType" BO_ 1026 2;
BA_ "GenSigSendType" SG_ 1026 TBOX_NM_DA 1;
BA_ "GenSigSendType" SG_ 1026 TBOX_NM_ALIVE 1;
BA_ "GenSigSendType" SG_ 1026 TBOX_NM_RING 1;
BA_ "GenSigSendType" SG_ 1026 TBOX_NM_LIMPHOME 1;
BA_ "GenSigSendType" SG_ 1026 TBOX_NM_SLEEP_INDICATION 1;
BA_ "GenSigSendType" SG_ 1026 TBOX_NM_SLEEP_ACK 1;
BA_ "NmMessage" BO_ 1028 1;
BA_ "GenMsgSendType" BO_ 1028 2;
BA_ "GenSigSendType" SG_ 1028 GW_Tbox_NM_DA 1;
BA_ "GenSigSendType" SG_ 1028 GW_Tbox_NM_ALIVE 1;
BA_ "GenSigSendType" SG_ 1028 GW_Tbox_NM_RING 1;
BA_ "GenSigSendType" SG_ 1028 GW_Tbox_NM_LIMPHOME 1;
BA_ "GenSigSendType" SG_ 1028 GW_Tbox_NM_SLEEP_Ind 1;
BA_ "GenSigSendType" SG_ 1028 GW_Tbox_NM_SLEEP_ACK 1;
BA_ "GenMsgCycleTime" BO_ 1299 500;
BA_ "GenSigStartValue" SG_ 1299 VBU_BMS_MaxTemp 252;
BA_ "GenSigStartValue" SG_ 1299 VBU_BMS_MinTemp 252;
BA_ "GenSigStartValue" SG_ 1299 VBU_BMS_BattTempDev 252;
BA_ "GenSigStartValue" SG_ 1299 VBU_BMS_CCTemp1 252;
BA_ "GenSigStartValue" SG_ 1299 VBU_BMS_CCTemp2 252;
BA_ "GenMsgCycleTime" BO_ 1300 500;
BA_ "GenSigStartValue" SG_ 1300 VBU_BMS_ModuleBusbarMaxTemp 252;
BA_ "GenSigStartValue" SG_ 1300 VBU_BMS_ModuleBusbarMinTemp 252;
BA_ "GenMsgCycleTime" BO_ 1328 1000;
BA_ "GenSigStartValue" SG_ 1328 VBU_BMS_BattCellNum1Vol 5093;
BA_ "GenSigStartValue" SG_ 1328 VBU_BMS_BattCellNum2Vol 5093;
BA_ "GenSigStartValue" SG_ 1328 VBU_BMS_BattCellNum3Vol 5093;
BA_ "GenSigStartValue" SG_ 1328 VBU_BMS_BattCellNum4Vol 5093;
BA_ "GenMsgCycleTime" BO_ 1329 1000;
BA_ "GenSigStartValue" SG_ 1329 VBU_BMS_BattCellNum5Vol 5093;
BA_ "GenSigStartValue" SG_ 1329 VBU_BMS_BattCellNum6Vol 5093;
BA_ "GenSigStartValue" SG_ 1329 VBU_BMS_BattCellNum7Vol 5093;
BA_ "GenSigStartValue" SG_ 1329 VBU_BMS_BattCellNum8Vol 5093;
BA_ "GenMsgCycleTime" BO_ 1330 1000;
BA_ "GenSigStartValue" SG_ 1330 VBU_BMS_BattCellNum9Vol 5093;
BA_ "GenSigStartValue" SG_ 1330 VBU_BMS_BattCellNum10Vol 5093;
BA_ "GenSigStartValue" SG_ 1330 VBU_BMS_BattCellNum11Vol 5093;
BA_ "GenSigStartValue" SG_ 1330 VBU_BMS_BattCellNum12Vol 5093;
BA_ "GenMsgCycleTime" BO_ 1331 1000;
BA_ "GenSigStartValue" SG_ 1331 VBU_BMS_BattCellNum13Vol 5093;
BA_ "GenSigStartValue" SG_ 1331 VBU_BMS_BattCellNum14Vol 5093;
BA_ "GenSigStartValue" SG_ 1331 VBU_BMS_BattCellNum15Vol 5093;
BA_ "GenSigStartValue" SG_ 1331 VBU_BMS_BattCellNum16Vol 5093;
BA_ "GenMsgCycleTime" BO_ 1332 1000;
BA_ "GenSigStartValue" SG_ 1332 VBU_BMS_BattCellNum17Vol 5093;
BA_ "GenSigStartValue" SG_ 1332 VBU_BMS_BattCellNum18Vol 5093;
BA_ "GenSigStartValue" SG_ 1332 VBU_BMS_BattCellNum19Vol 5093;
BA_ "GenSigStartValue" SG_ 1332 VBU_BMS_BattCellNum20Vol 5093;
BA_ "GenMsgCycleTime" BO_ 1333 1000;
BA_ "GenSigStartValue" SG_ 1333 VBU_BMS_BattCellNum21Vol 5093;
BA_ "GenSigStartValue" SG_ 1333 VBU_BMS_BattCellNum22Vol 5093;
BA_ "GenSigStartValue" SG_ 1333 VBU_BMS_BattCellNum23Vol 5093;
BA_ "GenSigStartValue" SG_ 1333 VBU_BMS_BattCellNum24Vol 5093;
BA_ "GenMsgCycleTime" BO_ 1334 1000;
BA_ "GenSigStartValue" SG_ 1334 VBU_BMS_BattCellNum25Vol 5093;
BA_ "GenSigStartValue" SG_ 1334 VBU_BMS_BattCellNum26Vol 5093;
BA_ "GenSigStartValue" SG_ 1334 VBU_BMS_BattCellNum27Vol 5093;
BA_ "GenSigStartValue" SG_ 1334 VBU_BMS_BattCellNum28Vol 5093;
BA_ "GenMsgCycleTime" BO_ 1335 1000;
BA_ "GenSigStartValue" SG_ 1335 VBU_BMS_BattCellNum29Vol 5093;
BA_ "GenSigStartValue" SG_ 1335 VBU_BMS_BattCellNum30Vol 5093;
BA_ "GenSigStartValue" SG_ 1335 VBU_BMS_BattCellNum31Vol 5093;
BA_ "GenSigStartValue" SG_ 1335 VBU_BMS_BattCellNum32Vol 5093;
BA_ "GenMsgCycleTime" BO_ 1336 1000;
BA_ "GenSigStartValue" SG_ 1336 VBU_BMS_BattCellNum33Vol 5093;
BA_ "GenSigStartValue" SG_ 1336 VBU_BMS_BattCellNum34Vol 5093;
BA_ "GenSigStartValue" SG_ 1336 VBU_BMS_BattCellNum35Vol 5093;
BA_ "GenSigStartValue" SG_ 1336 VBU_BMS_BattCellNum36Vol 5093;
BA_ "GenMsgCycleTime" BO_ 1337 1000;
BA_ "GenSigStartValue" SG_ 1337 VBU_BMS_BattCellNum37Vol 5093;
BA_ "GenSigStartValue" SG_ 1337 VBU_BMS_BattCellNum38Vol 5093;
BA_ "GenSigStartValue" SG_ 1337 VBU_BMS_BattCellNum39Vol 5093;
BA_ "GenSigStartValue" SG_ 1337 VBU_BMS_BattCellNum40Vol 5093;
BA_ "GenMsgCycleTime" BO_ 1338 1000;
BA_ "GenSigStartValue" SG_ 1338 VBU_BMS_BattCellNum41Vol 5093;
BA_ "GenSigStartValue" SG_ 1338 VBU_BMS_BattCellNum42Vol 5093;
BA_ "GenSigStartValue" SG_ 1338 VBU_BMS_BattCellNum43Vol 5093;
BA_ "GenSigStartValue" SG_ 1338 VBU_BMS_BattCellNum44Vol 5093;
BA_ "GenMsgCycleTime" BO_ 1339 1000;
BA_ "GenSigStartValue" SG_ 1339 VBU_BMS_BattCellNum45Vol 5093;
BA_ "GenSigStartValue" SG_ 1339 VBU_BMS_BattCellNum46Vol 5093;
BA_ "GenSigStartValue" SG_ 1339 VBU_BMS_BattCellNum47Vol 5093;
BA_ "GenSigStartValue" SG_ 1339 VBU_BMS_BattCellNum48Vol 5093;
BA_ "GenMsgCycleTime" BO_ 1340 1000;
BA_ "GenSigStartValue" SG_ 1340 VBU_BMS_BattCellNum49Vol 5093;
BA_ "GenSigStartValue" SG_ 1340 VBU_BMS_BattCellNum50Vol 5093;
BA_ "GenSigStartValue" SG_ 1340 VBU_BMS_BattCellNum51Vol 5093;
BA_ "GenSigStartValue" SG_ 1340 VBU_BMS_BattCellNum52Vol 5093;
BA_ "GenMsgCycleTime" BO_ 1341 1000;
BA_ "GenSigStartValue" SG_ 1341 VBU_BMS_BattCellNum53Vol 5093;
BA_ "GenSigStartValue" SG_ 1341 VBU_BMS_BattCellNum54Vol 5093;
BA_ "GenSigStartValue" SG_ 1341 VBU_BMS_BattCellNum55Vol 5093;
BA_ "GenSigStartValue" SG_ 1341 VBU_BMS_BattCellNum56Vol 5093;
BA_ "GenMsgCycleTime" BO_ 1342 1000;
BA_ "GenSigStartValue" SG_ 1342 VBU_BMS_BattCellNum57Vol 5093;
BA_ "GenSigStartValue" SG_ 1342 VBU_BMS_BattCellNum58Vol 5093;
BA_ "GenSigStartValue" SG_ 1342 VBU_BMS_BattCellNum59Vol 5093;
BA_ "GenSigStartValue" SG_ 1342 VBU_BMS_BattCellNum60Vol 5093;
BA_ "GenMsgCycleTime" BO_ 1343 1000;
BA_ "GenSigStartValue" SG_ 1343 VBU_BMS_BattCellNum61Vol 5093;
BA_ "GenSigStartValue" SG_ 1343 VBU_BMS_BattCellNum62Vol 5093;
BA_ "GenSigStartValue" SG_ 1343 VBU_BMS_BattCellNum63Vol 5093;
BA_ "GenSigStartValue" SG_ 1343 VBU_BMS_BattCellNum64Vol 5093;
BA_ "GenMsgCycleTime" BO_ 1344 1000;
BA_ "GenSigStartValue" SG_ 1344 VBU_BMS_BattCellNum65Vol 5093;
BA_ "GenSigStartValue" SG_ 1344 VBU_BMS_BattCellNum66Vol 5093;
BA_ "GenSigStartValue" SG_ 1344 VBU_BMS_BattCellNum67Vol 5093;
BA_ "GenSigStartValue" SG_ 1344 VBU_BMS_BattCellNum68Vol 5093;
BA_ "GenMsgCycleTime" BO_ 1345 1000;
BA_ "GenSigStartValue" SG_ 1345 VBU_BMS_BattCellNum69Vol 5093;
BA_ "GenSigStartValue" SG_ 1345 VBU_BMS_BattCellNum70Vol 5093;
BA_ "GenSigStartValue" SG_ 1345 VBU_BMS_BattCellNum71Vol 5093;
BA_ "GenSigStartValue" SG_ 1345 VBU_BMS_BattCellNum72Vol 5093;
BA_ "GenMsgCycleTime" BO_ 1346 1000;
BA_ "GenSigStartValue" SG_ 1346 VBU_BMS_BattCellNum73Vol 5093;
BA_ "GenSigStartValue" SG_ 1346 VBU_BMS_BattCellNum74Vol 5093;
BA_ "GenSigStartValue" SG_ 1346 VBU_BMS_BattCellNum75Vol 5093;
BA_ "GenSigStartValue" SG_ 1346 VBU_BMS_BattCellNum76Vol 5093;
BA_ "GenMsgCycleTime" BO_ 1347 1000;
BA_ "GenSigStartValue" SG_ 1347 VBU_BMS_BattCellNum77Vol 5093;
BA_ "GenSigStartValue" SG_ 1347 VBU_BMS_BattCellNum78Vol 5093;
BA_ "GenSigStartValue" SG_ 1347 VBU_BMS_BattCellNum79Vol 5093;
BA_ "GenSigStartValue" SG_ 1347 VBU_BMS_BattCellNum80Vol 5093;
BA_ "GenMsgCycleTime" BO_ 1348 1000;
BA_ "GenSigStartValue" SG_ 1348 VBU_BMS_BattCellNum81Vol 5093;
BA_ "GenSigStartValue" SG_ 1348 VBU_BMS_BattCellNum82Vol 5093;
BA_ "GenSigStartValue" SG_ 1348 VBU_BMS_BattCellNum83Vol 5093;
BA_ "GenSigStartValue" SG_ 1348 VBU_BMS_BattCellNum84Vol 5093;
BA_ "GenMsgCycleTime" BO_ 1349 1000;
BA_ "GenSigStartValue" SG_ 1349 VBU_BMS_BattCellNum85Vol 5093;
BA_ "GenSigStartValue" SG_ 1349 VBU_BMS_BattCellNum86Vol 5093;
BA_ "GenSigStartValue" SG_ 1349 VBU_BMS_BattCellNum87Vol 5093;
BA_ "GenSigStartValue" SG_ 1349 VBU_BMS_BattCellNum88Vol 5093;
BA_ "GenMsgCycleTime" BO_ 1350 1000;
BA_ "GenSigStartValue" SG_ 1350 VBU_BMS_BattCellNum89Vol 5093;
BA_ "GenSigStartValue" SG_ 1350 VBU_BMS_BattCellNum90Vol 5093;
BA_ "GenSigStartValue" SG_ 1350 VBU_BMS_BattCellNum91Vol 5093;
BA_ "GenSigStartValue" SG_ 1350 VBU_BMS_BattCellNum92Vol 5093;
BA_ "GenMsgCycleTime" BO_ 1351 1000;
BA_ "GenSigStartValue" SG_ 1351 VBU_BMS_BattCellNum93Vol 5093;
BA_ "GenSigStartValue" SG_ 1351 VBU_BMS_BattCellNum94Vol 5093;
BA_ "GenSigStartValue" SG_ 1351 VBU_BMS_BattCellNum95Vol 5093;
BA_ "GenSigStartValue" SG_ 1351 VBU_BMS_BattCellNum96Vol 5093;
BA_ "GenMsgCycleTime" BO_ 1352 1000;
BA_ "GenSigStartValue" SG_ 1352 VBU_BMS_BattCellNum97Vol 5093;
BA_ "GenSigStartValue" SG_ 1352 VBU_BMS_BattCellNum98Vol 5093;
BA_ "GenSigStartValue" SG_ 1352 VBU_BMS_BattCellNum99Vol 5093;
BA_ "GenSigStartValue" SG_ 1352 VBU_BMS_BattCellNum100Vol 5093;
BA_ "GenMsgCycleTime" BO_ 1353 1000;
BA_ "GenSigStartValue" SG_ 1353 VBU_BMS_BattCellNum101Vol 5093;
BA_ "GenSigStartValue" SG_ 1353 VBU_BMS_BattCellNum102Vol 5093;
BA_ "GenSigStartValue" SG_ 1353 VBU_BMS_BattCellNum103Vol 5093;
BA_ "GenSigStartValue" SG_ 1353 VBU_BMS_BattCellNum104Vol 5093;
BA_ "GenMsgCycleTime" BO_ 1354 1000;
BA_ "GenSigStartValue" SG_ 1354 VBU_BMS_BattCellNum105Vol 5093;
BA_ "GenSigStartValue" SG_ 1354 VBU_BMS_BattCellNum106Vol 5093;
BA_ "GenSigStartValue" SG_ 1354 VBU_BMS_BattCellNum107Vol 5093;
BA_ "GenSigStartValue" SG_ 1354 VBU_BMS_BattCellNum108Vol 5093;
BA_ "GenMsgCycleTime" BO_ 1492 10000;
BA_ "GenMsgCycleTime" BO_ 1520 1000;
BA_ "GenSigStartValue" SG_ 1520 VBU_BMS_BattTempSensorNum1 252;
BA_ "GenSigStartValue" SG_ 1520 VBU_BMS_BattTempSensorNum2 252;
BA_ "GenSigStartValue" SG_ 1520 VBU_BMS_BattTempSensorNum3 252;
BA_ "GenSigStartValue" SG_ 1520 VBU_BMS_BattTempSensorNum4 252;
BA_ "GenSigStartValue" SG_ 1520 VBU_BMS_BattTempSensorNum5 252;
BA_ "GenSigStartValue" SG_ 1520 VBU_BMS_BattTempSensorNum6 252;
BA_ "GenSigStartValue" SG_ 1520 VBU_BMS_BattTempSensorNum7 252;
BA_ "GenSigStartValue" SG_ 1520 VBU_BMS_BattTempSensorNum8 252;
BA_ "GenMsgCycleTime" BO_ 1521 1000;
BA_ "GenSigStartValue" SG_ 1521 VBU_BMS_BattTempSensorNum9 252;
BA_ "GenSigStartValue" SG_ 1521 VBU_BMS_BattTempSensorNum10 252;
BA_ "GenSigStartValue" SG_ 1521 VBU_BMS_BattTempSensorNum11 252;
BA_ "GenSigStartValue" SG_ 1521 VBU_BMS_BattTempSensorNum12 252;
BA_ "GenSigStartValue" SG_ 1521 VBU_BMS_BattTempSensorNum13 252;
BA_ "GenSigStartValue" SG_ 1521 VBU_BMS_BattTempSensorNum14 252;
BA_ "GenSigStartValue" SG_ 1521 VBU_BMS_BattTempSensorNum15 252;
BA_ "GenSigStartValue" SG_ 1521 VBU_BMS_BattTempSensorNum16 252;
BA_ "GenMsgCycleTime" BO_ 1522 1000;
BA_ "GenSigStartValue" SG_ 1522 VBU_BMS_BattTempSensorNum17 252;
BA_ "GenSigStartValue" SG_ 1522 VBU_BMS_BattTempSensorNum18 252;
BA_ "GenSigStartValue" SG_ 1522 VBU_BMS_BattTempSensorNum19 252;
BA_ "GenSigStartValue" SG_ 1522 VBU_BMS_BattTempSensorNum20 252;
BA_ "GenSigStartValue" SG_ 1522 VBU_BMS_BattTempSensorNum21 252;
BA_ "GenSigStartValue" SG_ 1522 VBU_BMS_BattTempSensorNum22 252;
BA_ "GenSigStartValue" SG_ 1522 VBU_BMS_BattTempSensorNum23 252;
BA_ "GenSigStartValue" SG_ 1522 VBU_BMS_BattTempSensorNum24 252;
BA_ "GenMsgCycleTime" BO_ 1523 1000;
BA_ "GenSigStartValue" SG_ 1523 VBU_BMS_BattTempSensorNum25 252;
BA_ "GenSigStartValue" SG_ 1523 VBU_BMS_BattTempSensorNum26 252;
BA_ "GenSigStartValue" SG_ 1523 VBU_BMS_BattTempSensorNum27 252;
BA_ "GenSigStartValue" SG_ 1523 VBU_BMS_BattTempSensorNum28 252;
BA_ "GenSigStartValue" SG_ 1523 VBU_BMS_BattTempSensorNum29 252;
BA_ "GenSigStartValue" SG_ 1523 VBU_BMS_BattTempSensorNum30 252;
BA_ "GenSigStartValue" SG_ 1523 VBU_BMS_BattTempSensorNum31 252;
BA_ "GenSigStartValue" SG_ 1523 VBU_BMS_BattTempSensorNum32 252;
BA_ "GenMsgCycleTime" BO_ 1524 1000;
BA_ "GenSigStartValue" SG_ 1524 VBU_BMS_BattTempSensorNum33 252;
BA_ "GenSigStartValue" SG_ 1524 VBU_BMS_BattTempSensorNum34 252;
BA_ "GenSigStartValue" SG_ 1524 VBU_BMS_BattTempSensorNum35 252;
BA_ "GenSigStartValue" SG_ 1524 VBU_BMS_BattTempSensorNum36 252;
BA_ "GenSigStartValue" SG_ 1524 VBU_BMS_BattTempSensorNum37 252;
BA_ "GenSigStartValue" SG_ 1524 VBU_BMS_BattTempSensorNum38 252;
BA_ "GenSigStartValue" SG_ 1524 VBU_BMS_BattTempSensorNum39 252;
BA_ "GenSigStartValue" SG_ 1524 VBU_BMS_BattTempSensorNum40 252;
BA_ "GenMsgCycleTime" BO_ 1525 1000;
BA_ "GenSigStartValue" SG_ 1525 VBU_BMS_BattTempSensorNum41 252;
BA_ "GenSigStartValue" SG_ 1525 VBU_BMS_BattTempSensorNum42 252;
BA_ "GenSigStartValue" SG_ 1525 VBU_BMS_BattTempSensorNum43 252;
BA_ "GenSigStartValue" SG_ 1525 VBU_BMS_BattTempSensorNum44 252;
BA_ "GenSigStartValue" SG_ 1525 VBU_BMS_BattTempSensorNum45 252;
BA_ "GenSigStartValue" SG_ 1525 VBU_BMS_BattTempSensorNum46 252;
BA_ "GenSigStartValue" SG_ 1525 VBU_BMS_BattTempSensorNum47 252;
BA_ "GenSigStartValue" SG_ 1525 VBU_BMS_BattTempSensorNum48 252;
BA_ "GenMsgCycleTime" BO_ 1526 1000;
BA_ "GenSigStartValue" SG_ 1526 VBU_BMS_BattTempSensorNum49 252;
BA_ "GenSigStartValue" SG_ 1526 VBU_BMS_BattTempSensorNum50 252;
BA_ "GenSigStartValue" SG_ 1526 VBU_BMS_BattTempSensorNum51 252;
BA_ "GenSigStartValue" SG_ 1526 VBU_BMS_BattTempSensorNum52 252;
BA_ "GenSigStartValue" SG_ 1526 VBU_BMS_BattTempSensorNum53 252;
BA_ "GenSigStartValue" SG_ 1526 VBU_BMS_BattTempSensorNum54 252;
BA_ "GenSigStartValue" SG_ 1526 VBU_BMS_BattTempSensorNum55 252;
BA_ "GenSigStartValue" SG_ 1526 VBU_BMS_BattTempSensorNum56 252;
BA_ "GenMsgCycleTime" BO_ 1527 1000;
BA_ "GenSigStartValue" SG_ 1527 VBU_BMS_BattTempSensorNum57 252;
BA_ "GenSigStartValue" SG_ 1527 VBU_BMS_BattTempSensorNum58 252;
BA_ "GenSigStartValue" SG_ 1527 VBU_BMS_BattTempSensorNum59 252;
BA_ "GenSigStartValue" SG_ 1527 VBU_BMS_BattTempSensorNum60 252;
BA_ "GenSigStartValue" SG_ 1527 VBU_BMS_BattTempSensorNum61 252;
BA_ "GenSigStartValue" SG_ 1527 VBU_BMS_BattTempSensorNum62 252;
BA_ "GenSigStartValue" SG_ 1527 VBU_BMS_BattTempSensorNum63 252;
BA_ "GenSigStartValue" SG_ 1527 VBU_BMS_BattTempSensorNum64 252;
BA_ "GenMsgCycleTime" BO_ 1528 1000;
BA_ "GenSigStartValue" SG_ 1528 VBU_BMS_BattTempSensorNum65 252;
BA_ "GenSigStartValue" SG_ 1528 VBU_BMS_BattTempSensorNum66 252;
BA_ "GenSigStartValue" SG_ 1528 VBU_BMS_BattTempSensorNum67 252;
BA_ "GenSigStartValue" SG_ 1528 VBU_BMS_BattTempSensorNum68 252;
BA_ "GenSigStartValue" SG_ 1528 VBU_BMS_BattTempSensorNum69 252;
BA_ "GenSigStartValue" SG_ 1528 VBU_BMS_BattTempSensorNum70 252;
BA_ "GenSigStartValue" SG_ 1528 VBU_BMS_BattTempSensorNum71 252;
BA_ "GenSigStartValue" SG_ 1528 VBU_BMS_BattTempSensorNum72 252;
BA_ "GenMsgCycleTime" BO_ 1473 10000;
VAL_ 946 TBOX_GyroTemperature 2046 "Invalid" ;
VAL_ 1378 MCU_MotorSts_GBT 255 "无效" 254 "异常；" 253 "Reserved；" 252 "Reserved；" 251 "Reserved；" 250 "Reserved；" 249 "Reserved；" 248 "Reserved；" 247 "Reserved；" 246 "Reserved；" 245 "Reserved；" 244 "Reserved；" 243 "Reserved；" 242 "Reserved；" 241 "Reserved；" 240 "Reserved；" 239 "Reserved；" 238 "Reserved；" 237 "Reserved；" 236 "Reserved；" 235 "Reserved；" 234 "Reserved；" 233 "Reserved；" 232 "Reserved；" 231 "Reserved；" 230 "Reserved；" 229 "Reserved；" 228 "Reserved；" 227 "Reserved；" 226 "Reserved；" 225 "Reserved；" 224 "Reserved；" 223 "Reserved；" 222 "Reserved；" 221 "Reserved；" 220 "Reserved；" 219 "Reserved；" 218 "Reserved；" 217 "Reserved；" 216 "Reserved；" 215 "Reserved；" 214 "Reserved；" 213 "Reserved；" 212 "Reserved；" 211 "Reserved；" 210 "Reserved；" 209 "Reserved；" 208 "Reserved；" 207 "Reserved；" 206 "Reserved；" 205 "Reserved；" 204 "Reserved；" 203 "Reserved；" 202 "Reserved；" 201 "Reserved；" 200 "Reserved；" 199 "Reserved；" 198 "Reserved；" 197 "Reserved；" 196 "Reserved；" 195 "Reserved；" 194 "Reserved；" 193 "Reserved；" 192 "Reserved；" 191 "Reserved；" 190 "Reserved；" 189 "Reserved；" 188 "Reserved；" 187 "Reserved；" 186 "Reserved；" 185 "Reserved；" 184 "Reserved；" 183 "Reserved；" 182 "Reserved；" 181 "Reserved；" 180 "Reserved；" 179 "Reserved；" 178 "Reserved；" 177 "Reserved；" 176 "Reserved；" 175 "Reserved；" 174 "Reserved；" 173 "Reserved；" 172 "Reserved；" 171 "Reserved；" 170 "Reserved；" 169 "Reserved；" 168 "Reserved；" 167 "Reserved；" 166 "Reserved；" 165 "Reserved；" 164 "Reserved；" 163 "Reserved；" 162 "Reserved；" 161 "Reserved；" 160 "Reserved；" 159 "Reserved；" 158 "Reserved；" 157 "Reserved；" 156 "Reserved；" 155 "Reserved；" 154 "Reserved；" 153 "Reserved；" 152 "Reserved；" 151 "Reserved；" 150 "Reserved；" 149 "Reserved；" 148 "Reserved；" 147 "Reserved；" 146 "Reserved；" 145 "Reserved；" 144 "Reserved；" 143 "Reserved；" 142 "Reserved；" 141 "Reserved；" 140 "Reserved；" 139 "Reserved；" 138 "Reserved；" 137 "Reserved；" 136 "Reserved；" 135 "Reserved；" 134 "Reserved；" 133 "Reserved；" 132 "Reserved；" 131 "Reserved；" 130 "Reserved；" 129 "Reserved；" 128 "Reserved；" 127 "Reserved；" 126 "Reserved；" 125 "Reserved；" 124 "Reserved；" 123 "Reserved；" 122 "Reserved；" 121 "Reserved；" 120 "Reserved；" 119 "Reserved；" 118 "Reserved；" 117 "Reserved；" 116 "Reserved；" 115 "Reserved；" 114 "Reserved；" 113 "Reserved；" 112 "Reserved；" 111 "Reserved；" 110 "Reserved；" 109 "Reserved；" 108 "Reserved；" 107 "Reserved；" 106 "Reserved；" 105 "Reserved；" 104 "Reserved；" 103 "Reserved；" 102 "Reserved；" 101 "Reserved；" 100 "Reserved；" 99 "Reserved；" 98 "Reserved；" 97 "Reserved；" 96 "Reserved；" 95 "Reserved；" 94 "Reserved；" 93 "Reserved；" 92 "Reserved；" 91 "Reserved；" 90 "Reserved；" 89 "Reserved；" 88 "Reserved；" 87 "Reserved；" 86 "Reserved；" 85 "Reserved；" 84 "Reserved；" 83 "Reserved；" 82 "Reserved；" 81 "Reserved；" 80 "Reserved；" 79 "Reserved；" 78 "Reserved；" 77 "Reserved；" 76 "Reserved；" 75 "Reserved；" 74 "Reserved；" 73 "Reserved；" 72 "Reserved；" 71 "Reserved；" 70 "Reserved；" 69 "Reserved；" 68 "Reserved；" 67 "Reserved；" 66 "Reserved；" 65 "Reserved；" 64 "Reserved；" 63 "Reserved；" 62 "Reserved；" 61 "Reserved；" 60 "Reserved；" 59 "Reserved；" 58 "Reserved；" 57 "Reserved；" 56 "Reserved；" 55 "Reserved；" 54 "Reserved；" 53 "Reserved；" 52 "Reserved；" 51 "Reserved；" 50 "Reserved；" 49 "Reserved；" 48 "Reserved；" 47 "Reserved；" 46 "Reserved；" 45 "Reserved；" 44 "Reserved；" 43 "Reserved；" 42 "Reserved；" 41 "Reserved；" 40 "Reserved；" 39 "Reserved；" 38 "Reserved；" 37 "Reserved；" 36 "Reserved；" 35 "Reserved；" 34 "Reserved；" 33 "Reserved；" 32 "Reserved；" 31 "Reserved；" 30 "Reserved；" 29 "Reserved；" 28 "Reserved；" 27 "Reserved；" 26 "Reserved；" 25 "Reserved；" 24 "Reserved；" 23 "Reserved；" 22 "Reserved；" 21 "Reserved；" 20 "Reserved；" 19 "Reserved；" 18 "Reserved；" 17 "Reserved；" 16 "Reserved；" 15 "Reserved；" 14 "Reserved；" 13 "Reserved；" 12 "Reserved；" 11 "Reserved；" 10 "Reserved；" 9 "Reserved；" 8 "Reserved；" 7 "Reserved；" 6 "Reserved；" 5 "Reserved；" 4 "准备；" 3 "关闭；" 2 "发电；" 1 "耗电；" 0 "Reserved；" ;
VAL_ 1378 MCU_MotoroffsetCalReq 1 "True" 0 "False" ;
VAL_ 805 WPTC_COM_VBU_Lost 1 "异常" 0 "正常" ;
VAL_ 805 WPTC_CUR_Over 1 "异常" 0 "正常" ;
VAL_ 805 WPTC_Temp_PCB_High 1 "异常" 0 "正常" ;
VAL_ 805 WPTC_OutletTemp_High 1 "异常" 0 "正常" ;
VAL_ 805 WPTC_InputTemp_High 1 "异常" 0 "正常" ;
VAL_ 805 WPTC_RunSts 3 "预留" 2 "故障" 1 "运行" 0 "关闭" ;
VAL_ 805 WPTC_HVSts 3 "高压欠压故障" 2 "高压过压故障" 1 "已供电" 0 "未供电" ;
VAL_ 1327 VBU_ErrorAction1 32 "StartBattErrorIndicator" 31 "InsulationErrorIndicator" 30 "CoolantOTIndicator" 29 "CoolantLowIndicator" 28 "ThremalRunawayIndicator" 27 "BattSysMaintainIndicator" 26 "BrakeErrorIndicator" 25 "RepairIndicator" 24 "BattErrorIndicator" 23 "TortoiseIndicator" 22 "SystemErrorIndicator" 21 "InhbCellBal" 20 "InhbACDsch" 19 "InhbWPTC" 18 "InhbRmtAC" 17 "InhbDC" 16 "InhbCRZ" 15 "InhbAPUWork" 14 "BattOfflineHvShutdown" 13 "FeedbackAllowPwr" 12 "LimSCHPwr" 11 "LimFCHPwr" 10 "InhbICH" 9 "InhbSCH" 8 "InhbFCH" 7 "LimDischargeAllowPwr" 6 "LimSpd" 5 "LimpHome" 4 "NormalUnloadTorque" 3 "NormalPowerOff" 2 "EmegyUnloadTorque" 1 "PwrDownEmegy" 0 "Default" ;
VAL_ 1327 VBU_ErrorAction2 32 "StartBattErrorIndicator" 31 "InsulationErrorIndicator" 30 "CoolantOTIndicator" 29 "CoolantLowIndicator" 28 "ThremalRunawayIndicator" 27 "BattSysMaintainIndicator" 26 "BrakeErrorIndicator" 25 "RepairIndicator" 24 "BattErrorIndicator" 23 "TortoiseIndicator" 22 "SystemErrorIndicator" 21 "InhbCellBal" 20 "InhbACDsch" 19 "InhbWPTC" 18 "InhbRmtAC" 17 "InhbDC" 16 "InhbCRZ" 15 "InhbAPUWork" 14 "BattOfflineHvShutdown" 13 "FeedbackAllowPwr" 12 "LimSCHPwr" 11 "LimFCHPwr" 10 "InhbICH" 9 "InhbSCH" 8 "InhbFCH" 7 "LimDischargeAllowPwr" 6 "LimSpd" 5 "LimpHome" 4 "NormalUnloadTorque" 3 "NormalPowerOff" 2 "EmegyUnloadTorque" 1 "PwrDownEmegy" 0 "Default" ;
VAL_ 1327 VBU_ErrorAction3 32 "StartBattErrorIndicator" 31 "InsulationErrorIndicator" 30 "CoolantOTIndicator" 29 "CoolantLowIndicator" 28 "ThremalRunawayIndicator" 27 "BattSysMaintainIndicator" 26 "BrakeErrorIndicator" 25 "RepairIndicator" 24 "BattErrorIndicator" 23 "TortoiseIndicator" 22 "SystemErrorIndicator" 21 "InhbCellBal" 20 "InhbACDsch" 19 "InhbWPTC" 18 "InhbRmtAC" 17 "InhbDC" 16 "InhbCRZ" 15 "InhbAPUWork" 14 "BattOfflineHvShutdown" 13 "FeedbackAllowPwr" 12 "LimSCHPwr" 11 "LimFCHPwr" 10 "InhbICH" 9 "InhbSCH" 8 "InhbFCH" 7 "LimDischargeAllowPwr" 6 "LimSpd" 5 "LimpHome" 4 "NormalUnloadTorque" 3 "NormalPowerOff" 2 "EmegyUnloadTorque" 1 "PwrDownEmegy" 0 "Default" ;
VAL_ 1327 VBU_ErrorAction4 32 "StartBattErrorIndicator" 31 "InsulationErrorIndicator" 30 "CoolantOTIndicator" 29 "CoolantLowIndicator" 28 "ThremalRunawayIndicator" 27 "BattSysMaintainIndicator" 26 "BrakeErrorIndicator" 25 "RepairIndicator" 24 "BattErrorIndicator" 23 "TortoiseIndicator" 22 "SystemErrorIndicator" 21 "InhbCellBal" 20 "InhbACDsch" 19 "InhbWPTC" 18 "InhbRmtAC" 17 "InhbDC" 16 "InhbCRZ" 15 "InhbAPUWork" 14 "BattOfflineHvShutdown" 13 "FeedbackAllowPwr" 12 "LimSCHPwr" 11 "LimFCHPwr" 10 "InhbICH" 9 "InhbSCH" 8 "InhbFCH" 7 "LimDischargeAllowPwr" 6 "LimSpd" 5 "LimpHome" 4 "NormalUnloadTorque" 3 "NormalPowerOff" 2 "EmegyUnloadTorque" 1 "PwrDownEmegy" 0 "Default" ;
VAL_ 1379 VBU_ACChargeSocketTemp 511 "Invalid" 510 "reserved" 509 "reserved" 508 "reserved" 507 "reserved" 506 "reserved" 505 "reserved" 504 "reserved" 503 "reserved" 502 "reserved" 501 "reserved" 500 "reserved" 499 "reserved" 498 "reserved" 497 "reserved" 496 "reserved" 495 "reserved" 494 "reserved" 493 "reserved" 492 "reserved" 491 "reserved" 490 "reserved" 489 "reserved" 488 "reserved" 487 "reserved" 486 "reserved" 485 "reserved" 484 "reserved" 483 "reserved" 482 "reserved" 481 "reserved" 480 "reserved" 479 "reserved" 478 "reserved" 477 "reserved" 476 "reserved" 475 "reserved" 474 "reserved" 473 "reserved" 472 "reserved" 471 "reserved" 470 "reserved" 469 "reserved" 468 "reserved" 467 "reserved" 466 "reserved" 465 "reserved" 464 "reserved" 463 "reserved" 462 "reserved" 461 "reserved" 460 "reserved" 459 "reserved" 458 "reserved" 457 "reserved" 456 "reserved" 455 "reserved" 454 "reserved" 453 "reserved" 452 "reserved" 451 "reserved" 450 "reserved" 449 "reserved" 448 "reserved" 447 "reserved" 446 "reserved" 445 "reserved" 444 "reserved" 443 "reserved" 442 "reserved" 441 "reserved" 440 "reserved" 439 "reserved" 438 "reserved" 437 "reserved" 436 "reserved" 435 "reserved" 434 "reserved" 433 "reserved" 432 "reserved" 431 "reserved" 430 "reserved" 429 "reserved" 428 "reserved" 427 "reserved" 426 "reserved" 425 "reserved" 424 "reserved" 423 "reserved" 422 "reserved" 421 "reserved" 420 "reserved" 419 "reserved" 418 "reserved" 417 "reserved" 416 "reserved" 415 "reserved" 414 "reserved" 413 "reserved" 412 "reserved" 411 "reserved" 410 "reserved" 409 "reserved" 408 "reserved" 407 "reserved" 406 "reserved" 405 "reserved" 404 "reserved" 403 "reserved" 402 "reserved" 401 "reserved" 400 "reserved" 399 "reserved" 398 "reserved" 397 "reserved" 396 "reserved" 395 "reserved" 394 "reserved" 393 "reserved" 392 "reserved" 391 "reserved" 390 "reserved" 389 "reserved" 388 "reserved" 387 "reserved" 386 "reserved" 385 "reserved" 384 "reserved" 383 "reserved" 382 "reserved" 381 "reserved" 380 "reserved" 379 "reserved" 378 "reserved" 377 "reserved" 376 "reserved" 375 "reserved" 374 "reserved" 373 "reserved" 372 "reserved" 371 "reserved" 370 "reserved" 369 "reserved" 368 "reserved" 367 "reserved" 366 "reserved" 365 "reserved" 364 "reserved" 363 "reserved" 362 "reserved" 361 "reserved" 360 "reserved" 359 "reserved" 358 "reserved" 357 "reserved" 356 "reserved" 355 "reserved" 354 "reserved" 353 "reserved" 352 "reserved" 351 "reserved" 350 "reserved" 349 "reserved" 348 "reserved" 347 "reserved" 346 "reserved" 345 "reserved" 344 "reserved" 343 "reserved" 342 "reserved" 341 "reserved" ;
VAL_ 1379 VBU_FastCharge_A 1 "active" 0 "inactive" ;
VAL_ 1379 VBU_DCChargeSocketTemp 511 "Invalid" 510 "reserved" 509 "reserved" 508 "reserved" 507 "reserved" 506 "reserved" 505 "reserved" 504 "reserved" 503 "reserved" 502 "reserved" 501 "reserved" 500 "reserved" 499 "reserved" 498 "reserved" 497 "reserved" 496 "reserved" 495 "reserved" 494 "reserved" 493 "reserved" 492 "reserved" 491 "reserved" 490 "reserved" 489 "reserved" 488 "reserved" 487 "reserved" 486 "reserved" 485 "reserved" 484 "reserved" 483 "reserved" 482 "reserved" 481 "reserved" 480 "reserved" 479 "reserved" 478 "reserved" 477 "reserved" 476 "reserved" 475 "reserved" 474 "reserved" 473 "reserved" 472 "reserved" 471 "reserved" 470 "reserved" 469 "reserved" 468 "reserved" 467 "reserved" 466 "reserved" 465 "reserved" 464 "reserved" 463 "reserved" 462 "reserved" 461 "reserved" 460 "reserved" 459 "reserved" 458 "reserved" 457 "reserved" 456 "reserved" 455 "reserved" 454 "reserved" 453 "reserved" 452 "reserved" 451 "reserved" 450 "reserved" 449 "reserved" 448 "reserved" 447 "reserved" 446 "reserved" 445 "reserved" 444 "reserved" 443 "reserved" 442 "reserved" 441 "reserved" 440 "reserved" 439 "reserved" 438 "reserved" 437 "reserved" 436 "reserved" 435 "reserved" 434 "reserved" 433 "reserved" 432 "reserved" 431 "reserved" 430 "reserved" 429 "reserved" 428 "reserved" 427 "reserved" 426 "reserved" 425 "reserved" 424 "reserved" 423 "reserved" 422 "reserved" 421 "reserved" 420 "reserved" 419 "reserved" 418 "reserved" 417 "reserved" 416 "reserved" 415 "reserved" 414 "reserved" 413 "reserved" 412 "reserved" 411 "reserved" 410 "reserved" 409 "reserved" 408 "reserved" 407 "reserved" 406 "reserved" 405 "reserved" 404 "reserved" 403 "reserved" 402 "reserved" 401 "reserved" 400 "reserved" 399 "reserved" 398 "reserved" 397 "reserved" 396 "reserved" 395 "reserved" 394 "reserved" 393 "reserved" 392 "reserved" 391 "reserved" 390 "reserved" 389 "reserved" 388 "reserved" 387 "reserved" 386 "reserved" 385 "reserved" 384 "reserved" 383 "reserved" 382 "reserved" 381 "reserved" 380 "reserved" 379 "reserved" 378 "reserved" 377 "reserved" 376 "reserved" 375 "reserved" 374 "reserved" 373 "reserved" 372 "reserved" 371 "reserved" 370 "reserved" 369 "reserved" 368 "reserved" 367 "reserved" 366 "reserved" 365 "reserved" 364 "reserved" 363 "reserved" 362 "reserved" 361 "reserved" 360 "reserved" 359 "reserved" 358 "reserved" 357 "reserved" 356 "reserved" 355 "reserved" 354 "reserved" 353 "reserved" 352 "reserved" 351 "reserved" 350 "reserved" 349 "reserved" 348 "reserved" 347 "reserved" 346 "reserved" 345 "reserved" 344 "reserved" 343 "reserved" 342 "reserved" 341 "reserved" ;
VAL_ 401 APS_SystemSts 7 "Suspend" 6 "Terminated" 5 "Failure" 4 "Completed" 3 "Guidance active" 2 "Searching" 1 "Standby" 0 "Off" ;
VAL_ 401 APS_Active 1 "Active" 0 "Not active" ;
VAL_ 401 APS_HU_Failure 1 "failure" 0 "Not failure" ;
VAL_ 401 APS_VBU_Speed_Limitation 63 "Invalid" ;
VAL_ 401 APS_VBU_Target_Gear_Request 7 "Reserved" 6 "Reserved" 5 "Reserved" 4 "APADrvDirRqVBU_DRIVE" 3 "APADrvDirRqVBU_NEUTRAL" 2 "APADrvDirRqVBU_Reverse" 1 "APADrvDirRqVBU_Park" 0 "APADrvDirRqVBU_Idle" ;
VAL_ 401 APS_AVM_HU_CurrentSts 7 "Reserved" 6 "APS Request Exit" 5 "VideoStream Output Error" 4 "View Mode-HalfScreen" 3 "View Mode-SoftKey" 2 "View Mode-APA" 1 "View Mode-R" 0 "Not Ready" ;
VAL_ 401 APS_HU_ParkPrompttone 1 "Active" 0 "Not active" ;
VAL_ 401 APS_VBU_APAFailed 1 "APA Failure" 0 "Normal" ;
VAL_ 401 APS_AVM_FactoryMode 1 "Factory_Mode" 0 "Normal_Mode" ;
VAL_ 401 APS_R_Gear_RequestTips 3 "Reserved" 2 "RequestTips" 1 "NoRequestTips" 0 "Default" ;
VAL_ 401 APS_VBU_BrakeModeSts 7 "reserved" 6 "reserved" 5 "ParkAssist_Abort(reserved)" 4 "ParkAssist_Suspend(reserved)" 3 "ParkAssist_ManeuverFinished(reserved)" 2 "ParkAssist_Active" 1 "ParkAssist_Standby" 0 "ParkAssist_Int" ;
VAL_ 624 APS_APAFailed 1 "APA Failure" 0 "Normal" ;
VAL_ 624 APS_CmdEPSSts 3 "Reserved" 2 "EPS control active" 1 "Control EPS request" 0 "No request" ;
VAL_ 624 APS_FailureBrakeMode 3 "ParkAssist_ Emergency" 2 "ParkAssist_Comfort" 1 "ParkAssist_Idle" 0 "ParkAssist_NoFailure" ;
VAL_ 624 APS_BrakeModeSts 7 "reserved" 6 "reserved" 5 "ParkAssist_Abort" 4 "ParkAssist_Suspend" 3 "ParkAssist_ManeuverFinished" 2 "ParkAssist_Active" 1 "ParkAssist_Standby" 0 "ParkAssist_Int" ;
VAL_ 624 APS_BrakeFunctionMode 15 "reserved" 14 "reserved" 13 "reserved" 12 "reserved" 11 "reserved" 10 "reserved" 9 "reserved" 8 "ParkAssist_ManeuverAccelerationAvoidance" 7 "ParkAssist_ManeuverComfortBrake" 6 "ParkAssist_ManeuverEmergencyBrake" 5 "ParkAssist_RemoteParkOut 预留" 4 "ParkAssist_RemoteParkOut 预留" 3 "ParkAssist_AutomaticPark" 2 "ParkAssist_ParkEmergencyBrake" 1 "ParkAssist_ParkComfortBrake" 0 "ParkAssist_NoSignal" ;
VAL_ 624 APS_ESC_Target_Gear_Request 4 "APADrvDirRqESP_DRIVE" 3 "APADrvDirRqESP_NEUTRAL" 2 "APADrvDirRqESP_Reverse" 1 "APADrvDirRqESP_Park" 0 "APADrvDirRqESP_Idle" ;
VAL_ 625 APS_APS_AutoSearchSts 7 "find out only slot-R" 6 "find out only slot-L" 5 "wait for vehicle driver confirm park" 4 "find out slot-Both,and “P” on R side" 3 "wait for vehicle slow down" 2 "find out slot-Both,and “P” on L side" 1 "slot searching" 0 "not in search mode" ;
VAL_ 625 APS_APS_ParkOutChkResult 1 "OK" 0 "NOK" ;
VAL_ 625 APS_APS_SuspendedReason 7 "gas pedal pressed" 6 "RPA Bluetooth invalid" 5 "mirror fold" 4 "trunk open" 3 "any door open" 2 "obstacle on path" 1 "Active Suspended" 0 "not suspended" ;
VAL_ 625 APS_APS_AbortReason 31 "Reserved" 30 "Reserved" 29 "Reserved" 28 "Reserved" 27 "Reserved" 26 "Reserved" 25 "Reserved" 24 "Reserved" 23 "Reserved" 22 "Reserved" 21 "Reserved" 20 "Reserved" 19 "Reserved" 18 "Reserved" 17 "RPA车门未解锁" 16 "路径规划失败" 15 "泊车空间受限" 14 "暂停次数超限" 13 "泊车次数超限" 12 "泊车超时" 11 "暂停超时" 10 "坡度过大" 9 "车速过大" 8 "block" 7 "ACC or AEB active" 6 "ESP failure" 5 "PA failure" 4 "EPS failure" 3 "VBU failure" 2 "传感器故障" 1 "APS内部故障" 0 "Not abort" ;
VAL_ 625 APS_APS_CurrentParkType 7 "reserved" 6 "reserved" 5 "reserved" 4 "parallel parkout" 3 "diagonal parkin" 2 "parallel parkin" 1 "perpendicular parkin" 0 "not selected" ;
VAL_ 625 APS_APS_OverrideReason 7 "reserved" 6 "overrode by RPA door lock" 5 "Overrode by RPA APP quit" 4 "overrode by voice quit" 3 "overrode by switch" 2 "overrode by gear shift" 1 "overrode by oversteer" 0 "not override" ;
VAL_ 625 APS_APS_VehicleDirection 3 "reserved" 2 "backward" 1 "forward" 0 "stopped" ;
VAL_ 625 APS_APS_TerminatedType 3 "abort" 2 "reserved" 1 "driver override" 0 "not Terminated" ;
VAL_ 625 APS_RemoteParkIn_Status 7 "RemotePark_Error" 6 "RemotePark_Quit" 5 "RemoteParkIn_Complete" 4 "RemoteParkIn_Suspended" 3 "RemoteParkIn_Parking" 2 "RemoteParkIn_Start" 1 "Standy" 0 "OFF" ;
VAL_ 625 APS_BCM_RemoteParkIn_Status 1 "Active" 0 "NoActive" ;
VAL_ 625 APS_BCM_DoubleFlash 1 "Active" 0 "default" ;
VAL_ 625 APS_BCM_AllDoorUnLock_Door 1 "Active" 0 "default" ;
VAL_ 625 APS_BCM_PowerOffReq 1 "请求BCM下电" 0 "Default" ;
VAL_ 625 APS_ParkDirection 3 "Right" 2 "Left" 1 "front" 0 "Default" ;
VAL_ 625 APS_APP_RPA_Status 3 "一键泊出" 2 "一键泊入" 1 "召唤" 0 "default" ;
VAL_ 920 ORM_LeftMirrorMotor1fault 1 "fault" 0 "no fault" ;
VAL_ 920 ORM_LeftMirrorMotor2fault 1 "fault" 0 "no fault" ;
VAL_ 920 ORM_RightMirrorMotor1fault 1 "fault" 0 "no fault" ;
VAL_ 920 ORM_RightMirrorMotor2fault 1 "fault" 0 "no fault" ;
VAL_ 800 EAC_StartSts_F 1 "Error" 0 "No Error" ;
VAL_ 800 EAC_UnderVoltage_F 1 "Error" 0 "No Error" ;
VAL_ 800 EAC_OverVoltage_F 1 "Error" 0 "No Error" ;
VAL_ 800 EAC_OverCurrent_F 1 "Error" 0 "No Error" ;
VAL_ 800 EAC_OverTemp_F 1 "Error" 0 "No Error" ;
VAL_ 800 EAC_motor_desync 1 "Error" 0 "No Error" ;
VAL_ 800 EAC_Status 3 "System fault" 2 "Active" 1 "Not active" 0 "initi" ;
VAL_ 800 EAC_StandbyUnderVol_F 1 "Error" 0 "No Error" ;
VAL_ 800 EAC_StandbyOverVol_F 1 "Error" 0 "No Error" ;
VAL_ 800 EAC_Communication_Error 1 "Error" 0 "No Error" ;
VAL_ 800 EAC_OverCurrentDropFreq 1 "Active" 0 "Not active" ;
VAL_ 800 EAC_OverPeakCurrent 1 "Active" 0 "Not active" ;
VAL_ 806 APTC_WorkSts 3 "Reserved" 2 "System fault" 1 "运行" 0 "关闭" ;
VAL_ 806 APTC_ErrorCode 15 "Reserved" 14 "Reserved" 13 "Reserved" 12 "Reserved" 11 "接收的PWM值不在0-100范围" 10 "CAN接收超时" 9 "PTC短路" 8 "PCB板温度高" 7 "干烧" 6 "PTC表面温度高" 5 "过流" 4 "PCB板NTC坏" 3 "PTC NTC坏" 2 "PTC电流小(持续2S)" 1 "IGBT短路" 0 "无故障" ;
VAL_ 806 APTC_HVSts 7 "Reserved" 6 "Reserved" 5 "Reserved" 4 "高压反接" 3 "高压欠压故障" 2 "高压过压故障" 1 "已供电" 0 "未供电" ;
VAL_ 806 APTC_ErrorLevel 3 "Level_3" 2 "Level_2" 1 "Level_1" 0 "No Error" ;
VAL_ 928 ICM_ODOTotal 16777215 "Invalid" ;
VAL_ 928 ICM_DisPlayVehicleSpeed 4095 "Invalid" ;
VAL_ 928 ICM_LowBrakeFluidLevel 1 "Low" 0 "normal" ;
VAL_ 928 ICM_WashingLiquidLevel 1 "Low" 0 "normal" ;
VAL_ 928 ICM_maintenanceState 1 "需保养" 0 "无需保养" ;
VAL_ 928 ICM_ODOTotalFB 3 "Invalid" 2 "处理失败" 1 "处理成功" 0 "Default" ;
VAL_ 928 ICM_Error_Sts 3 "Invalid" 2 "Error" 1 "No Error" 0 "Default" ;
VAL_ 928 ICM_PrevmaintmileagesFB 3 "Invalid" 2 "处理失败" 1 "处理成功" 0 "Default" ;
VAL_ 928 ICM_Display_Mode 3 "Night" 2 "Day" 1 "Auto" 0 "Default" ;
VAL_ 928 ICM_SubMileage_Reset 1 "Reset" 0 "default" ;
VAL_ 896 RLS_RQ_LowBeam 3 "Reserved" 2 "RQ on Low Beam" 1 "No RQ on Low Beam" 0 "default" ;
VAL_ 896 RB_Hall_error 1 "故障" 0 "正常" ;
VAL_ 896 RB_Relay_error 1 "故障" 0 "正常" ;
VAL_ 896 RB_ResponseError 1 "error/响应故障" 0 "normal/正常" ;
VAL_ 896 RB_RunningStatus 3 "Reserved" 2 "motor is closing" 1 "motor is opening" 0 "motor is not running" ;
VAL_ 896 RB_Initialization_Status 3 "初始化失败" 2 "初始化完成" 1 "正在初始化中" 0 "未初始化" ;
VAL_ 896 RLS_Fault_Rain 1 "Status Fault" 0 "Normal Status" ;
VAL_ 896 RB_Position 127 "No position is known" 100 "遮阳帘开度100%" 0 "遮阳帘开度0%" ;
VAL_ 896 RLS_Fault_Light 1 "Status Fault" 0 "Normal Status" ;
VAL_ 896 RLS_ResponseError 1 "Error" 0 "No error" ;
VAL_ 896 RB_Reversiering 1 "反转(防夹)" 0 "未反转" ;
VAL_ 896 RB_Thermalprotection 1 "thermal protection active" 0 "thermal protection inactive" ;
VAL_ 896 RB_UBat_LowVoltage 1 "欠压" 0 "正常" ;
VAL_ 896 RB_UBat_OverVoltage 1 "过压" 0 "正常" ;
VAL_ 896 RB_OpenKey_Status 1 "active" 0 "inactive" ;
VAL_ 896 RB_CloseKey_Status 1 "active" 0 "inactive" ;
VAL_ 784 BCM_SystemPowerMode 3 "Ready" 2 "ON" 1 "Reserved" 0 "OFF" ;
VAL_ 784 BCM_AntiThelf_Sts 3 "Warning" 2 "Prearm" 1 "Arm(armed || partial armed)" 0 "Disarm" ;
VAL_ 784 BCM_DriverLock_Sts 3 "Invalid" 2 "Lock" 1 "Unlock" 0 "Default" ;
VAL_ 784 BCM_StartRequest 1 "Request" 0 "No Request" ;
VAL_ 784 BCM_partialarmed_ActiveSts 1 "active" 0 "Inactive" ;
VAL_ 784 BCM_Hood_Sts 3 "Invalid" 2 "Close" 1 "Open" 0 "Default" ;
VAL_ 784 BCM_ChargerLock_ControlSts 1 "active" 0 "Not active" ;
VAL_ 784 BCM_PositionLight_Sts 1 "ON" 0 "OFF" ;
VAL_ 784 BCM_TurnLeftLight_Sts 1 "ON" 0 "OFF" ;
VAL_ 784 BCM_TurnRightLight_Sts 1 "ON" 0 "OFF" ;
VAL_ 784 BCM_Daylight_Sts 1 "ON" 0 "OFF" ;
VAL_ 784 BCM_HighBeam_Sts 1 "ON" 0 "OFF" ;
VAL_ 784 BCM_LowBeam_Sts 1 "ON" 0 "OFF" ;
VAL_ 784 BCM_AutoHeadlight_Sts 1 "active" 0 "inactive" ;
VAL_ 784 BCM_brakeLight_Sts 1 "ON" 0 "OFF" ;
VAL_ 784 BCM_HazardLight_Sts 1 "ON" 0 "OFF" ;
VAL_ 784 BCM_RearFoglight_Sts 1 "ON" 0 "OFF" ;
VAL_ 784 BCM_BrkSw_Sts 3 "Invalid" 2 "Reserved" 1 "Pressed" 0 "NotPressed" ;
VAL_ 784 BCM_FL_Door_Sts 3 "Invalid" 2 "Close" 1 "Open" 0 "Default" ;
VAL_ 784 BCM_FR_Door_Sts 3 "Invalid" 2 "Close" 1 "Open" 0 "Default" ;
VAL_ 784 BCM_RL_Door_Sts 3 "Invalid" 2 "Close" 1 "Open" 0 "Default" ;
VAL_ 784 BCM_RR_Door_Sts 3 "Invalid" 2 "Close" 1 "Open" 0 "Default" ;
VAL_ 784 BCM_Trunk_Door_Sts 3 "Invalid" 2 "Close" 1 "Open" 0 "Default" ;
VAL_ 784 BCM_PLGOutsideSW 1 "active" 0 "inactive" ;
VAL_ 784 BCM_HornControlsts 1 "active" 0 "inactive" ;
VAL_ 784 BCM_Fwiper_Mist_Sts 1 "ON" 0 "OFF" ;
VAL_ 784 BCM_Fwiper_washing_Sts 1 "ON" 0 "OFF" ;
VAL_ 784 BCM_FWiper_Sts 7 "Invalid" 6 "Reserved" 5 "Reserved" 4 "Maintenance Mode" 3 "Reserved" 2 "HS Speed" 1 "LS speed" 0 "OFF" ;
VAL_ 784 BCM_RWiper_Sts 3 "Invalid" 2 "Rear Washer" 1 "Rear Wiper ON" 0 "OFF" ;
VAL_ 784 BCM_RearViewFoldSts 1 "展开" 0 "折叠" ;
VAL_ 784 BCM_RearViewAutoSWSts 1 "手动" 0 "auto" ;
VAL_ 784 BCM_RearViewHeatSts 1 "active" 0 "inactive" ;
VAL_ 784 BCM_WorkMode 3 "存储模式" 2 "运输模式" 1 "生产模式" 0 "正常模式" ;
VAL_ 784 BCM_TBOXUnlockEnableSts 1 "enable" 0 "disable" ;
VAL_ 784 BCM_FwiperServiceSWsts 1 "on（进入维修模式）" 0 "off（退出维修模式）" ;
VAL_ 784 BCM_SupplyVoltage 255 "Invalid" ;
VAL_ 784 BCM_PowerONorOFF_Reason 9 "非off电状态-诊断2F服务请求上电" 8 "非off电状态-TBOX请求上电" 7 "非off电状态-SSB触发上电" 6 "off电状态-ACC档无操作超时1小时后下电" 5 "预留" 4 "off电状态-诊断11服务控制下电" 3 "off电状态-诊断2F服务控制下电" 2 "off电状态-APS请求下电" 1 "off电状态-SSB长按触发下电" 0 "off电状态-SSB短按触发下电" ;
VAL_ 665 FLWM_DenormalizeSt 1 "Initialized" 0 "Not initialized" ;
VAL_ 665 FRWM_DenormalizeSt 1 "Initialized" 0 "Not initialized" ;
VAL_ 665 RLWM_DenormalizeSt 1 "Initialized" 0 "Not initialized" ;
VAL_ 665 RRWM_DenormalizeSt 1 "Initialized" 0 "Not initialized" ;
VAL_ 665 CSW_Key_LiftGate 3 "Reserved" 2 "Reserved" 1 "pressed" 0 "Key not pressed" ;
VAL_ 665 CSW_WindowLOCK 3 "Reserved" 2 "Reserved" 1 "pressed" 0 "Key not pressed" ;
VAL_ 665 CSW_Key_FrontDefrost 3 "Reserved" 2 "Reserved" 1 "pressed" 0 "Key not pressed" ;
VAL_ 665 RLWM_WindowLOCKSts 1 "lock" 0 "unlock" ;
VAL_ 665 RRWM_WindowLOCKSts 1 "lock" 0 "unlock" ;
VAL_ 665 ESCL_DiagError 1 "Authenticatio error" 0 "Authenticatio ok" ;
VAL_ 665 ESCL_authentification_error 1 "Authenticatio error" 0 "Authenticatio ok" ;
VAL_ 665 ESCL_unlock_status 1 "unlocked" 0 "not unlocked" ;
VAL_ 665 ESCL_lock_status 1 "locked" 0 "not locked" ;
VAL_ 665 FLWM_AntiPinchDetecte 1 "Detected" 0 "No Detected" ;
VAL_ 665 FRWM_AntiPinchDetecte 1 "Detected" 0 "No Detected" ;
VAL_ 665 RLWM_AntiPinchDetecte 1 "Detected" 0 "No Detected" ;
VAL_ 665 RRWM_AntiPinchDetecte 1 "Detected" 0 "No Detected" ;
VAL_ 665 FLWM_Opend 1 "Opend" 0 "No Opend" ;
VAL_ 665 FLWM_Closed 1 "Closed" 0 "No Closed" ;
VAL_ 665 FRWM_Opend 1 "Opend" 0 "No Opend" ;
VAL_ 665 FRWM_Closed 1 "Closed" 0 "No Closed" ;
VAL_ 665 RLWM_Opend 1 "Opend" 0 "No Opend" ;
VAL_ 665 RLWM_Closed 1 "Closed" 0 "No Closed" ;
VAL_ 665 RRWM_Opend 1 "Opend" 0 "No Opend" ;
VAL_ 665 RRWM_Closed 1 "Closed" 0 "No Closed" ;
VAL_ 665 FLWM_WinMoveSt 3 "Invalid" 2 "Window Openning" 1 "Window Closing" 0 "Stopped" ;
VAL_ 665 FRWM_WinMoveSt 3 "Invalid" 2 "Window Openning" 1 "Window Closing" 0 "Stopped" ;
VAL_ 665 RLWM_WinMoveSt 3 "Invalid" 2 "Window Openning" 1 "Window Closing" 0 "Stopped" ;
VAL_ 665 RRWM_WinMoveSt 3 "Invalid" 2 "Window Openning" 1 "Window Closing" 0 "Stopped" ;
VAL_ 583 BCM_StartWarning 7 "Reserved" 6 "Reserved" 5 "Reserved" 4 "Reserved" 3 "Reserved" 2 "档位未在 P/N档（仪表提醒）" 1 "动力防盗认证失败（仪表提醒）" 0 "默认值" ;
VAL_ 583 BCM_PowerOffWarning 7 "Reserved" 6 "Reserved" 5 "Reserved" 4 "Reserved" 3 "Reserved" 2 "发生长按启动开关紧急下电" 1 "发生异常下电提醒（仪表提醒）" 0 "默认值（发生正常下电，上电或下电稳态）" ;
VAL_ 583 BCM_PowerONWarning 7 "Reserved" 6 "Reserved" 5 "钥匙未学习（仪表提醒）" 4 "预留" 3 "远程禁止上电" 2 "上电失败，ESCL解锁失败（仪表提醒）" 1 "上电失败，车内无合法钥匙（仪表提醒）" 0 "默认值" ;
VAL_ 583 BCM_AuthSts 3 "保留" 2 "防盗认证成功" 1 "防盗认证失败" 0 "上电默认状态" ;
VAL_ 583 BCM_ESCLSysFail 3 "预留" 2 "预留" 1 "故障" 0 "无故障" ;
VAL_ 583 BCM_LODO_Reminder 3 "预留" 2 "预留" 1 "提醒" 0 "无提醒" ;
VAL_ 583 BCM_brakeLightfail 3 "预留" 2 "预留" 1 "提醒" 0 "无提醒" ;
VAL_ 583 BCM_HoodOpen_Feedback 1 "Open/前舱盖未关" 0 "default" ;
VAL_ 583 BCM_TrunkOpen_Feedback 1 "Open/后盖未关" 0 "default" ;
VAL_ 583 BCM_Drivedoorlcok_Feedback 1 "Unlock/主驾车门未锁" 0 "default" ;
VAL_ 583 BCM_FLDoorOpen_Feedback 1 "Open/车门未关" 0 "default" ;
VAL_ 583 BCM_FRDoorOpen_Feedback 1 "Open/车门未关" 0 "default" ;
VAL_ 583 BCM_RRDoorOpen_Feedback 1 "Open/车门未关" 0 "default" ;
VAL_ 583 BCM_RLDoorOpen_Feedback 1 "Open/车门未关" 0 "default" ;
VAL_ 583 BCM_FLWindowOpen_Feedback 1 "Open/车窗未关" 0 "default" ;
VAL_ 583 BCM_FRWindowOpen_Feedback 1 "Open/车窗未关" 0 "default" ;
VAL_ 583 BCM_RRWindowOpen_Feedback 1 "Open/车窗未关" 0 "default" ;
VAL_ 583 BCM_RLWindowOpen_Feedback 1 "Open/车窗未关" 0 "default" ;
VAL_ 1282 TPMS_FL_Warning_Sts 1 "Warning" 0 "No Warning" ;
VAL_ 1282 TPMS_FR_Warning_Sts 1 "Warning" 0 "No Warning" ;
VAL_ 1282 TPMS_RL_Warning_Sts 1 "Warning" 0 "No Warning" ;
VAL_ 1282 TPMS_RR_Warning_Sts 1 "Warning" 0 "No Warning" ;
VAL_ 1282 TPMS_FL_Fault_Sts 1 "Fault" 0 "No Fault" ;
VAL_ 1282 TPMS_FR_Fault_Sts 1 "Fault" 0 "No Fault" ;
VAL_ 1282 TPMS_RL_Fault_Sts 1 "Fault" 0 "No Fault" ;
VAL_ 1282 TPMS_RR_Fault_Sts 1 "Fault" 0 "No Fault" ;
VAL_ 1282 TPMS_FL_leakage_Sts 1 "Quik_leakage" 0 "Normal" ;
VAL_ 1282 TPMS_FR_leakage_Sts 1 "Quik_leakage" 0 "Normal" ;
VAL_ 1282 TPMS_RL_leakage_Sts 1 "Quik_leakage" 0 "Normal" ;
VAL_ 1282 TPMS_RR_leakage_Sts 1 "Quik_leakage" 0 "Normal" ;
VAL_ 1282 TPMS_FLPressure_Sts 3 "Reserved" 2 "high_pressure" 1 "Low_pressure" 0 "Normal" ;
VAL_ 1282 TPMS_FRPressure_Sts 3 "Reserved" 2 "high_pressure" 1 "Low_pressure" 0 "Normal" ;
VAL_ 1282 TPMS_RLPressure_Sts 3 "Reserved" 2 "high_pressure" 1 "Low_pressure" 0 "Normal" ;
VAL_ 1282 TPMS_RRPressure_Sts 3 "Reserved" 2 "high_pressure" 1 "Low_pressure" 0 "Normal" ;
VAL_ 1282 TPMS_FL_HighTemp_Sts 1 "High_Temp" 0 "Normal" ;
VAL_ 1282 TPMS_FR_HighTemp_Sts 1 "High_Temp" 0 "Normal" ;
VAL_ 1282 TPMS_RL_HighTemp_Sts 1 "High_Temp" 0 "Normal" ;
VAL_ 1282 TPMS_RR_HighTemp_Sts 1 "High_Temp" 0 "Normal" ;
VAL_ 1282 TPMS_FL_battery_Sts 1 "battery_low" 0 "Normal" ;
VAL_ 1282 TPMS_FR_battery_Sts 1 "battery_low" 0 "Normal" ;
VAL_ 1282 TPMS_RL_battery_Sts 1 "battery_low" 0 "Normal" ;
VAL_ 1282 TPMS_RR_battery_Sts 1 "battery_low" 0 "Normal" ;
VAL_ 1282 TPMS_FL_SensorError_Sts 1 "Sensor_Error" 0 "Normal" ;
VAL_ 1282 TPMS_FR_SensorError_Sts 1 "Sensor_Error" 0 "Normal" ;
VAL_ 1282 TPMS_RL_SensorError_Sts 1 "Sensor_Error" 0 "Normal" ;
VAL_ 1282 TPMS_RR_SensorError_Sts 1 "Sensor_Error" 0 "Normal" ;
VAL_ 1282 TPMS_FL_failure_Sts 1 "Sensor_failure" 0 "Normal" ;
VAL_ 1282 TPMS_FR_failure_Sts 1 "Sensor_failure" 0 "Normal" ;
VAL_ 1282 TPMS_RL_failure_Sts 1 "Sensor_failure" 0 "Normal" ;
VAL_ 1282 TPMS_RR_failure_Sts 1 "Sensor_failure" 0 "Normal" ;
VAL_ 1282 TPMS_FL_learn_Sts 3 "ID_repeat" 2 "Learn_succcess" 1 "Waiting_learn" 0 "No_learn" ;
VAL_ 1282 TPMS_FR_learn_Sts 3 "ID_repeat" 2 "Learn_succcess" 1 "Waiting_learn" 0 "No_learn" ;
VAL_ 1282 TPMS_RL_learn_Sts 3 "ID_repeat" 2 "Learn_succcess" 1 "Waiting_learn" 0 "No_learn" ;
VAL_ 1282 TPMS_RR_learn_Sts 3 "ID_repeat" 2 "Learn_succcess" 1 "Waiting_learn" 0 "No_learn" ;
VAL_ 1282 TPMS_FL_CRC_Error 1 "Error" 0 "No_Error" ;
VAL_ 1282 TPMS_FR_CRC_Error 1 "Error" 0 "No_Error" ;
VAL_ 1282 TPMS_RL_CRC_Error 1 "Error" 0 "No_Error" ;
VAL_ 1282 TPMS_RR_CRC_Error 1 "Error" 0 "No_Error" ;
VAL_ 835 PLG_Trunk_Sts 7 "Latch cinching正在上锁" 6 "Latch releasing正在解锁" 5 "PLG stopped" 4 "Closing" 3 "Opening" 2 "Fully closed" 1 "Fully opened" 0 "PLG unknown" ;
VAL_ 835 PLG_Shutface_SW 1 "active导通" 0 "inactive断开" ;
VAL_ 835 PLG_Latc_PawlSW 1 "active尾门打开" 0 "inactive尾门关闭" ;
VAL_ 835 PLG_Latch_SecondarySW 1 "active导通" 0 "inactive断开" ;
VAL_ 835 PLG_Latch_0PositionSW 1 "active导通" 0 "inactive断开" ;
VAL_ 835 PLG_LearnedSts 1 "Learned" 0 "Unlearn" ;
VAL_ 835 PLG_KickActiveReq 1 "Request" 0 "NoRequest" ;
VAL_ 835 PLG_HallSensor 1 "NOK" 0 "OK" ;
VAL_ 835 PLG_OpenAngValid 1 "SignalInvalid" 0 "Signalvalid" ;
VAL_ 835 PLG_LatchMorSts 3 "SignalInvalid" 2 "ShortBattery" 1 "ShortGround" 0 "OK" ;
VAL_ 835 PLG_GearMor1Sts 3 "SignalInvalid" 2 "ShortBattery" 1 "ShortGround" 0 "OK" ;
VAL_ 835 PLG_GearMor2Sts 3 "SignalInvalid" 2 "ShortBattery" 1 "ShortGround" 0 "OK" ;
VAL_ 835 PLG_mode 3 "预留" 2 "手动模式（预留）" 1 "车库模式" 0 "正常模式" ;
VAL_ 835 PLG_TBOXUnlockEnableSts 1 "enable" 0 "disable" ;
VAL_ 835 PLG_Fault 1 "Fault" 0 "Default" ;
VAL_ 835 PLG_FaultSts 7 "Fault 7" 6 "Fault 6" 5 "Fault 5" 4 "Fault 4" 3 "Fault 3" 2 "Fault 2" 1 "Fault 1" 0 "Default" ;
VAL_ 774 VBU_BMS_RemainChargingTime 4095 "Invalid" 4094 "init" ;
VAL_ 774 VBU_BMS_Charing_Time 1023 "Invalid" ;
VAL_ 774 VBU_BMS_Charging_Ah 511 "Invalid" ;
VAL_ 774 VBU_BMS_TotalUsed_Ah 1048575 "Invalid" ;
VAL_ 774 VBU_BMS_Charging_Energy 255 "Invalid" ;
VAL_ 528 ACU_CrashStatus 1 "crash" 0 "no crash" ;
VAL_ 528 ACU_AirBagFailSts 3 "Not Used" 2 "lamp flashing（ACU自检）" 1 "lamp on" 0 "lamp off" ;
VAL_ 528 ACU_SBR_Driver 3 "Reserved" 2 "flash and buzzing" 1 "lamp on" 0 "lamp off" ;
VAL_ 528 ACU_SBR_Passenger 3 "Reserved" 2 "flash and buzzing" 1 "lamp on" 0 "lamp off" ;
VAL_ 528 ACU_SBR_RLPassenger 3 "Seat mark lamp on" 2 "flash and buzzing" 1 "lamp on" 0 "lamp off" ;
VAL_ 528 ACU_SBR_MidPassenger 3 "Seat mark lamp on" 2 "flash and buzzing" 1 "lamp on" 0 "lamp off" ;
VAL_ 528 ACU_SBR_RRPassenger 3 "Seat mark lamp on" 2 "flash and buzzing" 1 "lamp on" 0 "lamp off" ;
VAL_ 528 ACU_DrvSeatBeltSWSts 1 "Buckle on" 0 "Buckle off" ;
VAL_ 528 ACU_PsSeatBeltSWSts 1 "Buckle on" 0 "Buckle off" ;
VAL_ 528 ACU_RLPsSeatBeltSWSts 1 "Buckle on" 0 "Buckle off" ;
VAL_ 528 ACU_MidPsSeatBeltSWSts 1 "Buckle on" 0 "Buckle off" ;
VAL_ 528 ACU_RRPsSeatBeltSWSts 1 "Buckle on" 0 "Buckle off" ;
VAL_ 596 AC_SystemSts 1 "ON" 0 "OFF" ;
VAL_ 596 AC_CycleSts 1 "外循环" 0 "内循环" ;
VAL_ 596 AC_EACSts 1 "ON" 0 "OFF" ;
VAL_ 596 AC_AutoModeSts 1 "on" 0 "off" ;
VAL_ 596 AC_APTC_StartStop 3 "Invalid" 2 "Stop" 1 "Start" 0 "Default" ;
VAL_ 596 AC_StartStopEAC 3 "Invalid" 2 "Stop" 1 "Start" 0 "Default" ;
VAL_ 596 AC_WindModeSts 7 "reserved" 6 "reserved" 5 "Blow defrost" 4 "Blow face" 3 "Blow foot&defrost1" 2 "Blow foot" 1 "Blow face&foot" 0 "default" ;
VAL_ 596 AC_BlowingRateSts 7 "Level7" 6 "Level6" 5 "Level5" 4 "Level4" 3 "Level3" 2 "Level2" 1 "Level1" 0 "关闭" ;
VAL_ 596 AC_APTCSWsts 1 "开" 0 "关" ;
VAL_ 596 AC_SysFaultsts 1 "故障" 0 "无故障" ;
VAL_ 596 AC_BatCoolingValve 1 "on" 0 "off" ;
VAL_ 596 AC_ComftCoolingValve 1 "on" 0 "off" ;
VAL_ 596 AC_FdefrostSts 1 "on" 0 "off" ;
VAL_ 1009 DVR_Sdcard_Sts 7 "Custom full（TF卡用户拍摄存储空间不足，请及时清理数据）" 6 "Emergency event full（TF卡紧急录像存储空间不足，请及时清理数据或打开紧急录像循环覆盖开关）" 5 "Full（TF卡可用空间不足，请及时清理数据）" 4 "Abnormal（TF卡异常，请格式化TF卡或者换新卡）" 3 "Capacity unsupported（TF卡容量不支持，请使用8~128GB容量范围的TF卡）" 2 "Filesystem unsupported（TF卡文件系统不支持，请格式化TF卡）" 1 "Not inserted（TF卡未插入，请插入TF卡）" 0 "Normal（TF卡正常）" ;
VAL_ 1009 DVR_DrivingRecord 1 "打开" 0 "关闭" ;
VAL_ 1009 DVR_VideoResolution 3 "保留" 2 "720P@30fps" 1 "1080P@30fps" 0 "保留" ;
VAL_ 1009 DVR_VideoTimeSts 3 "5分钟" 2 "3分钟" 1 "1分钟" 0 "保留" ;
VAL_ 1009 DVR_ShutdownDelay 3 "3分钟" 2 "1分钟" 1 "10秒" 0 "关闭" ;
VAL_ 1009 DVR_VideoCoverageSW 1 "覆盖" 0 "不覆盖" ;
VAL_ 1009 DVR_GSensorSensy 3 "高" 2 "中" 1 "低" 0 "保留" ;
VAL_ 1009 DVR_ParkMonitor 1 "开启" 0 "关闭" ;
VAL_ 1009 DVR_TapeSwitch 1 "开启" 0 "关闭" ;
VAL_ 1009 DVR_HDRSwitch 1 "开启" 0 "关闭" ;
VAL_ 1009 DVR_DriveInfoOverlay 1 "开启" 0 "关闭" ;
VAL_ 1009 DVR_SdcardFormateSts 3 "Reserved" 2 "Succeed" 1 "Fail" 0 "default" ;
VAL_ 1009 DVR_FactoryDefaultSts 3 "Reserved" 2 "Succeed" 1 "Fail" 0 "default" ;
VAL_ 1009 DVR_SystemSts 1 "设备异常" 0 "设备正常" ;
VAL_ 1009 DVR_ControlResult 3 "Remote photo take fail" 2 "Remote photo take succeed" 1 "Remote photo taking" 0 "Invalid" ;
VAL_ 1009 DVR_GsensorCrashStatus 1 "crash" 0 "no crash" ;
VAL_ 1009 DVR_requestWiFiopen 1 "request wifi open" 0 "deault" ;
VAL_ 1009 DVR_LocalTimelapseRecordResult 3 "Timelapse record fail" 2 "Timelapse record succeed" 1 "Timelapse recording" 0 "Invalid" ;
VAL_ 1009 DVR_RemoteControlSts 1 "DVR远程功能开启" 0 "DVR远程功能关闭" ;
VAL_ 676 DSM_EasyEntrySWSts 1 "disable" 0 "enable" ;
VAL_ 676 DSM_DSMHeatSWsts 1 "enable" 0 "disable" ;
VAL_ 676 DSM_GetMemoryRsp_Mirror 3 "调节中断" 2 "调节失败" 1 "调节成功" 0 "Default" ;
VAL_ 676 DSM_GetMemoryRsp_Seat 3 "调节中断" 2 "调节失败" 1 "调节成功" 0 "Default" ;
VAL_ 676 DSM_SLV_DirectionSts 3 "Invalid" 2 "Back" 1 "Forward" 0 "Stop" ;
VAL_ 676 DSM_SHV_DirectionSts 3 "Invalid" 2 "Down" 1 "Up" 0 "Stop" ;
VAL_ 676 DSM_LNV_DirectionSts 3 "Invalid" 2 "Back" 1 "Forward" 0 "Stop" ;
VAL_ 676 DSM_SLV_CalibrationSts 3 "Reserved" 2 "Calibration complete" 1 "Calibration incomplete" 0 "Default" ;
VAL_ 676 DSM_SHV_CalibrationSts 3 "Reserved" 2 "Calibration complete" 1 "Calibration incomplete" 0 "Default" ;
VAL_ 676 DSM_LNV_CalibrationSts 3 "Reserved" 2 "Calibration complete" 1 "Calibration incomplete" 0 "Default" ;
VAL_ 676 DSM_DSLV_MotorfaultSts 1 "fault" 0 "no fault" ;
VAL_ 676 DSM_DSHV_MotorfaultSts 1 "fault" 0 "no fault" ;
VAL_ 676 DSM_DSNV_MotorfaultSts 1 "fault" 0 "no fault" ;
VAL_ 676 DSM_PSMHeatfault 1 "fault" 0 "no fault" ;
VAL_ 676 DSM_PSMHeatSWsts 1 "enable" 0 "disable" ;
VAL_ 676 DSM_DSMHeatfault 1 "fault" 0 "no fault" ;
VAL_ 288 MCU_MotorActualTorque 32767 "Failure" 32766 "Init" ;
VAL_ 288 MCU_MILReq 1 "MIL Lamp ON" 0 "no request" ;
VAL_ 288 MCU_MotorSpeed 65535 "Failure" 65534 "Init" ;
VAL_ 288 MCU_AuthSts 3 "Reserved" 2 "Auth Pass" 1 "Auth Not Pass" 0 "Init(认证正在进行）" ;
VAL_ 288 MCU_OverSpdWarning 1 "Warning" 0 "Not Warning" ;
VAL_ 288 MCU_InverterTempWarning 1 "Warning" 0 "Not Warning" ;
VAL_ 288 MCU_MotorTempWarning 1 "Warning" 0 "Not Warning" ;
VAL_ 288 MCU_OverTemp 1 "MCU请求点亮电机过热灯" 0 "MCU无点亮电机过热灯请求" ;
VAL_ 288 MCU_WorkSts 15 "Invalid" 11 "Hillhold" 10 "DisCharge" 7 "Failure" 6 "Afterrun" 5 "TrqCtl" 4 "nCtlInt" 3 "alOffsetCal" 2 "Standby" 1 "PreCharge" 0 "DrvInit" ;
VAL_ 288 MCU_FaultLevel 7 "Reserved" 6 "Reserved" 5 "Reserved" 4 "Level-4 error" 3 "Level-3 error(High)" 2 "Level-2 error(Limited Drive)" 1 "Level-1 error(Low)" 0 "No Error" ;
VAL_ 288 MCU_FaultLampOn 1 "MCU请求点亮电机故障灯" 0 "MCU无点亮电机故障灯请求" ;
VAL_ 288 MCU_HVLock 3 "预留" 2 "高压断开" 1 "高压闭合" 0 "未检测" ;
VAL_ 290 MCU_MaxAvailableTorque 2047 "Failure" 2046 "Init" ;
VAL_ 290 MCU_MinAvailableTorque 2047 "Failure" 2046 "Init" ;
VAL_ 290 MCU_DeratingTempCoolant 1 "Derating" 0 "Not Derating" ;
VAL_ 290 MCU_damping_En 3 "Reserved" 2 "TCS damping" 1 "active" 0 "Not active" ;
VAL_ 290 MCU_DeratingTrqMin 1 "Derating" 0 "Not Derating" ;
VAL_ 290 MCU_DeratingTrqMax 1 "Derating" 0 "Not Derating" ;
VAL_ 290 MCU_DeratingOvrUdc 1 "Derating" 0 "Not Derating" ;
VAL_ 290 MCU_DeratingUndrUdc 1 "Derating" 0 "Not Derating" ;
VAL_ 290 MCU_DeratingOvrIdc 1 "Derating" 0 "Not Derating" ;
VAL_ 290 MCU_DeratingUndrIdc 1 "Derating" 0 "Not Derating" ;
VAL_ 290 MCU_DeratingTempEm 1 "Derating" 0 "Not Derating" ;
VAL_ 290 MCU_DeratingTempInv 1 "Derating" 0 "Not Derating" ;
VAL_ 290 MCU_MotorTorDerLampReq 1 "Lamp Request" 0 "Not Lamp Request" ;
VAL_ 290 MCU_HVReady 1 "HV Ready" 0 "HV not Ready" ;
VAL_ 290 MCU_DeratingOverSpd 1 "Derating" 0 "Not Derating" ;
VAL_ 289 ESP_VehicleSpeed_Valid 1 "Invalid" 0 "Valid" ;
VAL_ 289 ESP_OFF 1 "On" 0 "Off" ;
VAL_ 289 ESP_ABS_Error 1 "Failure" 0 "No failure" ;
VAL_ 289 ESP_ABS_Intervention 1 "Active" 0 "Not active" ;
VAL_ 289 ESP_VDC_TCS_Error 1 "On" 0 "Off" ;
VAL_ 289 ESP_EBD_Error 1 "On" 0 "Off" ;
VAL_ 289 ESP_VDC_Intervention 1 "Active" 0 "Not active" ;
VAL_ 289 ESP_TCS_Intervention 1 "Active" 0 "Not active" ;
VAL_ 289 ESP_EBD_Intervention 1 "Active" 0 "Not active" ;
VAL_ 289 ESP_HDC_Status 3 "Reserved" 2 "On active braking" 1 "On not active braking" 0 "OFF" ;
VAL_ 289 ESP_HDC_Available 1 "Available" 0 "Not available" ;
VAL_ 289 ESP_EPBMainteDiagmodeActive 1 "Active" 0 "Not active" ;
VAL_ 289 ESP_EPBFailstatus 1 "error in EPB" 0 "No error" ;
VAL_ 289 ESP_EPBStatus 7 "Reserved" 6 "Reserved" 5 "Reserved" 4 "Locking（卡钳正处于夹紧过程中）" 3 "Releasing（卡钳正处于释放过程中）" 2 "Closed（卡钳处于夹紧状态）" 1 "Released（卡钳处于释放状态）" 0 "Undefined（未定义）" ;
VAL_ 289 ESP_VehicleStop 1 "2 or more wheels are standstill" 0 "Vehicle is not standstill" ;
VAL_ 289 ESP_VehicleStop_Valid 1 "Valid" 0 "Invalid" ;
VAL_ 289 ESP_MasterCyPressure_Valid 1 "Valid" 0 "Invalid" ;
VAL_ 289 ESP_WheelCyBrakeForce_Exist 1 "brake force exists" 0 "No brake force" ;
VAL_ 289 ESP_ESPLamp 1 "On（ESP Active）" 0 "Off（ESP Inactive）" ;
VAL_ 289 ESP_AVHstandbyStatus 1 "Standby" 0 "Not standby" ;
VAL_ 289 ESP_AVHActive 1 "Active" 0 "Not active" ;
VAL_ 289 ESP_AVH_availalbe 1 "Available" 0 "Not available" ;
VAL_ 289 ESP_HHC_Available 1 "Available" 0 "Not available" ;
VAL_ 289 ESP_HHCActive 1 "Active" 0 "Not active" ;
VAL_ 289 ESP_HubDiagmodeActive 1 "Active" 0 "Not active" ;
VAL_ 289 ESP_HAZ_Active 1 "Active" 0 "Not active" ;
VAL_ 291 MCU_DC_linkVoltage 1023 "Failure" 1022 "Init" ;
VAL_ 291 MCU_DC_linkCurrent 2047 "Failure" 2046 "Init" ;
VAL_ 291 MCU_InverterTemp 255 "Failure" 254 "Init" ;
VAL_ 291 MCU_MotorTemp 255 "Failure" 254 "Init" ;
VAL_ 292 MCU_DBCTempU 255 "Failure" 0 "Init" ;
VAL_ 292 MCU_DBCTempV 255 "Failure" 0 "Init" ;
VAL_ 292 MCU_DBCTempW 255 "Failure" 0 "Init" ;
VAL_ 292 MCU_RotorTemp 255 "Failure" 254 "Init" ;
VAL_ 292 MCU_MotoroffsetSts 3 "reserved" 2 "Offset_Not_Accurate" 1 "Offset_Accurate" 0 "Init" ;
VAL_ 292 MCU_stGateDrv 3 "DisCharge" 2 "PWMrun" 1 "FreeWheel" 0 "ShortCircuit" ;
VAL_ 292 MCU_Motoroffset 1023 "Failure" 1022 "Init" ;
VAL_ 545 TBOX_BT_Key_valid 3 "预留" 2 "蓝牙已连接" 1 "预留" 0 "蓝牙未连接" ;
VAL_ 545 TBOX_WorkModeCMD 3 "故障" 2 "远程诊断" 1 "远程控制" 0 "默认" ;
VAL_ 545 TBOX_Locate_F 1 "Fault" 0 "No fault" ;
VAL_ 545 TBOX_Networking_F 1 "Fault" 0 "No fault" ;
VAL_ 545 TBOX_Memory_F 1 "Fault" 0 "No fault" ;
VAL_ 545 TBOX_WelcomefuncReq 1 "Request" 0 "Default" ;
VAL_ 545 TBOX_Timer_out 1 "active" 0 "inactive" ;
VAL_ 545 TBOX_FOTA_mode_ALL 7 "Reserved" 6 "Reserved" 5 "Reserved" 4 "到店升级 默认亮屏" 3 "静默升级 屏幕亮度0" 2 "强制升级 默认亮屏" 1 "标准升级 默认亮屏" 0 "default" ;
VAL_ 545 TBOX_ECALL_mode_ALL 1 "active" 0 "deactivate" ;
VAL_ 545 TBOX_DVR_RemoteFunctionCtrl 3 "Reserved" 2 "关闭DVR远程功能" 1 "开启DVR远程功能" 0 "default" ;
VAL_ 545 TBOX_DischargeDepthSet 127 "default" ;
VAL_ 545 TBOX_RemoteCharge_EndHour 31 "Invalid" 30 "Invalid" 29 "Invalid" 28 "Invalid" 27 "Invalid" 26 "Invalid" 25 "Invalid" 24 "Invalid" ;
VAL_ 545 TBOX_RemoteCharge_Full_SetSts 3 "reserved" 2 "充满" 1 "不充满" 0 "default" ;
VAL_ 545 TBOX_RemoteCharge_Endmin 63 "Invalid" 62 "Invalid" 61 "Invalid" 60 "Invalid" ;
VAL_ 545 TBOX_RemoteCharge_wakeup_SetSts 3 "预留" 2 "设置更改唤醒" 1 "开始充电唤醒" 0 "default" ;
VAL_ 599 AC_RemoteAC 7 "reserved" 6 "reserved" 5 "reserved" 4 "RemotDefrost" 3 "RemoteHot" 2 "RemoteCool" 1 "RemoteVentilation" 0 "NoRequest" ;
VAL_ 599 AC_RemoteACFeedback 11 "预留4" 10 "预留3" 9 "预留2" 8 "空调系统故障" 7 "启动太频繁" 6 "空调开启最大时间到" 5 "功率低" 4 "SOC过低" 3 "高压系统故障" 2 "本地状态" 1 "正在远程空调" 0 "未开启" ;
VAL_ 599 AC_OutTemperature_Error 7 "invalid" 6 "reserved" 5 "reserved" 4 "reserved" 3 "reserved" 2 "short to power" 1 "short to groud" 0 "no fault" ;
VAL_ 599 AC_OutTemperature_raw 1023 "invalid" ;
VAL_ 599 AC_VBU_ComfortheatReqLvl 15 "level15" 3 "level3" 2 "level2" 1 "level1" 0 "no request" ;
VAL_ 849 TBOX_BCM_DoorLock_Control_4G 3 "Lock" 2 "FourDoor UnLock" 1 "DiverDoor UnLock" 0 "Default" ;
VAL_ 849 TBOX_BCM_CarLocating 7 "Invalid" 6 "reserved" 5 "reserved" 4 "关闭" 3 "双闪和鸣笛" 2 "鸣笛" 1 "双闪" 0 "Default" ;
VAL_ 849 TBOX_PLG_TrunkunLock 3 "Invalid" 2 "Lock" 1 "UnLock" 0 "Default" ;
VAL_ 849 TBOX_DSM_heatSwitch 3 "Invalid" 2 "Close" 1 "Open" 0 "Default" ;
VAL_ 849 TBOX_PSM_heatSwitch 3 "Invalid" 2 "Close" 1 "Open" 0 "Default" ;
VAL_ 849 TBOX_BCM_DoorLock_Control_BT 3 "Lock" 2 "FourDoor UnLock" 1 "DiverDoor UnLock" 0 "Default" ;
VAL_ 849 TBOX_DSM_Targtemp 63 "defauit" ;
VAL_ 849 TBOX_welcomefuncReqsts 1 "disable" 0 "enable" ;
VAL_ 849 TBOX_Publish_Wakeup 1 "active" 0 "inactive" ;
VAL_ 849 TBOX_PSM_Targtemp 63 "defauit" ;
VAL_ 849 TBOX_RB_Initialization 1 "开始初始化" 0 "无动作" ;
VAL_ 849 TBOX_BCM_PowerON_Request 3 "strat request" 2 "reserved" 1 "resverd" 0 "Default" ;
VAL_ 849 TBOX_BCM_PowerON_limit 1 "Active" 0 "Not active" ;
VAL_ 849 TBOX_RB_Position_Req 255 "Invalid" 254 "默认值" 101 "运行中止" 100 "遮阳帘开度100%" 0 "遮阳帘开度0%" ;
VAL_ 849 TBOX_BCM_FLWindowsControl 3 "Stop" 2 "AutoDown" 1 "AutoUP" 0 "Default" ;
VAL_ 849 TBOX_BCM_FRWindowsControl 3 "Stop" 2 "AutoDown" 1 "AutoUP" 0 "Default" ;
VAL_ 849 TBOX_BCM_RLWindowsControl 3 "Stop" 2 "AutoDown" 1 "AutoUP" 0 "Default" ;
VAL_ 849 TBOX_BCM_RRWindowsControl 3 "Stop" 2 "AutoDown" 1 "AutoUP" 0 "Default" ;
VAL_ 850 TBOX_AC_SystemSet 3 "Reserved" 2 "on" 1 "off" 0 "Default" ;
VAL_ 850 TBOX_AC_Cycle 3 "Reserved" 2 "外循环" 1 "内循环" 0 "Default" ;
VAL_ 850 TBOX_AC_EAC_Control 3 "Reserved" 2 "on" 1 "off" 0 "Default" ;
VAL_ 850 TBOX_AC_AutoMode_Set 3 "Reserved" 2 "off" 1 "on" 0 "Default" ;
VAL_ 850 TBOX_AC_WindMode_Set 7 "Reserved" 6 "Reserved" 5 "Fdefrost" 4 "Blow face" 3 "Blow foot&defrost" 2 "Blow foot" 1 "Blow face&foot" 0 "Default" ;
VAL_ 850 TBOX_AC_FDefrostMode_Set 3 "Reserved" 2 "off" 1 "on" 0 "Default" ;
VAL_ 850 TBOX_AC_BlowingRate_Set 7 "Level7" 6 "Level6" 5 "Level5" 4 "Level4" 3 "Level3" 2 "Level2" 1 "Level1" 0 "Default" ;
VAL_ 850 TBOX_AC_APTCSW_Set 3 "Reserved" 2 "开" 1 "关" 0 "Default" ;
VAL_ 850 TBOX_HU_rebootACK 1 "ACK" 0 "default" ;
VAL_ 850 TBOX_RemotePhotograph 3 "take photos in and outcar" 2 "take photos out-car" 1 "take photos in-car" 0 "Default" ;
VAL_ 850 TBOX_ChargeCtrl_Setsts 3 "预留" 2 "停止充电" 1 "立即充电" 0 "default" ;
VAL_ 850 TBOX_PLG_OpenControl 3 "Reserved" 2 "Close" 1 "Open" 0 "Default" ;
VAL_ 850 TBOX_RemoteCharge_Setsts 3 "Reserved" 2 "开启定时充电模式" 1 "取消定时充电模式" 0 "default" ;
VAL_ 850 TBOX_BCM_FLWindowsVoiControl 15 "预留" 14 "预留" 13 "预留" 12 "车窗停止动作" 11 "关闭车窗" 10 "100%全开" 9 "90%开度" 8 "80%开度" 7 "70%开度" 6 "60%开度" 5 "50%开度" 4 "40%开度" 3 "30%开度" 2 "20%开度" 1 "10%开度" 0 "Default" ;
VAL_ 850 TBOX_BCM_FRWindowsVoiControl 15 "预留" 14 "预留" 13 "预留" 12 "车窗停止动作" 11 "关闭车窗" 10 "100%全开" 9 "90%开度" 8 "80%开度" 7 "70%开度" 6 "60%开度" 5 "50%开度" 4 "40%开度" 3 "30%开度" 2 "20%开度" 1 "10%开度" 0 "Default" ;
VAL_ 850 TBOX_BCM_RLWindowsVoiControl 15 "预留" 14 "预留" 13 "预留" 12 "车窗停止动作" 11 "关闭车窗" 10 "100%全开" 9 "90%开度" 8 "80%开度" 7 "70%开度" 6 "60%开度" 5 "50%开度" 4 "40%开度" 3 "30%开度" 2 "20%开度" 1 "10%开度" 0 "Default" ;
VAL_ 850 TBOX_BCM_RRWindowsVoiControl 15 "预留" 14 "预留" 13 "预留" 12 "车窗停止动作" 11 "关闭车窗" 10 "100%全开" 9 "90%开度" 8 "80%开度" 7 "70%开度" 6 "60%开度" 5 "50%开度" 4 "40%开度" 3 "30%开度" 2 "20%开度" 1 "10%开度" 0 "Default" ;
VAL_ 851 TBOX_VBU_12vChargeReq 1 "Active" 0 "Not active" ;
VAL_ 851 TBOX_VBU_TimeCharge 3 "充电预约已到结束（预留）" 2 "充电预约未到结束（预留）" 1 "start" 0 "No request" ;
VAL_ 851 TBOX_BTKey_valid 1 "蓝牙已连接可用" 0 "蓝牙未连接不可用" ;
VAL_ 851 TBOX_ChargeDepthSet 3 "预留" 2 "长途旅行" 1 "日常行驶" 0 "default" ;
VAL_ 851 TBOX_APS_EPSStrgWhlAngZero 1 "回正" 0 "default" ;
VAL_ 851 TBOX_APS_RequstRemoteParkOut 3 "right side" 2 "left side" 1 "not select" 0 "NoRequest" ;
VAL_ 851 TBOX_APS_QuitRemotePark 1 "Request" 0 "NoRequest" ;
VAL_ 851 TBOX_APS_StartRemoteParkIn 1 "press" 0 "nopress" ;
VAL_ 851 TBOX_APS_PoewerOff_Request 3 "Resvered" 2 "PowerOffReqiest" 1 "NoPowerOffReqiest" 0 "Default" ;
VAL_ 851 TBOX_APS_StraightOut_Request1 3 "Undo 松开停止转向" 2 "Right 右转" 1 "Left 左转" 0 "Default" ;
VAL_ 851 TBOX_APS_StraightOut_Request2 3 "STOP   松开停止驱动" 2 "后退" 1 "前进" 0 "Default" ;
VAL_ 851 TBOX_APS_PowerON_Request 3 "strat request" 2 "reserved" 1 "resverd" 0 "Default" ;
VAL_ 851 TBOX_VBU_RemoteChrgLock 1 "unlock" 0 "no request" ;
VAL_ 851 TBOX_FOTA_mode 1 "FOTA非 PT CAN节点" 0 "Default" ;
VAL_ 851 TBOX_BT_KeyDIstance 7 "预留" 6 "预留" 5 "预留" 4 "无连接" 3 "short_distance" 2 "medium_distance" 1 "long_distance" 0 "invalid" ;
VAL_ 851 TBOX_Ipc_ChargeLight_enable 1 "启动" 0 "关闭" ;
VAL_ 851 TBOX_Ipc_ChrgLock_enable 1 "启动" 0 "关闭" ;
VAL_ 851 TBOX_FOTA_wakeup 7 "Reserved" 6 "Reserved" 5 "Reserved" 4 "到店升级 默认亮屏" 3 "静默升级 屏幕亮度0" 2 "强制升级 默认亮屏" 1 "标准升级 默认亮屏" 0 "default" ;
VAL_ 853 TBOX_TimeSyncSts 1 "start  sync" 0 "Default" ;
VAL_ 1026 TBOX_NM_ALIVE 1 "Active" 0 "Not active" ;
VAL_ 1026 TBOX_NM_RING 1 "Active" 0 "Not active" ;
VAL_ 1026 TBOX_NM_LIMPHOME 1 "Active" 0 "Not active" ;
VAL_ 1026 TBOX_NM_SLEEP_INDICATION 1 "Active" 0 "Not active" ;
VAL_ 1026 TBOX_NM_SLEEP_ACK 1 "Active" 0 "Not active" ;
VAL_ 1028 GW_Tbox_NM_ALIVE 1 "Active" 0 "Not active" ;
VAL_ 1028 GW_Tbox_NM_RING 1 "Active" 0 "Not active" ;
VAL_ 1028 GW_Tbox_NM_LIMPHOME 1 "Active" 0 "Not active" ;
VAL_ 1028 GW_Tbox_NM_SLEEP_Ind 1 "Active" 0 "Not active" ;
VAL_ 1028 GW_Tbox_NM_SLEEP_ACK 1 "Active" 0 "Not active" ;
VAL_ 1299 VBU_BMS_MaxTempNo 0 "invalid" ;
VAL_ 1299 VBU_BMS_MaxTemp 255 "invalid" 252 "init" ;
VAL_ 1299 VBU_BMS_MinTempNo 0 "invalid" ;
VAL_ 1299 VBU_BMS_MinTemp 255 "invalid" 252 "init" ;
VAL_ 1299 VBU_BMS_BattTempDev 255 "invalid" 252 "init" ;
VAL_ 1299 VBU_BMS_CCTemp1 255 "invalid" 252 "init" ;
VAL_ 1299 VBU_BMS_CCTemp2 255 "invalid" 252 "init" ;
VAL_ 1300 VBU_BMS_ModuleBusbarMaxTempNo 0 "invalid" ;
VAL_ 1300 VBU_BMS_ModuleBusbarMaxTemp 255 "invalid" 252 "init" ;
VAL_ 1300 VBU_BMS_ModuleBusbarMinTempNo 0 "invalid" ;
VAL_ 1300 VBU_BMS_ModuleBusbarMinTemp 255 "invalid" 252 "init" ;
VAL_ 1328 VBU_BMS_BattCellNum1Vol 5095 "Invalid" 5093 "Init" ;
VAL_ 1328 VBU_BMS_BattCellNum2Vol 5095 "Invalid" 5093 "Init" ;
VAL_ 1328 VBU_BMS_BattCellNum3Vol 5095 "Invalid" 5093 "Init" ;
VAL_ 1328 VBU_BMS_BattCellNum4Vol 5095 "Invalid" 5093 "Init" ;
VAL_ 1329 VBU_BMS_BattCellNum5Vol 5095 "Invalid" 5093 "Init" ;
VAL_ 1329 VBU_BMS_BattCellNum6Vol 5095 "Invalid" 5093 "Init" ;
VAL_ 1329 VBU_BMS_BattCellNum7Vol 5095 "Invalid" 5093 "Init" ;
VAL_ 1329 VBU_BMS_BattCellNum8Vol 5095 "Invalid" 5093 "Init" ;
VAL_ 1330 VBU_BMS_BattCellNum9Vol 5095 "Invalid" 5093 "Init" ;
VAL_ 1330 VBU_BMS_BattCellNum10Vol 5095 "Invalid" 5093 "Init" ;
VAL_ 1330 VBU_BMS_BattCellNum11Vol 5095 "Invalid" 5093 "Init" ;
VAL_ 1330 VBU_BMS_BattCellNum12Vol 5095 "Invalid" 5093 "Init" ;
VAL_ 1331 VBU_BMS_BattCellNum13Vol 5095 "Invalid" 5093 "Init" ;
VAL_ 1331 VBU_BMS_BattCellNum14Vol 5095 "Invalid" 5093 "Init" ;
VAL_ 1331 VBU_BMS_BattCellNum15Vol 5095 "Invalid" 5093 "Init" ;
VAL_ 1331 VBU_BMS_BattCellNum16Vol 5095 "Invalid" 5093 "Init" ;
VAL_ 1332 VBU_BMS_BattCellNum17Vol 5095 "Invalid" 5093 "Init" ;
VAL_ 1332 VBU_BMS_BattCellNum18Vol 5095 "Invalid" 5093 "Init" ;
VAL_ 1332 VBU_BMS_BattCellNum19Vol 5095 "Invalid" 5093 "Init" ;
VAL_ 1332 VBU_BMS_BattCellNum20Vol 5095 "Invalid" 5093 "Init" ;
VAL_ 1333 VBU_BMS_BattCellNum21Vol 5095 "Invalid" 5093 "Init" ;
VAL_ 1333 VBU_BMS_BattCellNum22Vol 5095 "Invalid" 5093 "Init" ;
VAL_ 1333 VBU_BMS_BattCellNum23Vol 5095 "Invalid" 5093 "Init" ;
VAL_ 1333 VBU_BMS_BattCellNum24Vol 5095 "Invalid" 5093 "Init" ;
VAL_ 1334 VBU_BMS_BattCellNum25Vol 5095 "Invalid" 5093 "Init" ;
VAL_ 1334 VBU_BMS_BattCellNum26Vol 5095 "Invalid" 5093 "Init" ;
VAL_ 1334 VBU_BMS_BattCellNum27Vol 5095 "Invalid" 5093 "Init" ;
VAL_ 1334 VBU_BMS_BattCellNum28Vol 5095 "Invalid" 5093 "Init" ;
VAL_ 1335 VBU_BMS_BattCellNum29Vol 5095 "Invalid" 5093 "Init" ;
VAL_ 1335 VBU_BMS_BattCellNum30Vol 5095 "Invalid" 5093 "Init" ;
VAL_ 1335 VBU_BMS_BattCellNum31Vol 5095 "Invalid" 5093 "Init" ;
VAL_ 1335 VBU_BMS_BattCellNum32Vol 5095 "Invalid" 5093 "Init" ;
VAL_ 1336 VBU_BMS_BattCellNum33Vol 5095 "Invalid" 5093 "Init" ;
VAL_ 1336 VBU_BMS_BattCellNum34Vol 5095 "Invalid" 5093 "Init" ;
VAL_ 1336 VBU_BMS_BattCellNum35Vol 5095 "Invalid" 5093 "Init" ;
VAL_ 1336 VBU_BMS_BattCellNum36Vol 5095 "Invalid" 5093 "Init" ;
VAL_ 1337 VBU_BMS_BattCellNum37Vol 5095 "Invalid" 5093 "Init" ;
VAL_ 1337 VBU_BMS_BattCellNum38Vol 5095 "Invalid" 5093 "Init" ;
VAL_ 1337 VBU_BMS_BattCellNum39Vol 5095 "Invalid" 5093 "Init" ;
VAL_ 1337 VBU_BMS_BattCellNum40Vol 5095 "Invalid" 5093 "Init" ;
VAL_ 1338 VBU_BMS_BattCellNum41Vol 5095 "Invalid" 5093 "Init" ;
VAL_ 1338 VBU_BMS_BattCellNum42Vol 5095 "Invalid" 5093 "Init" ;
VAL_ 1338 VBU_BMS_BattCellNum43Vol 5095 "Invalid" 5093 "Init" ;
VAL_ 1338 VBU_BMS_BattCellNum44Vol 5095 "Invalid" 5093 "Init" ;
VAL_ 1339 VBU_BMS_BattCellNum45Vol 5095 "Invalid" 5093 "Init" ;
VAL_ 1339 VBU_BMS_BattCellNum46Vol 5095 "Invalid" 5093 "Init" ;
VAL_ 1339 VBU_BMS_BattCellNum47Vol 5095 "Invalid" 5093 "Init" ;
VAL_ 1339 VBU_BMS_BattCellNum48Vol 5095 "Invalid" 5093 "Init" ;
VAL_ 1340 VBU_BMS_BattCellNum49Vol 5095 "Invalid" 5093 "Init" ;
VAL_ 1340 VBU_BMS_BattCellNum50Vol 5095 "Invalid" 5093 "Init" ;
VAL_ 1340 VBU_BMS_BattCellNum51Vol 5095 "Invalid" 5093 "Init" ;
VAL_ 1340 VBU_BMS_BattCellNum52Vol 5095 "Invalid" 5093 "Init" ;
VAL_ 1341 VBU_BMS_BattCellNum53Vol 5095 "Invalid" 5093 "Init" ;
VAL_ 1341 VBU_BMS_BattCellNum54Vol 5095 "Invalid" 5093 "Init" ;
VAL_ 1341 VBU_BMS_BattCellNum55Vol 5095 "Invalid" 5093 "Init" ;
VAL_ 1341 VBU_BMS_BattCellNum56Vol 5095 "Invalid" 5093 "Init" ;
VAL_ 1342 VBU_BMS_BattCellNum57Vol 5095 "Invalid" 5093 "Init" ;
VAL_ 1342 VBU_BMS_BattCellNum58Vol 5095 "Invalid" 5093 "Init" ;
VAL_ 1342 VBU_BMS_BattCellNum59Vol 5095 "Invalid" 5093 "Init" ;
VAL_ 1342 VBU_BMS_BattCellNum60Vol 5095 "Invalid" 5093 "Init" ;
VAL_ 1343 VBU_BMS_BattCellNum61Vol 5095 "Invalid" 5093 "Init" ;
VAL_ 1343 VBU_BMS_BattCellNum62Vol 5095 "Invalid" 5093 "Init" ;
VAL_ 1343 VBU_BMS_BattCellNum63Vol 5095 "Invalid" 5093 "Init" ;
VAL_ 1343 VBU_BMS_BattCellNum64Vol 5095 "Invalid" 5093 "Init" ;
VAL_ 1344 VBU_BMS_BattCellNum65Vol 5095 "Invalid" 5093 "Init" ;
VAL_ 1344 VBU_BMS_BattCellNum66Vol 5095 "Invalid" 5093 "Init" ;
VAL_ 1344 VBU_BMS_BattCellNum67Vol 5095 "Invalid" 5093 "Init" ;
VAL_ 1344 VBU_BMS_BattCellNum68Vol 5095 "Invalid" 5093 "Init" ;
VAL_ 1345 VBU_BMS_BattCellNum69Vol 5095 "Invalid" 5093 "Init" ;
VAL_ 1345 VBU_BMS_BattCellNum70Vol 5095 "Invalid" 5093 "Init" ;
VAL_ 1345 VBU_BMS_BattCellNum71Vol 5095 "Invalid" 5093 "Init" ;
VAL_ 1345 VBU_BMS_BattCellNum72Vol 5095 "Invalid" 5093 "Init" ;
VAL_ 1346 VBU_BMS_BattCellNum73Vol 5095 "Invalid" 5093 "Init" ;
VAL_ 1346 VBU_BMS_BattCellNum74Vol 5095 "Invalid" 5093 "Init" ;
VAL_ 1346 VBU_BMS_BattCellNum75Vol 5095 "Invalid" 5093 "Init" ;
VAL_ 1346 VBU_BMS_BattCellNum76Vol 5095 "Invalid" 5093 "Init" ;
VAL_ 1347 VBU_BMS_BattCellNum77Vol 5095 "Invalid" 5093 "Init" ;
VAL_ 1347 VBU_BMS_BattCellNum78Vol 5095 "Invalid" 5093 "Init" ;
VAL_ 1347 VBU_BMS_BattCellNum79Vol 5095 "Invalid" 5093 "Init" ;
VAL_ 1347 VBU_BMS_BattCellNum80Vol 5095 "Invalid" 5093 "Init" ;
VAL_ 1348 VBU_BMS_BattCellNum81Vol 5095 "Invalid" 5093 "Init" ;
VAL_ 1348 VBU_BMS_BattCellNum82Vol 5095 "Invalid" 5093 "Init" ;
VAL_ 1348 VBU_BMS_BattCellNum83Vol 5095 "Invalid" 5093 "Init" ;
VAL_ 1348 VBU_BMS_BattCellNum84Vol 5095 "Invalid" 5093 "Init" ;
VAL_ 1349 VBU_BMS_BattCellNum85Vol 5095 "Invalid" 5093 "Init" ;
VAL_ 1349 VBU_BMS_BattCellNum86Vol 5095 "Invalid" 5093 "Init" ;
VAL_ 1349 VBU_BMS_BattCellNum87Vol 5095 "Invalid" 5093 "Init" ;
VAL_ 1349 VBU_BMS_BattCellNum88Vol 5095 "Invalid" 5093 "Init" ;
VAL_ 1350 VBU_BMS_BattCellNum89Vol 5095 "Invalid" 5093 "Init" ;
VAL_ 1350 VBU_BMS_BattCellNum90Vol 5095 "Invalid" 5093 "Init" ;
VAL_ 1350 VBU_BMS_BattCellNum91Vol 5095 "Invalid" 5093 "Init" ;
VAL_ 1350 VBU_BMS_BattCellNum92Vol 5095 "Invalid" 5093 "Init" ;
VAL_ 1351 VBU_BMS_BattCellNum93Vol 5095 "Invalid" 5093 "Init" ;
VAL_ 1351 VBU_BMS_BattCellNum94Vol 5095 "Invalid" 5093 "Init" ;
VAL_ 1351 VBU_BMS_BattCellNum95Vol 5095 "Invalid" 5093 "Init" ;
VAL_ 1351 VBU_BMS_BattCellNum96Vol 5095 "Invalid" 5093 "Init" ;
VAL_ 1352 VBU_BMS_BattCellNum97Vol 5095 "Invalid" 5093 "Init" ;
VAL_ 1352 VBU_BMS_BattCellNum98Vol 5095 "Invalid" 5093 "Init" ;
VAL_ 1352 VBU_BMS_BattCellNum99Vol 5095 "Invalid" 5093 "Init" ;
VAL_ 1352 VBU_BMS_BattCellNum100Vol 5095 "Invalid" 5093 "Init" ;
VAL_ 1353 VBU_BMS_BattCellNum101Vol 5095 "Invalid" 5093 "Init" ;
VAL_ 1353 VBU_BMS_BattCellNum102Vol 5095 "Invalid" 5093 "Init" ;
VAL_ 1353 VBU_BMS_BattCellNum103Vol 5095 "Invalid" 5093 "Init" ;
VAL_ 1353 VBU_BMS_BattCellNum104Vol 5095 "Invalid" 5093 "Init" ;
VAL_ 1354 VBU_BMS_BattCellNum105Vol 5095 "Invalid" 5093 "Init" ;
VAL_ 1354 VBU_BMS_BattCellNum106Vol 5095 "Invalid" 5093 "Init" ;
VAL_ 1354 VBU_BMS_BattCellNum107Vol 5095 "Invalid" 5093 "Init" ;
VAL_ 1354 VBU_BMS_BattCellNum108Vol 5095 "Invalid" 5093 "Init" ;
VAL_ 1520 VBU_BMS_BattTempSensorNum1 255 "Invalid" 252 "Init" ;
VAL_ 1520 VBU_BMS_BattTempSensorNum2 255 "Invalid" 252 "Init" ;
VAL_ 1520 VBU_BMS_BattTempSensorNum3 255 "Invalid" 252 "Init" ;
VAL_ 1520 VBU_BMS_BattTempSensorNum4 255 "Invalid" 252 "Init" ;
VAL_ 1520 VBU_BMS_BattTempSensorNum5 255 "Invalid" 252 "Init" ;
VAL_ 1520 VBU_BMS_BattTempSensorNum6 255 "Invalid" 252 "Init" ;
VAL_ 1520 VBU_BMS_BattTempSensorNum7 255 "Invalid" 252 "Init" ;
VAL_ 1520 VBU_BMS_BattTempSensorNum8 255 "Invalid" 252 "Init" ;
VAL_ 1521 VBU_BMS_BattTempSensorNum9 255 "Invalid" 252 "Init" ;
VAL_ 1521 VBU_BMS_BattTempSensorNum10 255 "Invalid" 252 "Init" ;
VAL_ 1521 VBU_BMS_BattTempSensorNum11 255 "Invalid" 252 "Init" ;
VAL_ 1521 VBU_BMS_BattTempSensorNum12 255 "Invalid" 252 "Init" ;
VAL_ 1521 VBU_BMS_BattTempSensorNum13 255 "Invalid" 252 "Init" ;
VAL_ 1521 VBU_BMS_BattTempSensorNum14 255 "Invalid" 252 "Init" ;
VAL_ 1521 VBU_BMS_BattTempSensorNum15 255 "Invalid" 252 "Init" ;
VAL_ 1521 VBU_BMS_BattTempSensorNum16 255 "Invalid" 252 "Init" ;
VAL_ 1522 VBU_BMS_BattTempSensorNum17 255 "Invalid" 252 "Init" ;
VAL_ 1522 VBU_BMS_BattTempSensorNum18 255 "Invalid" 252 "Init" ;
VAL_ 1522 VBU_BMS_BattTempSensorNum19 255 "Invalid" 252 "Init" ;
VAL_ 1522 VBU_BMS_BattTempSensorNum20 255 "Invalid" 252 "Init" ;
VAL_ 1522 VBU_BMS_BattTempSensorNum21 255 "Invalid" 252 "Init" ;
VAL_ 1522 VBU_BMS_BattTempSensorNum22 255 "Invalid" 252 "Init" ;
VAL_ 1522 VBU_BMS_BattTempSensorNum23 255 "Invalid" 252 "Init" ;
VAL_ 1522 VBU_BMS_BattTempSensorNum24 255 "Invalid" 252 "Init" ;
VAL_ 1523 VBU_BMS_BattTempSensorNum25 255 "Invalid" 252 "Init" ;
VAL_ 1523 VBU_BMS_BattTempSensorNum26 255 "Invalid" 252 "Init" ;
VAL_ 1523 VBU_BMS_BattTempSensorNum27 255 "Invalid" 252 "Init" ;
VAL_ 1523 VBU_BMS_BattTempSensorNum28 255 "Invalid" 252 "Init" ;
VAL_ 1523 VBU_BMS_BattTempSensorNum29 255 "Invalid" 252 "Init" ;
VAL_ 1523 VBU_BMS_BattTempSensorNum30 255 "Invalid" 252 "Init" ;
VAL_ 1523 VBU_BMS_BattTempSensorNum31 255 "Invalid" 252 "Init" ;
VAL_ 1523 VBU_BMS_BattTempSensorNum32 255 "Invalid" 252 "Init" ;
VAL_ 1524 VBU_BMS_BattTempSensorNum33 255 "Invalid" 252 "Init" ;
VAL_ 1524 VBU_BMS_BattTempSensorNum34 255 "Invalid" 252 "Init" ;
VAL_ 1524 VBU_BMS_BattTempSensorNum35 255 "Invalid" 252 "Init" ;
VAL_ 1524 VBU_BMS_BattTempSensorNum36 255 "Invalid" 252 "Init" ;
VAL_ 1524 VBU_BMS_BattTempSensorNum37 255 "Invalid" 252 "Init" ;
VAL_ 1524 VBU_BMS_BattTempSensorNum38 255 "Invalid" 252 "Init" ;
VAL_ 1524 VBU_BMS_BattTempSensorNum39 255 "Invalid" 252 "Init" ;
VAL_ 1524 VBU_BMS_BattTempSensorNum40 255 "Invalid" 252 "Init" ;
VAL_ 1525 VBU_BMS_BattTempSensorNum41 255 "Invalid" 252 "Init" ;
VAL_ 1525 VBU_BMS_BattTempSensorNum42 255 "Invalid" 252 "Init" ;
VAL_ 1525 VBU_BMS_BattTempSensorNum43 255 "Invalid" 252 "Init" ;
VAL_ 1525 VBU_BMS_BattTempSensorNum44 255 "Invalid" 252 "Init" ;
VAL_ 1525 VBU_BMS_BattTempSensorNum45 255 "Invalid" 252 "Init" ;
VAL_ 1525 VBU_BMS_BattTempSensorNum46 255 "Invalid" 252 "Init" ;
VAL_ 1525 VBU_BMS_BattTempSensorNum47 255 "Invalid" 252 "Init" ;
VAL_ 1525 VBU_BMS_BattTempSensorNum48 255 "Invalid" 252 "Init" ;
VAL_ 1526 VBU_BMS_BattTempSensorNum49 255 "Invalid" 252 "Init" ;
VAL_ 1526 VBU_BMS_BattTempSensorNum50 255 "Invalid" 252 "Init" ;
VAL_ 1526 VBU_BMS_BattTempSensorNum51 255 "Invalid" 252 "Init" ;
VAL_ 1526 VBU_BMS_BattTempSensorNum52 255 "Invalid" 252 "Init" ;
VAL_ 1526 VBU_BMS_BattTempSensorNum53 255 "Invalid" 252 "Init" ;
VAL_ 1526 VBU_BMS_BattTempSensorNum54 255 "Invalid" 252 "Init" ;
VAL_ 1526 VBU_BMS_BattTempSensorNum55 255 "Invalid" 252 "Init" ;
VAL_ 1526 VBU_BMS_BattTempSensorNum56 255 "Invalid" 252 "Init" ;
VAL_ 1527 VBU_BMS_BattTempSensorNum57 255 "Invalid" 252 "Init" ;
VAL_ 1527 VBU_BMS_BattTempSensorNum58 255 "Invalid" 252 "Init" ;
VAL_ 1527 VBU_BMS_BattTempSensorNum59 255 "Invalid" 252 "Init" ;
VAL_ 1527 VBU_BMS_BattTempSensorNum60 255 "Invalid" 252 "Init" ;
VAL_ 1527 VBU_BMS_BattTempSensorNum61 255 "Invalid" 252 "Init" ;
VAL_ 1527 VBU_BMS_BattTempSensorNum62 255 "Invalid" 252 "Init" ;
VAL_ 1527 VBU_BMS_BattTempSensorNum63 255 "Invalid" 252 "Init" ;
VAL_ 1527 VBU_BMS_BattTempSensorNum64 255 "Invalid" 252 "Init" ;
VAL_ 1528 VBU_BMS_BattTempSensorNum65 255 "Invalid" 252 "Init" ;
VAL_ 1528 VBU_BMS_BattTempSensorNum66 255 "Invalid" 252 "Init" ;
VAL_ 1528 VBU_BMS_BattTempSensorNum67 255 "Invalid" 252 "Init" ;
VAL_ 1528 VBU_BMS_BattTempSensorNum68 255 "Invalid" 252 "Init" ;
VAL_ 1528 VBU_BMS_BattTempSensorNum69 255 "Invalid" 252 "Init" ;
VAL_ 1528 VBU_BMS_BattTempSensorNum70 255 "Invalid" 252 "Init" ;
VAL_ 1528 VBU_BMS_BattTempSensorNum71 255 "Invalid" 252 "Init" ;
VAL_ 1528 VBU_BMS_BattTempSensorNum72 255 "Invalid" 252 "Init" ;
